VERSION ""

NS_ :

BS_:

BU_: XXX CAMERA FRONT_RADAR ADRV APRK

BO_ 234 MDPS: 32 XXX
 SG_ BYTE0 : 0|8@1+ (1,0) [0|255] "" XXX
 SG_ BYTE1 : 8|8@1+ (1,0) [0|255] "" XXX
 SG_ BYTE2 : 16|8@1+ (1,0) [0|255] "" XXX
 SG_ BYTE3 : 24|8@1+ (1,0) [0|255] "" XXX
 SG_ BYTE4 : 32|8@1+ (1,0) [0|255] "" XXX
 SG_ BYTE5 : 40|8@1+ (1,0) [0|255] "" XXX
 SG_ BYTE6 : 48|8@1+ (1,0) [0|255] "" XXX
 SG_ BYTE7 : 56|8@1+ (1,0) [0|255] "" XXX
 SG_ BYTE8 : 64|8@1+ (1,0) [0|255] "" XXX
 SG_ BYTE9 : 72|8@1+ (1,0) [0|255] "" XXX
 SG_ BYTE10 : 80|8@1+ (1,0) [0|255] "" XXX
 SG_ BYTE11 : 88|8@1+ (1,0) [0|255] "" XXX
 SG_ BYTE12 : 96|8@1+ (1,0) [0|255] "" XXX
 SG_ BYTE13 : 104|8@1+ (1,0) [0|255] "" XXX
 SG_ BYTE14 : 112|8@1+ (1,0) [0|255] "" XXX
 SG_ BYTE15 : 120|8@1+ (1,0) [0|255] "" XXX
 SG_ BYTE16 : 128|8@1+ (1,0) [0|255] "" XXX
 SG_ BYTE17 : 136|8@1+ (1,0) [0|255] "" XXX
 SG_ BYTE18 : 144|8@1+ (1,0) [0|255] "" XXX
 SG_ BYTE19 : 152|8@1+ (1,0) [0|255] "" XXX
 SG_ BYTE20 : 160|8@1+ (1,0) [0|255] "" XXX
 SG_ BYTE21 : 168|8@1+ (1,0) [0|255] "" XXX
 SG_ BYTE22 : 176|8@1+ (1,0) [0|255] "" XXX
 SG_ BYTE23 : 184|8@1+ (1,0) [0|255] "" XXX
 SG_ BYTE24 : 192|8@1+ (1,0) [0|255] "" XXX
 SG_ BYTE25 : 200|8@1+ (1,0) [0|255] "" XXX
 SG_ BYTE26 : 208|8@1+ (1,0) [0|255] "" XXX
 SG_ BYTE27 : 216|8@1+ (1,0) [0|255] "" XXX
 SG_ BYTE28 : 224|8@1+ (1,0) [0|255] "" XXX
 SG_ BYTE29 : 232|8@1+ (1,0) [0|255] "" XXX
 SG_ BYTE30 : 240|8@1+ (1,0) [0|255] "" XXX
 SG_ BYTE31 : 248|8@1+ (1,0) [0|255] "" XXX

BO_ 293 STEERING_SENSORS: 32 XXX
 SG_ BYTE0 : 0|8@1+ (1,0) [0|255] "" XXX
 SG_ BYTE1 : 8|8@1+ (1,0) [0|255] "" XXX
 SG_ BYTE2 : 16|8@1+ (1,0) [0|255] "" XXX
 SG_ BYTE3 : 24|8@1+ (1,0) [0|255] "" XXX
 SG_ BYTE4 : 32|8@1+ (1,0) [0|255] "" XXX
 SG_ BYTE5 : 40|8@1+ (1,0) [0|255] "" XXX
 SG_ BYTE6 : 48|8@1+ (1,0) [0|255] "" XXX
 SG_ BYTE7 : 56|8@1+ (1,0) [0|255] "" XXX
 SG_ BYTE8 : 64|8@1+ (1,0) [0|255] "" XXX
 SG_ BYTE9 : 72|8@1+ (1,0) [0|255] "" XXX
 SG_ BYTE10 : 80|8@1+ (1,0) [0|255] "" XXX
 SG_ BYTE11 : 88|8@1+ (1,0) [0|255] "" XXX
 SG_ BYTE12 : 96|8@1+ (1,0) [0|255] "" XXX
 SG_ BYTE13 : 104|8@1+ (1,0) [0|255] "" XXX
 SG_ BYTE14 : 112|8@1+ (1,0) [0|255] "" XXX
 SG_ BYTE15 : 120|8@1+ (1,0) [0|255] "" XXX
 SG_ BYTE16 : 128|8@1+ (1,0) [0|255] "" XXX
 SG_ BYTE17 : 136|8@1+ (1,0) [0|255] "" XXX
 SG_ BYTE18 : 144|8@1+ (1,0) [0|255] "" XXX
 SG_ BYTE19 : 152|8@1+ (1,0) [0|255] "" XXX
 SG_ BYTE20 : 160|8@1+ (1,0) [0|255] "" XXX
 SG_ BYTE21 : 168|8@1+ (1,0) [0|255] "" XXX
 SG_ BYTE22 : 176|8@1+ (1,0) [0|255] "" XXX
 SG_ BYTE23 : 184|8@1+ (1,0) [0|255] "" XXX
 SG_ BYTE24 : 192|8@1+ (1,0) [0|255] "" XXX
 SG_ BYTE25 : 200|8@1+ (1,0) [0|255] "" XXX
 SG_ BYTE26 : 208|8@1+ (1,0) [0|255] "" XXX
 SG_ BYTE27 : 216|8@1+ (1,0) [0|255] "" XXX
 SG_ BYTE28 : 224|8@1+ (1,0) [0|255] "" XXX
 SG_ BYTE29 : 232|8@1+ (1,0) [0|255] "" XXX
 SG_ BYTE30 : 240|8@1+ (1,0) [0|255] "" XXX
 SG_ BYTE31 : 248|8@1+ (1,0) [0|255] "" XXX

BO_ 373 TCS: 16 XXX
 SG_ BYTE0 : 0|8@1+ (1,0) [0|255] "" XXX
 SG_ BYTE1 : 8|8@1+ (1,0) [0|255] "" XXX
 SG_ BYTE2 : 16|8@1+ (1,0) [0|255] "" XXX
 SG_ BYTE3 : 24|8@1+ (1,0) [0|255] "" XXX
 SG_ BYTE4 : 32|8@1+ (1,0) [0|255] "" XXX
 SG_ BYTE5 : 40|8@1+ (1,0) [0|255] "" XXX
 SG_ BYTE6 : 48|8@1+ (1,0) [0|255] "" XXX
 SG_ BYTE7 : 56|8@1+ (1,0) [0|255] "" XXX
 SG_ BYTE8 : 64|8@1+ (1,0) [0|255] "" XXX
 SG_ BYTE9 : 72|8@1+ (1,0) [0|255] "" XXX
 SG_ BYTE10 : 80|8@1+ (1,0) [0|255] "" XXX
 SG_ BYTE11 : 88|8@1+ (1,0) [0|255] "" XXX
 SG_ BYTE12 : 96|8@1+ (1,0) [0|255] "" XXX
 SG_ BYTE13 : 104|8@1+ (1,0) [0|255] "" XXX
 SG_ BYTE14 : 112|8@1+ (1,0) [0|255] "" XXX
 SG_ BYTE15 : 120|8@1+ (1,0) [0|255] "" XXX

BO_ 304 GEAR_SHIFTER: 32 XXX
 SG_ BYTE0 : 0|8@1+ (1,0) [0|255] "" XXX
 SG_ BYTE1 : 8|8@1+ (1,0) [0|255] "" XXX
 SG_ BYTE2 : 16|8@1+ (1,0) [0|255] "" XXX
 SG_ BYTE3 : 24|8@1+ (1,0) [0|255] "" XXX
 SG_ BYTE4 : 32|8@1+ (1,0) [0|255] "" XXX
 SG_ BYTE5 : 40|8@1+ (1,0) [0|255] "" XXX
 SG_ BYTE6 : 48|8@1+ (1,0) [0|255] "" XXX
 SG_ BYTE7 : 56|8@1+ (1,0) [0|255] "" XXX
 SG_ BYTE8 : 64|8@1+ (1,0) [0|255] "" XXX
 SG_ BYTE9 : 72|8@1+ (1,0) [0|255] "" XXX
 SG_ BYTE10 : 80|8@1+ (1,0) [0|255] "" XXX
 SG_ BYTE11 : 88|8@1+ (1,0) [0|255] "" XXX
 SG_ BYTE12 : 96|8@1+ (1,0) [0|255] "" XXX
 SG_ BYTE13 : 104|8@1+ (1,0) [0|255] "" XXX
 SG_ BYTE14 : 112|8@1+ (1,0) [0|255] "" XXX
 SG_ BYTE15 : 120|8@1+ (1,0) [0|255] "" XXX
 SG_ BYTE16 : 128|8@1+ (1,0) [0|255] "" XXX
 SG_ BYTE17 : 136|8@1+ (1,0) [0|255] "" XXX
 SG_ BYTE18 : 144|8@1+ (1,0) [0|255] "" XXX
 SG_ BYTE19 : 152|8@1+ (1,0) [0|255] "" XXX
 SG_ BYTE20 : 160|8@1+ (1,0) [0|255] "" XXX
 SG_ BYTE21 : 168|8@1+ (1,0) [0|255] "" XXX
 SG_ BYTE22 : 176|8@1+ (1,0) [0|255] "" XXX
 SG_ BYTE23 : 184|8@1+ (1,0) [0|255] "" XXX
 SG_ BYTE24 : 192|8@1+ (1,0) [0|255] "" XXX
 SG_ BYTE25 : 200|8@1+ (1,0) [0|255] "" XXX
 SG_ BYTE26 : 208|8@1+ (1,0) [0|255] "" XXX
 SG_ BYTE27 : 216|8@1+ (1,0) [0|255] "" XXX
 SG_ BYTE28 : 224|8@1+ (1,0) [0|255] "" XXX
 SG_ BYTE29 : 232|8@1+ (1,0) [0|255] "" XXX
 SG_ BYTE30 : 240|8@1+ (1,0) [0|255] "" XXX
 SG_ BYTE31 : 248|8@1+ (1,0) [0|255] "" XXX

BO_ 864 LFA_BUTTON: 32 XXX
 SG_ LEFT_BLINKER : 0|8@1+ (1,0) [0|255] "" XXX
 SG_ RIGHT_BLINKER : 8|8@1+ (1,0) [0|255] "" XXX
 SG_ LFA_BTN : 16|1@1+ (1,0) [0|1] "" XXX
 SG_ BYTE3 : 24|8@1+ (1,0) [0|255] "" XXX
 SG_ BYTE4 : 32|8@1+ (1,0) [0|255] "" XXX
 SG_ BYTE5 : 40|8@1+ (1,0) [0|255] "" XXX
 SG_ BYTE6 : 48|8@1+ (1,0) [0|255] "" XXX
 SG_ BYTE7 : 56|8@1+ (1,0) [0|255] "" XXX
 SG_ BYTE8 : 64|8@1+ (1,0) [0|255] "" XXX
 SG_ BYTE9 : 72|8@1+ (1,0) [0|255] "" XXX
 SG_ BYTE10 : 80|8@1+ (1,0) [0|255] "" XXX
 SG_ BYTE11 : 88|8@1+ (1,0) [0|255] "" XXX
 SG_ BYTE12 : 96|8@1+ (1,0) [0|255] "" XXX
 SG_ BYTE13 : 104|8@1+ (1,0) [0|255] "" XXX
 SG_ BYTE14 : 112|8@1+ (1,0) [0|255] "" XXX
 SG_ BYTE15 : 120|8@1+ (1,0) [0|255] "" XXX
 SG_ BYTE16 : 128|8@1+ (1,0) [0|255] "" XXX
 SG_ BYTE17 : 136|8@1+ (1,0) [0|255] "" XXX
 SG_ BYTE18 : 144|8@1+ (1,0) [0|255] "" XXX
 SG_ BYTE19 : 152|8@1+ (1,0) [0|255] "" XXX
 SG_ BYTE20 : 160|8@1+ (1,0) [0|255] "" XXX
 SG_ BYTE21 : 168|8@1+ (1,0) [0|255] "" XXX
 SG_ BYTE22 : 176|8@1+ (1,0) [0|255] "" XXX
 SG_ BYTE23 : 184|8@1+ (1,0) [0|255] "" XXX
 SG_ BYTE24 : 192|8@1+ (1,0) [0|255] "" XXX
 SG_ BYTE25 : 200|8@1+ (1,0) [0|255] "" XXX
 SG_ BYTE26 : 208|8@1+ (1,0) [0|255] "" XXX
 SG_ BYTE27 : 216|8@1+ (1,0) [0|255] "" XXX
 SG_ BYTE28 : 224|8@1+ (1,0) [0|255] "" XXX
 SG_ BYTE29 : 232|8@1+ (1,0) [0|255] "" XXX
 SG_ BYTE30 : 240|8@1+ (1,0) [0|255] "" XXX
 SG_ BYTE31 : 248|8@1+ (1,0) [0|255] "" XXX

BO_ 976 EV4_BODY_1: 32 XXX
 SG_ DRIVER_SEATBELT : 0|1@1+ (1,0) [0|1] "" XXX
 SG_ SPEED_REF_1 : 8|16@1+ (0.01,0) [0|655.35] "" XXX
 SG_ BYTE3 : 24|8@1+ (1,0) [0|255] "" XXX
 SG_ BYTE4 : 32|8@1+ (1,0) [0|255] "" XXX
 SG_ BYTE5 : 40|8@1+ (1,0) [0|255] "" XXX
 SG_ BYTE6 : 48|8@1+ (1,0) [0|255] "" XXX
 SG_ BYTE7 : 56|8@1+ (1,0) [0|255] "" XXX
 SG_ BYTE8 : 64|8@1+ (1,0) [0|255] "" XXX
 SG_ BYTE9 : 72|8@1+ (1,0) [0|255] "" XXX
 SG_ BYTE10 : 80|8@1+ (1,0) [0|255] "" XXX
 SG_ BYTE11 : 88|8@1+ (1,0) [0|255] "" XXX
 SG_ BYTE12 : 96|8@1+ (1,0) [0|255] "" XXX
 SG_ BYTE13 : 104|8@1+ (1,0) [0|255] "" XXX
 SG_ BYTE14 : 112|8@1+ (1,0) [0|255] "" XXX
 SG_ BYTE15 : 120|8@1+ (1,0) [0|255] "" XXX
 SG_ BYTE16 : 128|8@1+ (1,0) [0|255] "" XXX
 SG_ BYTE17 : 136|8@1+ (1,0) [0|255] "" XXX
 SG_ BYTE18 : 144|8@1+ (1,0) [0|255] "" XXX
 SG_ BYTE19 : 152|8@1+ (1,0) [0|255] "" XXX
 SG_ BYTE20 : 160|8@1+ (1,0) [0|255] "" XXX
 SG_ BYTE21 : 168|8@1+ (1,0) [0|255] "" XXX
 SG_ BYTE22 : 176|8@1+ (1,0) [0|255] "" XXX
 SG_ BYTE23 : 184|8@1+ (1,0) [0|255] "" XXX
 SG_ BYTE24 : 192|8@1+ (1,0) [0|255] "" XXX
 SG_ BYTE25 : 200|8@1+ (1,0) [0|255] "" XXX
 SG_ BYTE26 : 208|8@1+ (1,0) [0|255] "" XXX
 SG_ BYTE27 : 216|8@1+ (1,0) [0|255] "" XXX
 SG_ BYTE28 : 224|8@1+ (1,0) [0|255] "" XXX
 SG_ BYTE29 : 232|8@1+ (1,0) [0|255] "" XXX
 SG_ BYTE30 : 240|8@1+ (1,0) [0|255] "" XXX
 SG_ BYTE31 : 248|8@1+ (1,0) [0|255] "" XXX

BO_ 979 EV4_BODY_2: 32 XXX
 SG_ DOOR_OPEN_ANY : 0|1@1+ (1,0) [0|1] "" XXX
 SG_ BYTE1 : 8|8@1+ (1,0) [0|255] "" XXX
 SG_ BYTE2 : 16|8@1+ (1,0) [0|255] "" XXX
 SG_ BYTE3 : 24|8@1+ (1,0) [0|255] "" XXX
 SG_ BYTE4 : 32|8@1+ (1,0) [0|255] "" XXX
 SG_ BYTE5 : 40|8@1+ (1,0) [0|255] "" XXX
 SG_ BYTE6 : 48|8@1+ (1,0) [0|255] "" XXX
 SG_ BYTE7 : 56|8@1+ (1,0) [0|255] "" XXX
 SG_ BYTE8 : 64|8@1+ (1,0) [0|255] "" XXX
 SG_ BYTE9 : 72|8@1+ (1,0) [0|255] "" XXX
 SG_ BYTE10 : 80|8@1+ (1,0) [0|255] "" XXX
 SG_ BYTE11 : 88|8@1+ (1,0) [0|255] "" XXX
 SG_ BYTE12 : 96|8@1+ (1,0) [0|255] "" XXX
 SG_ BYTE13 : 104|8@1+ (1,0) [0|255] "" XXX
 SG_ BYTE14 : 112|8@1+ (1,0) [0|255] "" XXX
 SG_ BYTE15 : 120|8@1+ (1,0) [0|255] "" XXX
 SG_ BYTE16 : 128|8@1+ (1,0) [0|255] "" XXX
 SG_ BYTE17 : 136|8@1+ (1,0) [0|255] "" XXX
 SG_ BYTE18 : 144|8@1+ (1,0) [0|255] "" XXX
 SG_ BYTE19 : 152|8@1+ (1,0) [0|255] "" XXX
 SG_ BYTE20 : 160|8@1+ (1,0) [0|255] "" XXX
 SG_ BYTE21 : 168|8@1+ (1,0) [0|255] "" XXX
 SG_ BYTE22 : 176|8@1+ (1,0) [0|255] "" XXX
 SG_ BYTE23 : 184|8@1+ (1,0) [0|255] "" XXX
 SG_ BYTE24 : 192|8@1+ (1,0) [0|255] "" XXX
 SG_ BYTE25 : 200|8@1+ (1,0) [0|255] "" XXX
 SG_ BYTE26 : 208|8@1+ (1,0) [0|255] "" XXX
 SG_ BYTE27 : 216|8@1+ (1,0) [0|255] "" XXX
 SG_ BYTE28 : 224|8@1+ (1,0) [0|255] "" XXX
 SG_ BYTE29 : 232|8@1+ (1,0) [0|255] "" XXX
 SG_ BYTE30 : 240|8@1+ (1,0) [0|255] "" XXX
 SG_ BYTE31 : 248|8@1+ (1,0) [0|255] "" XXX

BO_ 939 RADAR_TRACK_939: 24 XXX
 SG_ BYTE0 : 0|8@1+ (1,0) [0|255] "" XXX
 SG_ BYTE1 : 8|8@1+ (1,0) [0|255] "" XXX
 SG_ BYTE2 : 16|8@1+ (1,0) [0|255] "" XXX
 SG_ BYTE3 : 24|8@1+ (1,0) [0|255] "" XXX
 SG_ BYTE4 : 32|8@1+ (1,0) [0|255] "" XXX
 SG_ BYTE5 : 40|8@1+ (1,0) [0|255] "" XXX
 SG_ BYTE6 : 48|8@1+ (1,0) [0|255] "" XXX
 SG_ BYTE7 : 56|8@1+ (1,0) [0|255] "" XXX
 SG_ BYTE8 : 64|8@1+ (1,0) [0|255] "" XXX
 SG_ BYTE9 : 72|8@1+ (1,0) [0|255] "" XXX
 SG_ BYTE10 : 80|8@1+ (1,0) [0|255] "" XXX
 SG_ BYTE11 : 88|8@1+ (1,0) [0|255] "" XXX
 SG_ BYTE12 : 96|8@1+ (1,0) [0|255] "" XXX
 SG_ BYTE13 : 104|8@1+ (1,0) [0|255] "" XXX
 SG_ BYTE14 : 112|8@1+ (1,0) [0|255] "" XXX
 SG_ BYTE15 : 120|8@1+ (1,0) [0|255] "" XXX
 SG_ BYTE16 : 128|8@1+ (1,0) [0|255] "" XXX
 SG_ BYTE17 : 136|8@1+ (1,0) [0|255] "" XXX
 SG_ BYTE18 : 144|8@1+ (1,0) [0|255] "" XXX
 SG_ BYTE19 : 152|8@1+ (1,0) [0|255] "" XXX
 SG_ BYTE20 : 160|8@1+ (1,0) [0|255] "" XXX
 SG_ BYTE21 : 168|8@1+ (1,0) [0|255] "" XXX
 SG_ BYTE22 : 176|8@1+ (1,0) [0|255] "" XXX
 SG_ BYTE23 : 184|8@1+ (1,0) [0|255] "" XXX

BO_ 53 ACCELERATOR: 32 XXX
 SG_ CHECKSUM_T : 0|16@1+ (1,0) [0|65535] "" XXX
 SG_ COUNTER_T : 16|8@1+ (1,0) [0|255] "" XXX
 SG_ ACCELERATOR_PEDAL : 40|8@1+ (1,0) [0|255] "" XXX
 SG_ GEAR : 192|3@1+ (1,0) [0|7] "" XXX

BO_ 64 GEAR_ALT: 32 XXX
 SG_ CHECKSUM_T : 0|16@1+ (1,0) [0|65535] "" XXX
 SG_ COUNTER_T : 16|8@1+ (1,0) [0|255] "" XXX
 SG_ GEAR : 32|3@1+ (1,0) [0|7] "" XXX

BO_ 69 GEAR: 24 XXX
 SG_ CHECKSUM_T : 0|16@1+ (1,0) [0|65535] "" XXX
 SG_ COUNTER_T : 16|8@1+ (1,0) [0|255] "" XXX
 SG_ GEAR : 44|3@1+ (1,0) [0|7] "" XXX

BO_ 96 ESP_STATUS: 32 XXX
 SG_ CHECKSUM_T : 0|16@1+ (1,0) [0|65535] "" XXX
 SG_ COUNTER_T : 16|8@1+ (1,0) [0|255] "" XXX
 SG_ TRACTION_AND_STABILITY_CONTROL : 42|3@1+ (1,0) [0|63] "" XXX
 SG_ BRAKE_PRESSURE : 128|10@1+ (1,0) [0|65535] "" XXX
 SG_ BRAKE_PRESSED : 148|1@1+ (1,0) [0|3] "" XXX

BO_ 101 BRAKE: 32 XXX
 SG_ CHECKSUM_T : 0|16@1+ (1,0) [0|65535] "" XXX
 SG_ COUNTER_T : 16|8@1+ (1,0) [0|255] "" XXX
 SG_ BRAKE_POSITION : 40|16@1- (1,0) [0|65535] "" XXX
 SG_ BRAKE_PRESSED : 57|1@1+ (1,0) [0|3] "" XXX

BO_ 160 WHEEL_SPEEDS: 24 XXX
 SG_ BYTE0 : 0|8@1+ (1,0) [0|255] "" XXX
 SG_ BYTE1 : 8|8@1+ (1,0) [0|255] "" XXX
 SG_ BYTE2 : 16|8@1+ (1,0) [0|255] "" XXX
 SG_ BYTE3 : 24|8@1+ (1,0) [0|255] "" XXX
 SG_ BYTE4 : 32|8@1+ (1,0) [0|255] "" XXX
 SG_ BYTE5 : 40|8@1+ (1,0) [0|255] "" XXX
 SG_ BYTE6 : 48|8@1+ (1,0) [0|255] "" XXX
 SG_ BYTE7 : 56|8@1+ (1,0) [0|255] "" XXX
 SG_ BYTE8 : 64|8@1+ (1,0) [0|255] "" XXX
 SG_ BYTE9 : 72|8@1+ (1,0) [0|255] "" XXX
 SG_ BYTE10 : 80|8@1+ (1,0) [0|255] "" XXX
 SG_ BYTE11 : 88|8@1+ (1,0) [0|255] "" XXX
 SG_ BYTE12 : 96|8@1+ (1,0) [0|255] "" XXX
 SG_ BYTE13 : 104|8@1+ (1,0) [0|255] "" XXX
 SG_ BYTE14 : 112|8@1+ (1,0) [0|255] "" XXX
 SG_ BYTE15 : 120|8@1+ (1,0) [0|255] "" XXX
 SG_ BYTE16 : 128|8@1+ (1,0) [0|255] "" XXX
 SG_ BYTE17 : 136|8@1+ (1,0) [0|255] "" XXX
 SG_ BYTE18 : 144|8@1+ (1,0) [0|255] "" XXX
 SG_ BYTE19 : 152|8@1+ (1,0) [0|255] "" XXX
 SG_ BYTE20 : 160|8@1+ (1,0) [0|255] "" XXX
 SG_ BYTE21 : 168|8@1+ (1,0) [0|255] "" XXX
 SG_ BYTE22 : 176|8@1+ (1,0) [0|255] "" XXX
 SG_ BYTE23 : 184|8@1+ (1,0) [0|255] "" XXX

BO_ 256 ACCELERATOR_BRAKE_ALT: 24 XXX
 SG_ BYTE0 : 0|8@1+ (1,0) [0|255] "" XXX
 SG_ BYTE1 : 8|8@1+ (1,0) [0|255] "" XXX
 SG_ BYTE2 : 16|8@1+ (1,0) [0|255] "" XXX
 SG_ BYTE3 : 24|8@1+ (1,0) [0|255] "" XXX
 SG_ BYTE4 : 32|8@1+ (1,0) [0|255] "" XXX
 SG_ BYTE5 : 40|8@1+ (1,0) [0|255] "" XXX
 SG_ BYTE6 : 48|8@1+ (1,0) [0|255] "" XXX
 SG_ BYTE7 : 56|8@1+ (1,0) [0|255] "" XXX
 SG_ BYTE8 : 64|8@1+ (1,0) [0|255] "" XXX
 SG_ BYTE9 : 72|8@1+ (1,0) [0|255] "" XXX
 SG_ BYTE10 : 80|8@1+ (1,0) [0|255] "" XXX
 SG_ BYTE11 : 88|8@1+ (1,0) [0|255] "" XXX
 SG_ BYTE12 : 96|8@1+ (1,0) [0|255] "" XXX
 SG_ BYTE13 : 104|8@1+ (1,0) [0|255] "" XXX
 SG_ BYTE14 : 112|8@1+ (1,0) [0|255] "" XXX
 SG_ BYTE15 : 120|8@1+ (1,0) [0|255] "" XXX
 SG_ BYTE16 : 128|8@1+ (1,0) [0|255] "" XXX
 SG_ BYTE17 : 136|8@1+ (1,0) [0|255] "" XXX
 SG_ BYTE18 : 144|8@1+ (1,0) [0|255] "" XXX
 SG_ BYTE19 : 152|8@1+ (1,0) [0|255] "" XXX
 SG_ BYTE20 : 160|8@1+ (1,0) [0|255] "" XXX
 SG_ BYTE21 : 168|8@1+ (1,0) [0|255] "" XXX
 SG_ BYTE22 : 176|8@1+ (1,0) [0|255] "" XXX
 SG_ BYTE23 : 184|8@1+ (1,0) [0|255] "" XXX

BO_ 272 LKAS_ALT: 32 XXX
 SG_ LKA_MODE : 24|4@1+ (1,0) [0|15] "" XXX
 SG_ LKA_ICON : 28|4@1+ (1,0) [0|15] "" XXX
 SG_ TORQUE_REQUEST : 32|11@1- (1,0) [-1024|1023] "" XXX
 SG_ LKA_ASSIST : 43|1@1+ (1,0) [0|1] "" XXX
 SG_ STEER_REQ : 44|1@1+ (1,0) [0|1] "" XXX
 SG_ STEER_MODE : 45|3@1+ (1,0) [0|7] "" XXX
 SG_ HAS_LANE_SAFETY : 48|1@1+ (1,0) [0|1] "" XXX
 SG_ LKA_AVAILABLE : 27|2@1+ (1,0) [0|3] "" XXX
 SG_ CHECKSUM : 0|16@1+ (1,0) [0|65535] "" XXX
 SG_ COUNTER : 16|8@1+ (1,0) [0|255] "" XXX
 SG_ BYTE0 : 0|8@1+ (1,0) [0|255] "" XXX
 SG_ BYTE1 : 8|8@1+ (1,0) [0|255] "" XXX
 SG_ BYTE2 : 16|8@1+ (1,0) [0|255] "" XXX
 SG_ BYTE3 : 24|8@1+ (1,0) [0|255] "" XXX
 SG_ BYTE4 : 32|8@1+ (1,0) [0|255] "" XXX
 SG_ BYTE5 : 40|8@1+ (1,0) [0|255] "" XXX
 SG_ BYTE6 : 48|8@1+ (1,0) [0|255] "" XXX
 SG_ BYTE7 : 56|8@1+ (1,0) [0|255] "" XXX
 SG_ BYTE8 : 64|8@1+ (1,0) [0|255] "" XXX
 SG_ BYTE9 : 72|8@1+ (1,0) [0|255] "" XXX
 SG_ BYTE10 : 80|8@1+ (1,0) [0|255] "" XXX
 SG_ BYTE11 : 88|8@1+ (1,0) [0|255] "" XXX
 SG_ BYTE12 : 96|8@1+ (1,0) [0|255] "" XXX
 SG_ BYTE13 : 104|8@1+ (1,0) [0|255] "" XXX
 SG_ BYTE14 : 112|8@1+ (1,0) [0|255] "" XXX
 SG_ BYTE15 : 120|8@1+ (1,0) [0|255] "" XXX
 SG_ BYTE16 : 128|8@1+ (1,0) [0|255] "" XXX
 SG_ BYTE17 : 136|8@1+ (1,0) [0|255] "" XXX
 SG_ BYTE18 : 144|8@1+ (1,0) [0|255] "" XXX
 SG_ BYTE19 : 152|8@1+ (1,0) [0|255] "" XXX
 SG_ BYTE20 : 160|8@1+ (1,0) [0|255] "" XXX
 SG_ BYTE21 : 168|8@1+ (1,0) [0|255] "" XXX
 SG_ BYTE22 : 176|8@1+ (1,0) [0|255] "" XXX
 SG_ BYTE23 : 184|8@1+ (1,0) [0|255] "" XXX
 SG_ BYTE24 : 192|8@1+ (1,0) [0|255] "" XXX
 SG_ BYTE25 : 200|8@1+ (1,0) [0|255] "" XXX
 SG_ BYTE26 : 208|8@1+ (1,0) [0|255] "" XXX
 SG_ BYTE27 : 216|8@1+ (1,0) [0|255] "" XXX
 SG_ BYTE28 : 224|8@1+ (1,0) [0|255] "" XXX
 SG_ BYTE29 : 232|8@1+ (1,0) [0|255] "" XXX
 SG_ BYTE30 : 240|8@1+ (1,0) [0|255] "" XXX
 SG_ BYTE31 : 248|8@1+ (1,0) [0|255] "" XXX

BO_ 357 ADRV_0x165: 16 XXX
 SG_ BYTE0 : 0|8@1+ (1,0) [0|255] "" XXX
 SG_ BYTE1 : 8|8@1+ (1,0) [0|255] "" XXX
 SG_ BYTE2 : 16|8@1+ (1,0) [0|255] "" XXX
 SG_ BYTE3 : 24|8@1+ (1,0) [0|255] "" XXX
 SG_ BYTE4 : 32|8@1+ (1,0) [0|255] "" XXX
 SG_ BYTE5 : 40|8@1+ (1,0) [0|255] "" XXX
 SG_ BYTE6 : 48|8@1+ (1,0) [0|255] "" XXX
 SG_ BYTE7 : 56|8@1+ (1,0) [0|255] "" XXX
 SG_ BYTE8 : 64|8@1+ (1,0) [0|255] "" XXX
 SG_ BYTE9 : 72|8@1+ (1,0) [0|255] "" XXX
 SG_ BYTE10 : 80|8@1+ (1,0) [0|255] "" XXX
 SG_ BYTE11 : 88|8@1+ (1,0) [0|255] "" XXX
 SG_ BYTE12 : 96|8@1+ (1,0) [0|255] "" XXX
 SG_ BYTE13 : 104|8@1+ (1,0) [0|255] "" XXX
 SG_ BYTE14 : 112|8@1+ (1,0) [0|255] "" XXX
 SG_ BYTE15 : 120|8@1+ (1,0) [0|255] "" XXX

BO_ 576 HBA_0x240: 32 XXX
 SG_ BYTE0 : 0|8@1+ (1,0) [0|255] "" XXX
 SG_ BYTE1 : 8|8@1+ (1,0) [0|255] "" XXX
 SG_ BYTE2 : 16|8@1+ (1,0) [0|255] "" XXX
 SG_ BYTE3 : 24|8@1+ (1,0) [0|255] "" XXX
 SG_ BYTE4 : 32|8@1+ (1,0) [0|255] "" XXX
 SG_ BYTE5 : 40|8@1+ (1,0) [0|255] "" XXX
 SG_ BYTE6 : 48|8@1+ (1,0) [0|255] "" XXX
 SG_ BYTE7 : 56|8@1+ (1,0) [0|255] "" XXX
 SG_ BYTE8 : 64|8@1+ (1,0) [0|255] "" XXX
 SG_ BYTE9 : 72|8@1+ (1,0) [0|255] "" XXX
 SG_ BYTE10 : 80|8@1+ (1,0) [0|255] "" XXX
 SG_ BYTE11 : 88|8@1+ (1,0) [0|255] "" XXX
 SG_ BYTE12 : 96|8@1+ (1,0) [0|255] "" XXX
 SG_ BYTE13 : 104|8@1+ (1,0) [0|255] "" XXX
 SG_ BYTE14 : 112|8@1+ (1,0) [0|255] "" XXX
 SG_ BYTE15 : 120|8@1+ (1,0) [0|255] "" XXX
 SG_ BYTE16 : 128|8@1+ (1,0) [0|255] "" XXX
 SG_ BYTE17 : 136|8@1+ (1,0) [0|255] "" XXX
 SG_ BYTE18 : 144|8@1+ (1,0) [0|255] "" XXX
 SG_ BYTE19 : 152|8@1+ (1,0) [0|255] "" XXX
 SG_ BYTE20 : 160|8@1+ (1,0) [0|255] "" XXX
 SG_ BYTE21 : 168|8@1+ (1,0) [0|255] "" XXX
 SG_ BYTE22 : 176|8@1+ (1,0) [0|255] "" XXX
 SG_ BYTE23 : 184|8@1+ (1,0) [0|255] "" XXX
 SG_ BYTE24 : 192|8@1+ (1,0) [0|255] "" XXX
 SG_ BYTE25 : 200|8@1+ (1,0) [0|255] "" XXX
 SG_ BYTE26 : 208|8@1+ (1,0) [0|255] "" XXX
 SG_ BYTE27 : 216|8@1+ (1,0) [0|255] "" XXX
 SG_ BYTE28 : 224|8@1+ (1,0) [0|255] "" XXX
 SG_ BYTE29 : 232|8@1+ (1,0) [0|255] "" XXX
 SG_ BYTE30 : 240|8@1+ (1,0) [0|255] "" XXX
 SG_ BYTE31 : 248|8@1+ (1,0) [0|255] "" XXX

BO_ 866 CAM_0x362: 32 XXX
 SG_ BYTE0 : 0|8@1+ (1,0) [0|255] "" XXX
 SG_ BYTE1 : 8|8@1+ (1,0) [0|255] "" XXX
 SG_ BYTE2 : 16|8@1+ (1,0) [0|255] "" XXX
 SG_ BYTE3 : 24|8@1+ (1,0) [0|255] "" XXX
 SG_ BYTE4 : 32|8@1+ (1,0) [0|255] "" XXX
 SG_ BYTE5 : 40|8@1+ (1,0) [0|255] "" XXX
 SG_ BYTE6 : 48|8@1+ (1,0) [0|255] "" XXX
 SG_ BYTE7 : 56|8@1+ (1,0) [0|255] "" XXX
 SG_ BYTE8 : 64|8@1+ (1,0) [0|255] "" XXX
 SG_ BYTE9 : 72|8@1+ (1,0) [0|255] "" XXX
 SG_ BYTE10 : 80|8@1+ (1,0) [0|255] "" XXX
 SG_ BYTE11 : 88|8@1+ (1,0) [0|255] "" XXX
 SG_ BYTE12 : 96|8@1+ (1,0) [0|255] "" XXX
 SG_ BYTE13 : 104|8@1+ (1,0) [0|255] "" XXX
 SG_ BYTE14 : 112|8@1+ (1,0) [0|255] "" XXX
 SG_ BYTE15 : 120|8@1+ (1,0) [0|255] "" XXX
 SG_ BYTE16 : 128|8@1+ (1,0) [0|255] "" XXX
 SG_ BYTE17 : 136|8@1+ (1,0) [0|255] "" XXX
 SG_ BYTE18 : 144|8@1+ (1,0) [0|255] "" XXX
 SG_ BYTE19 : 152|8@1+ (1,0) [0|255] "" XXX
 SG_ BYTE20 : 160|8@1+ (1,0) [0|255] "" XXX
 SG_ BYTE21 : 168|8@1+ (1,0) [0|255] "" XXX
 SG_ BYTE22 : 176|8@1+ (1,0) [0|255] "" XXX
 SG_ BYTE23 : 184|8@1+ (1,0) [0|255] "" XXX
 SG_ BYTE24 : 192|8@1+ (1,0) [0|255] "" XXX
 SG_ BYTE25 : 200|8@1+ (1,0) [0|255] "" XXX
 SG_ BYTE26 : 208|8@1+ (1,0) [0|255] "" XXX
 SG_ BYTE27 : 216|8@1+ (1,0) [0|255] "" XXX
 SG_ BYTE28 : 224|8@1+ (1,0) [0|255] "" XXX
 SG_ BYTE29 : 232|8@1+ (1,0) [0|255] "" XXX
 SG_ BYTE30 : 240|8@1+ (1,0) [0|255] "" XXX
 SG_ BYTE31 : 248|8@1+ (1,0) [0|255] "" XXX

BO_ 867 CAM_0x363: 32 XXX
 SG_ BYTE0 : 0|8@1+ (1,0) [0|255] "" XXX
 SG_ BYTE1 : 8|8@1+ (1,0) [0|255] "" XXX
 SG_ BYTE2 : 16|8@1+ (1,0) [0|255] "" XXX
 SG_ BYTE3 : 24|8@1+ (1,0) [0|255] "" XXX
 SG_ BYTE4 : 32|8@1+ (1,0) [0|255] "" XXX
 SG_ BYTE5 : 40|8@1+ (1,0) [0|255] "" XXX
 SG_ BYTE6 : 48|8@1+ (1,0) [0|255] "" XXX
 SG_ BYTE7 : 56|8@1+ (1,0) [0|255] "" XXX
 SG_ BYTE8 : 64|8@1+ (1,0) [0|255] "" XXX
 SG_ BYTE9 : 72|8@1+ (1,0) [0|255] "" XXX
 SG_ BYTE10 : 80|8@1+ (1,0) [0|255] "" XXX
 SG_ BYTE11 : 88|8@1+ (1,0) [0|255] "" XXX
 SG_ BYTE12 : 96|8@1+ (1,0) [0|255] "" XXX
 SG_ BYTE13 : 104|8@1+ (1,0) [0|255] "" XXX
 SG_ BYTE14 : 112|8@1+ (1,0) [0|255] "" XXX
 SG_ BYTE15 : 120|8@1+ (1,0) [0|255] "" XXX
 SG_ BYTE16 : 128|8@1+ (1,0) [0|255] "" XXX
 SG_ BYTE17 : 136|8@1+ (1,0) [0|255] "" XXX
 SG_ BYTE18 : 144|8@1+ (1,0) [0|255] "" XXX
 SG_ BYTE19 : 152|8@1+ (1,0) [0|255] "" XXX
 SG_ BYTE20 : 160|8@1+ (1,0) [0|255] "" XXX
 SG_ BYTE21 : 168|8@1+ (1,0) [0|255] "" XXX
 SG_ BYTE22 : 176|8@1+ (1,0) [0|255] "" XXX
 SG_ BYTE23 : 184|8@1+ (1,0) [0|255] "" XXX
 SG_ BYTE24 : 192|8@1+ (1,0) [0|255] "" XXX
 SG_ BYTE25 : 200|8@1+ (1,0) [0|255] "" XXX
 SG_ BYTE26 : 208|8@1+ (1,0) [0|255] "" XXX
 SG_ BYTE27 : 216|8@1+ (1,0) [0|255] "" XXX
 SG_ BYTE28 : 224|8@1+ (1,0) [0|255] "" XXX
 SG_ BYTE29 : 232|8@1+ (1,0) [0|255] "" XXX
 SG_ BYTE30 : 240|8@1+ (1,0) [0|255] "" XXX
 SG_ BYTE31 : 248|8@1+ (1,0) [0|255] "" XXX

BO_ 868 CAM_0x364: 32 XXX
 SG_ BYTE0 : 0|8@1+ (1,0) [0|255] "" XXX
 SG_ BYTE1 : 8|8@1+ (1,0) [0|255] "" XXX
 SG_ BYTE2 : 16|8@1+ (1,0) [0|255] "" XXX
 SG_ BYTE3 : 24|8@1+ (1,0) [0|255] "" XXX
 SG_ BYTE4 : 32|8@1+ (1,0) [0|255] "" XXX
 SG_ BYTE5 : 40|8@1+ (1,0) [0|255] "" XXX
 SG_ BYTE6 : 48|8@1+ (1,0) [0|255] "" XXX
 SG_ BYTE7 : 56|8@1+ (1,0) [0|255] "" XXX
 SG_ BYTE8 : 64|8@1+ (1,0) [0|255] "" XXX
 SG_ BYTE9 : 72|8@1+ (1,0) [0|255] "" XXX
 SG_ BYTE10 : 80|8@1+ (1,0) [0|255] "" XXX
 SG_ BYTE11 : 88|8@1+ (1,0) [0|255] "" XXX
 SG_ BYTE12 : 96|8@1+ (1,0) [0|255] "" XXX
 SG_ BYTE13 : 104|8@1+ (1,0) [0|255] "" XXX
 SG_ BYTE14 : 112|8@1+ (1,0) [0|255] "" XXX
 SG_ BYTE15 : 120|8@1+ (1,0) [0|255] "" XXX
 SG_ BYTE16 : 128|8@1+ (1,0) [0|255] "" XXX
 SG_ BYTE17 : 136|8@1+ (1,0) [0|255] "" XXX
 SG_ BYTE18 : 144|8@1+ (1,0) [0|255] "" XXX
 SG_ BYTE19 : 152|8@1+ (1,0) [0|255] "" XXX
 SG_ BYTE20 : 160|8@1+ (1,0) [0|255] "" XXX
 SG_ BYTE21 : 168|8@1+ (1,0) [0|255] "" XXX
 SG_ BYTE22 : 176|8@1+ (1,0) [0|255] "" XXX
 SG_ BYTE23 : 184|8@1+ (1,0) [0|255] "" XXX
 SG_ BYTE24 : 192|8@1+ (1,0) [0|255] "" XXX
 SG_ BYTE25 : 200|8@1+ (1,0) [0|255] "" XXX
 SG_ BYTE26 : 208|8@1+ (1,0) [0|255] "" XXX
 SG_ BYTE27 : 216|8@1+ (1,0) [0|255] "" XXX
 SG_ BYTE28 : 224|8@1+ (1,0) [0|255] "" XXX
 SG_ BYTE29 : 232|8@1+ (1,0) [0|255] "" XXX
 SG_ BYTE30 : 240|8@1+ (1,0) [0|255] "" XXX
 SG_ BYTE31 : 248|8@1+ (1,0) [0|255] "" XXX

BO_ 961 RADAR_TRACK_961: 24 XXX
 SG_ BYTE0 : 0|8@1+ (1,0) [0|255] "" XXX
 SG_ BYTE1 : 8|8@1+ (1,0) [0|255] "" XXX
 SG_ BYTE2 : 16|8@1+ (1,0) [0|255] "" XXX
 SG_ BYTE3 : 24|8@1+ (1,0) [0|255] "" XXX
 SG_ BYTE4 : 32|8@1+ (1,0) [0|255] "" XXX
 SG_ BYTE5 : 40|8@1+ (1,0) [0|255] "" XXX
 SG_ BYTE6 : 48|8@1+ (1,0) [0|255] "" XXX
 SG_ BYTE7 : 56|8@1+ (1,0) [0|255] "" XXX
 SG_ BYTE8 : 64|8@1+ (1,0) [0|255] "" XXX
 SG_ BYTE9 : 72|8@1+ (1,0) [0|255] "" XXX
 SG_ BYTE10 : 80|8@1+ (1,0) [0|255] "" XXX
 SG_ BYTE11 : 88|8@1+ (1,0) [0|255] "" XXX
 SG_ BYTE12 : 96|8@1+ (1,0) [0|255] "" XXX
 SG_ BYTE13 : 104|8@1+ (1,0) [0|255] "" XXX
 SG_ BYTE14 : 112|8@1+ (1,0) [0|255] "" XXX
 SG_ BYTE15 : 120|8@1+ (1,0) [0|255] "" XXX
 SG_ BYTE16 : 128|8@1+ (1,0) [0|255] "" XXX
 SG_ BYTE17 : 136|8@1+ (1,0) [0|255] "" XXX
 SG_ BYTE18 : 144|8@1+ (1,0) [0|255] "" XXX
 SG_ BYTE19 : 152|8@1+ (1,0) [0|255] "" XXX
 SG_ BYTE20 : 160|8@1+ (1,0) [0|255] "" XXX
 SG_ BYTE21 : 168|8@1+ (1,0) [0|255] "" XXX
 SG_ BYTE22 : 176|8@1+ (1,0) [0|255] "" XXX
 SG_ BYTE23 : 184|8@1+ (1,0) [0|255] "" XXX

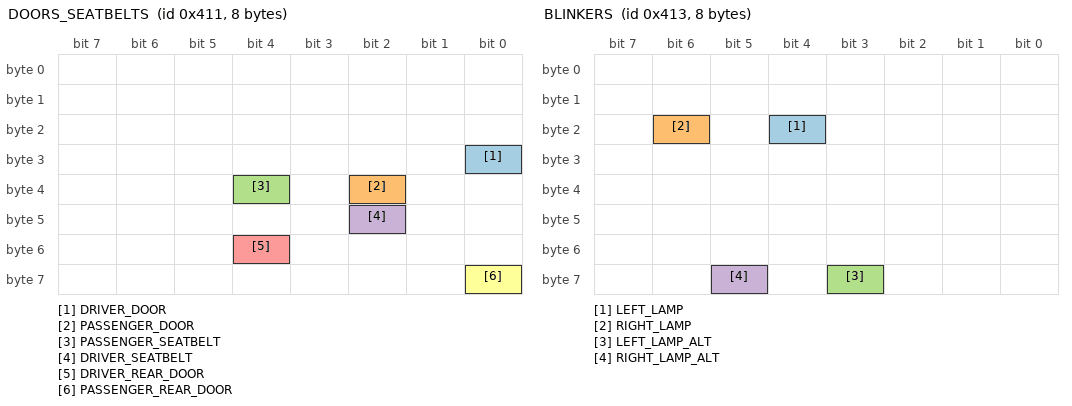
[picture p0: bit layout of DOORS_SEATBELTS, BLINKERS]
BO_ 1041 DOORS_SEATBELTS: 8 XXX
 SG_ DRIVER_DOOR : 24|1@1+ (1,0) [0|1] "" XXX
 SG_ PASSENGER_DOOR : 34|1@0+ (1,0) [0|1] "" XXX
 SG_ PASSENGER_SEATBELT : 36|1@0+ (1,0) [0|1] "" XXX
 SG_ DRIVER_SEATBELT : 42|1@0+ (1,0) [0|1] "" XXX
 SG_ DRIVER_REAR_DOOR : 52|1@0+ (1,0) [0|1] "" XXX
 SG_ PASSENGER_REAR_DOOR : 56|1@0+ (1,0) [0|1] "" XXX

CM_ "AUTOGENERATED FILE, DO NOT EDIT";
CM_ "Imported file _hyundai_canfd_common.dbc starts here";
CM_ BO_ 676 "Contains signals with detailed lane line information. Used by ADAS ECU on HDA 2 vehicles to operate LFA.";

CM_ SG_ 80 HAS_LANE_SAFETY "If 0, hides LKAS 'Lane Safety' menu from vehicle settings";
CM_ SG_ 676 LEFT_LANE_LINE "Left lane line confidence";
CM_ SG_ 676 RIGHT_LANE_LINE "Right lane line confidence";

CM_ "hyundai_canfd.dbc starts here";

CM_ SG_ 96 BRAKE_PRESSURE "User applied brake pedal pressure. Ramps from computer applied pressure on falling edge of cruise. Cruise cancels if !=0";
CM_ SG_ 101 BRAKE_POSITION "User applied brake pedal position, max is ~700. Signed on some vehicles";
CM_ SG_ 203 ADAS_ActvACISta "ADAS Active AngleControlInterface State";
CM_ SG_ 203 ADAS_ActvACILvl2Sta "ADAS Active AngleControlInterface Level 2 State";
CM_ SG_ 203 ADAS_StrAnglReqVal "(LFA) ADAS Steering Angle Request Value; Capped at 119.9;";
CM_ SG_ 203 ADAS_ACIAnglTqRedcGainVal "(LFA) ADAS AngleControlInterface Angle Torque Reduction Gain Value";
CM_ SG_ 203 FCA_ESA_ActvSta "FCA_ESA Active State";
CM_ SG_ 203 FCA_ESA_TqBstGainVal "FCA_ESA Torque Boost Gain Value";
CM_ BO_ 272 "Alternative LKAS message, used on cars such as 2023 Ioniq 6, 2nd gen Kona. Matches LKAS except size is 32 bytes";
CM_ SG_ 272 LKA_AVAILABLE "Angle control cars: 3 when LKA is generally available, goes to 0 during changes with LFA";
CM_ SG_ 272 ADAS_StrAnglReqVal "(LKAS) ADAS Steering Angle Request Value; Capped at 176.7; tracks MDPS->STEERING_ANGLE when not engaged, not STEERING_SENSORS->STEERING_ANGLE";
CM_ SG_ 272 ADAS_ACIAnglTqRedcGainVal "(LKAS) ADAS AngleControlInterface Angle Torque Reduction Gain Value";
CM_ BO_ 282 "Sent by the camera containing DAW (Driver Attention Warning) information and information about HBA (High Beam Assist).";
CM_ SG_ 282 FR_CMR_Crc1Val "The data area for CRC calculation is based on the data length (DLC) of the message DB. The CRC shall be calculated over the entire data block (excluding the CRC bytes) including the user data, alive counter and Data ID - CRC Polynomial (0x1021) , In";
CM_ SG_ 282 FR_CMR_AlvCnt1Val "For the first transmission request for a data element the counter shall be initialized with 0 and shall be incremented by 1 for every subsequent send request. When the counter reaches the maximum value(0xFF), then it shall restart with 0 for the next s";
CM_ SG_ 282 HBA_SysOptSta "HBA System Option Information to Lamp Controller";
CM_ SG_ 282 HBA_SysSta "This signal indicates the status of High Beam Assist system.";
CM_ SG_ 282 HBA_IndLmpReq "HBA System Indicator Lamp Status";
CM_ SG_ 282 FCA_Equip_MFC "FCA Sensor Type";
CM_ SG_ 282 HBA_OptUsmSta "HBA Option USM Status";
CM_ SG_ 282 DAW_LVDA_PUDis "Message for displaying LVDA(Leading Vehicle Departure Alert) Warning";
CM_ SG_ 282 DAW_LVDA_OptUsmSta "LVDA USM state";
CM_ SG_ 282 DAW_OptUsmSta "This signal represents the lastest DAW ON/OFF value of USM.";
CM_ SG_ 282 DAW_SysSta "This signal represents Attention Assist System Status or Attention Level.";
CM_ SG_ 282 DAW_WrnMsgSta "0x1 value requests DAW Rest recommend warning message popup at CLU. 0x2 value requests HDA/LFA Hands-Off call at TMS.";
CM_ SG_ 282 DAW_TimeRstReq "This signal requests CLU 'Last Break Time' Reset. DAW send '0x1' when detecting driver's rest.";
CM_ SG_ 282 DAW_SnstvtyModRetVal "This signal represents the feedback value of the current ADAS warning timing.";
CM_ SG_ 282 FR_CMR_SCCEquipSta "This signal indicates equipment for SCC";
CM_ SG_ 282 FR_CMR_ReqADASMapMsgVal "This signal indicates an ADAS map message request from FR_CMR to H_U. Each bit indicates the request messages as follows. - Bit 0 : H_U_NAVI_V2_STUB_E - Bit 1 : HU_NAVI_V2_PROSHORT_E_00 (곡률) - Bit 2 : HU_NAVI_V2_PROSHORT_E_00 (곡률 ???�보)";
CM_ SG_ 282 FR_CMR_SwVer1Val "This signal indicates a major version of FR_CMR software. If FR_CMR software version is A.00, 'A' and '00' mean major and minor version respectively.";
CM_ SG_ 282 FR_CMR_SwVer2Val "This signal indicates a minor version of FR_CMR software. If FR_CMR software version is A.00, 'A' and '00' mean major and minor version respectively.";
CM_ SG_ 298 NEW_SIGNAL_4 "todo: figure out why always set to 9";
CM_ SG_ 352 SET_ME_9 "has something to do with AEB settings";
CM_ SG_ 373 ACCEnable "Likely a copy of CAN's TCS13->ACCEnable";
CM_ SG_ 373 DriverBraking "Likely derived from BRAKE->BRAKE_POSITION";
CM_ SG_ 373 DriverBrakingLowSens "Higher threshold version of DriverBraking";
CM_ SG_ 373 PROBABLY_EQUIP "aeb equip?";
CM_ SG_ 416 VSetDis "set speed in display units";
CM_ BO_ 437 "Sent by the camera containing lane and lead information.";
CM_ SG_ 437 FR_CMR_Crc3Val "The data area for CRC calculation is based on the data length (DLC) of the message DB. The CRC shall be calculated over the entire data block (excluding the CRC bytes) including the user data, alive counter and Data ID - CRC Polynomial (0x1021) , In";
CM_ SG_ 437 FR_CMR_AlvCnt3Val "For the first transmission request for a data element the counter shall be initialized with 0 and shall be incremented by 1 for every subsequent send request. When the counter reaches the maximum value(0xFF), then it shall restart with 0 for the next s";
CM_ SG_ 437 Info_LftLnQualSta "This signal indicates the quality of left line.";
CM_ SG_ 437 Info_LftLnDptSta "This signal indicates the lane departure status of left line.";
CM_ SG_ 437 Info_LftLnPosVal "This signal outputs the position of left line from camera center.";
CM_ SG_ 437 Info_LftLnHdingAnglVal "This signal outputs the heading angle of left line.";
CM_ SG_ 437 Info_LftLnCvtrVal "This signal outputs the curvature of left line.";
CM_ SG_ 437 Info_RtLnQualSta "This signal indicates the quality of right line.";
CM_ SG_ 437 Info_RtLnDptSta "This signal indicates the lane departure status of right line.";
CM_ SG_ 437 Info_RtLnPosVal "This signal outputs the position of right line from camera center.";
CM_ SG_ 437 Info_RtLnHdingAnglVal "This signal outputs the heading angle of right line.";
CM_ SG_ 437 Info_RtLnCvtrVal "This signal outputs the curvature of right line.";
CM_ SG_ 437 ID_CIPV "Valid Object = 1 to 255 - ID detected by front camera can vary depending on vehicle environment. - Additional logic would be required to apply this signal for ISG.";
CM_ SG_ 437 Relative_Velocity "+ : Preceding, - : Oncoming - Velocity detected by front camera can vary depending on vehicle environment. - Additional logic would be required to apply this signal for ISG. - Confirmaiton by Autonomous Driving Engineering Team is required to use ID_C";
CM_ SG_ 480 NEW_SIGNAL_5 "todo: figure out why always set to 1";
CM_ BO_ 506 "Sent by the camera containing speed limit information. ISLW stands for Intelligent Speed Limit Warning, and ISLA is Intelligent Speed Limit Assist. it also contains road sign information.";
CM_ SG_ 506 FR_CMR_Crc2Val "The data area for CRC calculation is based on the data length (DLC) of the message DB.The CRC shall be calculated over the entire data block (excluding the CRC bytes) including the user data, alive counter and Data ID - CRC Polynomial (0x1021) , In";
CM_ SG_ 506 FR_CMR_AlvCnt2Val "For the first transmission request for a data element the counter shall be initialized with 0 and shall be incremented by 1 for every subsequent send request. When the counter reaches the maximum value(0xFF), then it shall restart with 0 for the next s";
CM_ SG_ 506 ISLW_OptUsmSta "ISLW option information";
CM_ SG_ 506 ISLW_SysSta "Validity of ISLW information";
CM_ SG_ 506 ISLW_NoPassingInfoDis "This signal indicates additional information of ISLW. For example no passing.";
CM_ SG_ 506 ISLW_OvrlpSignDis "indicates presence of Overlap sign";
CM_ SG_ 506 ISLW_SpdCluMainDis "Main Speed Information for cluster display in main page(0x1~0xFCH: 1*(HEX VALUE) [KPH or MPH :Reference signal is  CF_Clu_SPEED_UNIT of CLU])";
CM_ SG_ 506 ISLW_SpdNaviMainDis "Main Speed information for navigation display in main page(0x1~0xFCH: 1*(HEX VALUE) [KPH or MPH :Reference signal is  Navi_ISLW_SpdUnit of Navigation)";
CM_ SG_ 506 ISLW_SubCondinfoSta1 "Indicates 1st conditional traffic sign status";
CM_ SG_ 506 ISLW_SubCondinfoSta2 "Indicates 2nd conditional traffic sign status";
CM_ SG_ 506 ISLW_SpdCluSubMainDis "Main Speed Information for cluster display in ISLW detail page";
CM_ SG_ 506 ISLW_SpdCluDisSubCond1 "Indicates conditional speed limit/no passing of 1st conditional traffic sign for Cluster in ISLW Detail page";
CM_ SG_ 506 ISLW_SpdCluDisSubCond2 "Indicates conditional speed limit/no passing of 2nd conditional traffic sign for Cluster in ISLW Detail page";
CM_ SG_ 506 ISLW_SpdNaviSubMainDis "Main Speed Information for NAVI display in ISLW detail page";
CM_ SG_ 506 ISLW_SpdNaviDisSubCond1 "Indicates conditional speed limit/no passing of 1st conditional traffic sign for NAVI in ISLW Detail page";
CM_ SG_ 506 ISLW_SpdNaviDisSubCond2 "Indicates conditional speed limit/no passing of 2nd conditional traffic sign for NAVI in ISLW Detail page";
CM_ SG_ 506 ISLA_SpdwOffst "This is a ISLA speed with offset to change the set speed of MSLA/CC/SCC.Unit (kph or mph) refers to cluster signal: CLU_SpdUnitTyp@CLU_01_20ms";
CM_ SG_ 506 ISLA_SwIgnoreReq "This is a signal requesting to ignore the -(SET) or +(SET) switch input of the driver.";
CM_ SG_ 506 ISLA_SpdChgReq "This is a signal requesting to change the set speed of MSLA/CC/SCC to the ISLA speed.";
CM_ SG_ 506 ISLA_SpdWrn "This is a warning signal when VANZ exceeds the speed limit.";
CM_ SG_ 506 ISLA_IcyWrn "This is a warning signal when the snow or ice sign is recognized when it is less than 4 'C.";
CM_ SG_ 506 ISLA_SymFlashMod "This is a signal for the flashing mode of the symbol.";
CM_ SG_ 506 ISLA_Popup "This is a signal for ISLA pop-up.";
CM_ SG_ 506 ISLA_OptUsmSta "This is a ISLA option USM signal set by the driver.";
CM_ SG_ 506 ISLA_OffstUsmSta "This is a signal for offset speed set by the driver. Unit (kph or mph) refers to cluster signal: CLU_SpdUnitTyp@CLU_01_20ms";
CM_ SG_ 506 ISLA_AutoUsmSta "This is a signal for ISLA AUTO USM set by the driver.";
CM_ SG_ 506 ISLA_Cntry "This is a signal for categorizing countries";
CM_ SG_ 506 ISLA_AddtnlSign "This is a signal for additional sign";
CM_ SG_ 506 ISLA_SchoolZone "This is a signal for School Zone";
CM_ SG_ 687 HOD_Dir_Status "This signal indicates the status of hands on/off";
CM_ BO_ 698 "Sent by the camera containing information about vehicles in front of us. IFS stands for Intelligent Front-lighting System, and this signal provides the information necessary for it to operate.";
CM_ SG_ 698 FR_CMR_Crc4Val "The data area for CRC calculation is based on the data length (DLC) of the message DB. The CRC shall be calculated over the entire data block (excluding the CRC bytes) including the user data, alive counter and Data ID - CRC Polynomial (0x1021) , In";
CM_ SG_ 698 FR_CMR_AlvCnt4Val "For the first transmission request for a data element the counter shall be initialized with 0 and shall be incremented by 1 for every subsequent send request. When the counter reaches the maximum value(0xFF), then it shall restart with 0 for the next s";
CM_ SG_ 698 IFSref_FR_CMR_Sta "This is IFS system status needed for operate the IFS function of headlamp highbeam";
CM_ SG_ 698 IFSref_VehNumVal "This is number of vehicles detected from camera";
CM_ SG_ 698 IFSref_ILLAmbtSta "This signal is status of the ambient brightness 0x0 is bright condition (HighBeam off), 0x1 is dark condition (None)";
CM_ SG_ 698 IFSref_VehLftAngl1Val "This is left angle of vehicle 1 Deg = (HEX)*0.1-25";
CM_ SG_ 698 IFSref_VehRtAngl1Val "This is right angle of vehicle 1 Deg = (HEX)*0.1-25";
CM_ SG_ 698 IFSref_VehLftAngl2Val "This is left angle of vehicle 2 Deg = (HEX)*0.1-25";
CM_ SG_ 698 IFSref_VehDst1Val "IFSref_VehicleDistance1Value";
CM_ SG_ 698 IFSref_VehRtAngl2Val "This is right angle of vehicle 2 Deg = (HEX)*0.1-25";
CM_ SG_ 698 IFSref_VehLftAngl3Val "This is left angle of vehicle 3 Deg = (HEX)*0.1-25";
CM_ SG_ 698 IFSref_VehRtAngl3Val "This is right angle of vehicle 3 Deg = (HEX)*0.1-25";
CM_ SG_ 698 IFSref_VehLftAngl4Val "This is left angle of vehicle 4 Deg = (HEX)*0.1-25";
CM_ SG_ 698 IFSref_VehRtAngl4Val "This is right angle of vehicle 4 Deg = (HEX)*0.1-25";
CM_ SG_ 698 IFSref_VehLftAngl5Val "This is left angle of vehicle 5 Deg = (HEX)*0.1-25";
CM_ SG_ 698 IFSref_VehRtAngl5Val "This is right angle of vehicle 5 Deg = (HEX)*0.1-25";
CM_ SG_ 698 IFSref_VehLftAngl6Val "This is left angle of vehicle 6 Deg = (HEX)*0.1-25";
CM_ SG_ 698 IFSref_VehRtAngl6Val "This is right angle of vehicle 6 Deg = (HEX)*0.1-25";
CM_ SG_ 698 IFSref_VehLftAngl7Val "This is left angle of vehicle 7 Deg = (HEX)*0.1-25";
CM_ SG_ 698 IFSref_VehRtAngl7Val "This is right angle of vehicle 7 Deg = (HEX)*0.1-25";
CM_ SG_ 698 IFSref_VehLftAngl8Val "This is left angle of vehicle 8 Deg = (HEX)*0.1-25";
CM_ SG_ 698 IFSref_VehRtAngl8Val "This is right angle of vehicle 8 Deg = (HEX)*0.1-25";
CM_ SG_ 698 IFSref_VehLftAngl9Val "This is left angle of vehicle 9 Deg = (HEX)*0.1-25";
CM_ SG_ 698 IFSref_VehRtAngl9Val "This is right angle of vehicle 9 Deg = (HEX)*0.1-25";
CM_ SG_ 698 IFSref_VehLftAngl10Val "This is left angle of vehicle 10 Deg = (HEX)*0.1-25";
CM_ SG_ 698 IFSref_VehRtAngl10Val "This is right angle of vehicle 10 Deg = (HEX)*0.1-25";
CM_ SG_ 698 IFSref_VehDst2Val "IFSref_VehicleDistance2Value";
CM_ SG_ 698 IFSref_VehDst3Val "IFSref_VehicleDistance3Value";
CM_ SG_ 698 IFSref_VehDst4Val "IFSref_VehicleDistance4Value";
CM_ SG_ 698 IFSref_VehDst5Val "IFSref_VehicleDistance5Value";
CM_ SG_ 698 IFSref_VehDst6Val "IFSref_VehicleDistance6Value";
CM_ SG_ 698 IFSref_VehDst7Val "IFSref_VehicleDistance7Value";
CM_ SG_ 698 IFSref_VehDst8Val "IFSref_VehicleDistance8Value";
CM_ SG_ 698 IFSref_VehDst9Val "IFSref_VehicleDistance9Value";
CM_ SG_ 698 IFSref_VehDst10Val "IFSref_VehicleDistance10Value";
CM_ SG_ 736 MAX_SPEED "Display units. Restricts car from driving above this speed unless accelerator pedal is depressed beyond pressure point";
CM_ BO_ 866 "Contains signals with detailed lane line information. Used by ADAS ECU on HDA 2 vehicles to operate LFA. Used on cars that use message 272.";
CM_ SG_ 866 LEFT_LANE_LINE "Left lane line confidence";
CM_ SG_ 866 RIGHT_LANE_LINE "Right lane line confidence";
CM_ SG_ 961 COUNTER_ALT "only increments on change";

CM_ BO_ 1043 "Lamp signals do not seem universal on cars that use LKAS_ALT, but stalk signals do.";
CM_ SG_ 1043 COUNTER_ALT "only increments on change";
CM_ SG_ 1043 USE_ALT_LAMP "likely 1 on cars that use alt lamp signals";
VAL_ 53 GEAR 0 "P" 5 "D" 6 "N" 7 "R";
VAL_ 64 GEAR 0 "P" 5 "D" 6 "N" 7 "R";
VAL_ 69 GEAR 0 "P" 5 "D" 6 "N" 7 "R";
VAL_ 96 TRACTION_AND_STABILITY_CONTROL 0 "On" 5 "Limited" 1 "Off";
VAL_ 234 LKA_FAULT 0 "ok" 1 "lka fault";
VAL_ 272 LKA_MODE 1 "warning only" 2 "assist" 6 "off";
VAL_ 272 LKA_ICON 0 "hidden" 1 "grey" 2 "green" 3 "flashing green";
VAL_ 272 LKAS_ANGLE_ACTIVE 0 "off" 1 "not active" 2 "active";
VAL_ 373 ACCEnable 0 "SCC ready" 1 "SCC temp fault" 2 "SCC permanent fault" 3 "SCC permanent fault, communication issue";
VAL_ 304 GEAR 1 "P" 2 "R" 3 "N" 4 "D";
VAL_ 976 DRIVER_SEATBELT 0 "Unlatched" 1 "Latched";
VAL_ 976 PASSENGER_SEATBELT 0 "Unlatched" 1 "Latched";
VAL_ 979 DOOR_OPEN_ANY 0 "Opened" 1 "Closed";
VAL_ 1041 DRIVER_DOOR 0 "Closed" 1 "Opened";
VAL_ 1041 PASSENGER_DOOR 0 "Closed" 1 "Opened";
VAL_ 1041 PASSENGER_SEATBELT 0 "Unlatched" 1 "Latched";
VAL_ 1041 DRIVER_SEATBELT 0 "Unlatched" 1 "Latched";
VAL_ 1041 DRIVER_REAR_DOOR 0 "Closed" 1 "Opened";
VAL_ 1041 PASSENGER_REAR_DOOR 0 "Closed" 1 "Opened";

BO_ 426 CRUISE_BUTTONS_ALT: 16 XXX
 SG_ CHECKSUM_T : 0|16@1+ (1,0) [0|65535] "" XXX
 SG_ COUNTER_T : 16|8@1+ (1,0) [0|255] "" XXX
 SG_ NEW_SIGNAL_1 : 24|4@1+ (1,0) [0|15] "" XXX
 SG_ SET_ME_1 : 28|2@1+ (1,0) [0|3] "" XXX
 SG_ DISTANCE_UNIT : 30|1@1+ (1,0) [0|1] "" XXX
 SG_ NEW_SIGNAL_2 : 31|3@1+ (1,0) [0|7] "" XXX
 SG_ ADAPTIVE_CRUISE_MAIN_BTN : 34|1@1+ (1,0) [0|1] "" XXX
 SG_ NEW_SIGNAL_3 : 35|1@1+ (1,0) [0|1] "" XXX
 SG_ CRUISE_BUTTONS : 36|3@1+ (1,0) [0|4] "" XXX
 SG_ LDA_BTN : 39|1@1+ (1,0) [0|1] "" XXX
 SG_ NEW_SIGNAL_4 : 40|1@1+ (1,0) [0|1] "" XXX
 SG_ NORMAL_CRUISE_MAIN_BTN : 41|1@1+ (1,0) [0|1] "" XXX
 SG_ NEW_SIGNAL_5 : 42|2@1+ (1,0) [0|3] "" XXX
 SG_ SET_ME_2 : 44|3@1+ (1,0) [0|7] "" XXX
 SG_ NEW_SIGNAL_6 : 47|1@1+ (1,0) [0|1] "" XXX
 SG_ BYTE6 : 48|8@1+ (1,0) [0|255] "" XXX
 SG_ BYTE7 : 56|8@1+ (1,0) [0|255] "" XXX
 SG_ BYTE8 : 64|8@1+ (1,0) [0|255] "" XXX
 SG_ BYTE9 : 72|8@1+ (1,0) [0|255] "" XXX
 SG_ BYTE10 : 80|8@1+ (1,0) [0|255] "" XXX
 SG_ BYTE11 : 88|8@1+ (1,0) [0|255] "" XXX
 SG_ BYTE12 : 96|8@1+ (1,0) [0|255] "" XXX
 SG_ BYTE13 : 104|8@1+ (1,0) [0|255] "" XXX
 SG_ BYTE14 : 112|8@1+ (1,0) [0|255] "" XXX
 SG_ BYTE15 : 120|8@1+ (1,0) [0|255] "" XXX

BO_ 1043 BLINKERS: 8 XXX
 SG_ LEFT_LAMP : 20|1@0+ (1,0) [0|1] "" XXX
 SG_ RIGHT_LAMP : 22|1@0+ (1,0) [0|1] "" XXX
 SG_ LEFT_LAMP_ALT : 59|1@0+ (1,0) [0|1] "" XXX
 SG_ RIGHT_LAMP_ALT : 61|1@0+ (1,0) [0|1] "" XXX

BO_ 442 BLINDSPOTS_REAR_CORNERS: 24 XXX
 SG_ FL_INDICATOR : 46|6@0+ (1,0) [0|1] "" XXX
 SG_ FR_INDICATOR : 54|6@0+ (1,0) [0|63] "" XXX

BO_ 416 SCC_CONTROL: 32 XXX
 SG_ ACCMode : 68|3@1+ (1,0) [0|7] "" XXX
 SG_ CRUISE_STANDSTILL : 76|1@1+ (1,0) [0|1] "" XXX
 SG_ VSetDis : 103|8@0+ (1,0) [0|255] "" XXX
 SG_ aReqValue : 128|11@1+ (0.01,-10.23) [-10.23|10.24] "m/s^2" XXX
 SG_ aReqRaw : 140|11@1+ (0.01,-10.23) [-10.23|10.24] "m/s^2" XXX
 SG_ CHECKSUM : 0|16@1+ (1,0) [0|65535] "" XXX
 SG_ COUNTER : 16|8@1+ (1,0) [0|255] "" XXX
 SG_ BYTE3 : 24|8@1+ (1,0) [0|255] "" XXX
 SG_ BYTE4 : 32|8@1+ (1,0) [0|255] "" XXX
 SG_ BYTE5 : 40|8@1+ (1,0) [0|255] "" XXX
 SG_ BYTE6 : 48|8@1+ (1,0) [0|255] "" XXX
 SG_ BYTE7 : 56|8@1+ (1,0) [0|255] "" XXX
 SG_ BYTE10 : 80|8@1+ (1,0) [0|255] "" XXX
 SG_ BYTE11 : 88|8@1+ (1,0) [0|255] "" XXX
 SG_ BYTE13 : 104|8@1+ (1,0) [0|255] "" XXX
 SG_ BYTE14 : 112|8@1+ (1,0) [0|255] "" XXX
 SG_ BYTE15 : 120|8@1+ (1,0) [0|255] "" XXX
 SG_ BYTE21 : 168|8@1+ (1,0) [0|255] "" XXX
 SG_ BYTE22 : 176|8@1+ (1,0) [0|255] "" XXX
 SG_ BYTE23 : 184|8@1+ (1,0) [0|255] "" XXX
 SG_ BYTE24 : 192|8@1+ (1,0) [0|255] "" XXX
 SG_ BYTE25 : 200|8@1+ (1,0) [0|255] "" XXX
 SG_ BYTE26 : 208|8@1+ (1,0) [0|255] "" XXX
 SG_ BYTE27 : 216|8@1+ (1,0) [0|255] "" XXX
 SG_ BYTE28 : 224|8@1+ (1,0) [0|255] "" XXX
 SG_ BYTE29 : 232|8@1+ (1,0) [0|255] "" XXX
 SG_ BYTE30 : 240|8@1+ (1,0) [0|255] "" XXX
 SG_ BYTE31 : 248|8@1+ (1,0) [0|255] "" XXX

BO_ 736 MANUAL_SPEED_LIMIT_ASSIST: 32 XXX
 SG_ CHECKSUM_T : 0|16@1+ (1,0) [0|65535] "" XXX
 SG_ COUNTER_T : 16|8@1+ (1,0) [0|255] "" XXX
 SG_ MSLA_STATUS : 26|2@1+ (1,0) [0|3] "" XXX
 SG_ MSLA_ENABLED : 38|1@1+ (1,0) [0|1] "" XXX
 SG_ MAX_SPEED : 55|8@0+ (1,0) [0|255] "" XXX
 SG_ MAX_SPEED_COPY : 144|8@1+ (1,0) [0|255] "" XXX

BO_ 506 ISLA: 32 XXX
 SG_ BYTE0 : 0|8@1+ (1,0) [0|255] "" XXX
 SG_ BYTE1 : 8|8@1+ (1,0) [0|255] "" XXX
 SG_ BYTE2 : 16|8@1+ (1,0) [0|255] "" XXX
 SG_ BYTE3 : 24|8@1+ (1,0) [0|255] "" XXX
 SG_ BYTE4 : 32|8@1+ (1,0) [0|255] "" XXX
 SG_ BYTE5 : 40|8@1+ (1,0) [0|255] "" XXX
 SG_ BYTE6 : 48|8@1+ (1,0) [0|255] "" XXX
 SG_ BYTE7 : 56|8@1+ (1,0) [0|255] "" XXX
 SG_ BYTE8 : 64|8@1+ (1,0) [0|255] "" XXX
 SG_ BYTE9 : 72|8@1+ (1,0) [0|255] "" XXX
 SG_ BYTE10 : 80|8@1+ (1,0) [0|255] "" XXX
 SG_ BYTE11 : 88|8@1+ (1,0) [0|255] "" XXX
 SG_ BYTE12 : 96|8@1+ (1,0) [0|255] "" XXX
 SG_ BYTE13 : 104|8@1+ (1,0) [0|255] "" XXX
 SG_ BYTE14 : 112|8@1+ (1,0) [0|255] "" XXX
 SG_ BYTE15 : 120|8@1+ (1,0) [0|255] "" XXX
 SG_ BYTE16 : 128|8@1+ (1,0) [0|255] "" XXX
 SG_ BYTE17 : 136|8@1+ (1,0) [0|255] "" XXX
 SG_ BYTE18 : 144|8@1+ (1,0) [0|255] "" XXX
 SG_ BYTE19 : 152|8@1+ (1,0) [0|255] "" XXX
 SG_ BYTE20 : 160|8@1+ (1,0) [0|255] "" XXX
 SG_ BYTE21 : 168|8@1+ (1,0) [0|255] "" XXX
 SG_ BYTE22 : 176|8@1+ (1,0) [0|255] "" XXX
 SG_ BYTE23 : 184|8@1+ (1,0) [0|255] "" XXX
 SG_ BYTE24 : 192|8@1+ (1,0) [0|255] "" XXX
 SG_ BYTE25 : 200|8@1+ (1,0) [0|255] "" XXX
 SG_ BYTE26 : 208|8@1+ (1,0) [0|255] "" XXX
 SG_ BYTE27 : 216|8@1+ (1,0) [0|255] "" XXX
 SG_ BYTE28 : 224|8@1+ (1,0) [0|255] "" XXX
 SG_ BYTE29 : 232|8@1+ (1,0) [0|255] "" XXX
 SG_ BYTE30 : 240|8@1+ (1,0) [0|255] "" XXX
 SG_ BYTE31 : 248|8@1+ (1,0) [0|255] "" XXX

BO_ 676 CAM_0x2a4: 24 XXX
 SG_ COUNTER_T : 0|8@1+ (1,0) [0|255] "" XXX
 SG_ CHECKSUM_T : 8|16@1+ (1,0) [0|65535] "" XXX
 SG_ BYTE3 : 24|8@1+ (1,0) [0|255] "" XXX
 SG_ BYTE4 : 32|8@1+ (1,0) [0|255] "" XXX
 SG_ BYTE5 : 40|8@1+ (1,0) [0|255] "" XXX
 SG_ BYTE6 : 48|8@1+ (1,0) [0|255] "" XXX
 SG_ BYTE7 : 56|8@1+ (1,0) [0|255] "" XXX
 SG_ BYTE8 : 64|8@1+ (1,0) [0|255] "" XXX
 SG_ BYTE9 : 72|8@1+ (1,0) [0|255] "" XXX
 SG_ BYTE10 : 80|8@1+ (1,0) [0|255] "" XXX
 SG_ BYTE11 : 88|8@1+ (1,0) [0|255] "" XXX
 SG_ BYTE12 : 96|8@1+ (1,0) [0|255] "" XXX
 SG_ BYTE13 : 104|8@1+ (1,0) [0|255] "" XXX
 SG_ BYTE14 : 112|8@1+ (1,0) [0|255] "" XXX
 SG_ BYTE15 : 120|8@1+ (1,0) [0|255] "" XXX
 SG_ BYTE16 : 128|8@1+ (1,0) [0|255] "" XXX
 SG_ BYTE17 : 136|8@1+ (1,0) [0|255] "" XXX
 SG_ BYTE18 : 144|8@1+ (1,0) [0|255] "" XXX
 SG_ BYTE19 : 152|8@1+ (1,0) [0|255] "" XXX
 SG_ BYTE20 : 160|8@1+ (1,0) [0|255] "" XXX
 SG_ BYTE21 : 168|8@1+ (1,0) [0|255] "" XXX
 SG_ BYTE22 : 176|8@1+ (1,0) [0|255] "" XXX
 SG_ BYTE23 : 184|8@1+ (1,0) [0|255] "" XXX

BO_ 933 RADAR_TRACK_933: 24 XXX
 SG_ BYTE0 : 0|8@1+ (1,0) [0|255] "" XXX
 SG_ BYTE1 : 8|8@1+ (1,0) [0|255] "" XXX
 SG_ BYTE2 : 16|8@1+ (1,0) [0|255] "" XXX
 SG_ BYTE3 : 24|8@1+ (1,0) [0|255] "" XXX
 SG_ BYTE4 : 32|8@1+ (1,0) [0|255] "" XXX
 SG_ BYTE5 : 40|8@1+ (1,0) [0|255] "" XXX
 SG_ BYTE6 : 48|8@1+ (1,0) [0|255] "" XXX
 SG_ BYTE7 : 56|8@1+ (1,0) [0|255] "" XXX
 SG_ BYTE8 : 64|8@1+ (1,0) [0|255] "" XXX
 SG_ BYTE9 : 72|8@1+ (1,0) [0|255] "" XXX
 SG_ BYTE10 : 80|8@1+ (1,0) [0|255] "" XXX
 SG_ BYTE11 : 88|8@1+ (1,0) [0|255] "" XXX
 SG_ BYTE12 : 96|8@1+ (1,0) [0|255] "" XXX
 SG_ BYTE13 : 104|8@1+ (1,0) [0|255] "" XXX
 SG_ BYTE14 : 112|8@1+ (1,0) [0|255] "" XXX
 SG_ BYTE15 : 120|8@1+ (1,0) [0|255] "" XXX
 SG_ BYTE16 : 128|8@1+ (1,0) [0|255] "" XXX
 SG_ BYTE17 : 136|8@1+ (1,0) [0|255] "" XXX
 SG_ BYTE18 : 144|8@1+ (1,0) [0|255] "" XXX
 SG_ BYTE19 : 152|8@1+ (1,0) [0|255] "" XXX
 SG_ BYTE20 : 160|8@1+ (1,0) [0|255] "" XXX
 SG_ BYTE21 : 168|8@1+ (1,0) [0|255] "" XXX
 SG_ BYTE22 : 176|8@1+ (1,0) [0|255] "" XXX
 SG_ BYTE23 : 184|8@1+ (1,0) [0|255] "" XXX

BO_ 934 RADAR_TRACK_934: 24 XXX
 SG_ BYTE0 : 0|8@1+ (1,0) [0|255] "" XXX
 SG_ BYTE1 : 8|8@1+ (1,0) [0|255] "" XXX
 SG_ BYTE2 : 16|8@1+ (1,0) [0|255] "" XXX
 SG_ BYTE3 : 24|8@1+ (1,0) [0|255] "" XXX
 SG_ BYTE4 : 32|8@1+ (1,0) [0|255] "" XXX
 SG_ BYTE5 : 40|8@1+ (1,0) [0|255] "" XXX
 SG_ BYTE6 : 48|8@1+ (1,0) [0|255] "" XXX
 SG_ BYTE7 : 56|8@1+ (1,0) [0|255] "" XXX
 SG_ BYTE8 : 64|8@1+ (1,0) [0|255] "" XXX
 SG_ BYTE9 : 72|8@1+ (1,0) [0|255] "" XXX
 SG_ BYTE10 : 80|8@1+ (1,0) [0|255] "" XXX
 SG_ BYTE11 : 88|8@1+ (1,0) [0|255] "" XXX
 SG_ BYTE12 : 96|8@1+ (1,0) [0|255] "" XXX
 SG_ BYTE13 : 104|8@1+ (1,0) [0|255] "" XXX
 SG_ BYTE14 : 112|8@1+ (1,0) [0|255] "" XXX
 SG_ BYTE15 : 120|8@1+ (1,0) [0|255] "" XXX
 SG_ BYTE16 : 128|8@1+ (1,0) [0|255] "" XXX
 SG_ BYTE17 : 136|8@1+ (1,0) [0|255] "" XXX
 SG_ BYTE18 : 144|8@1+ (1,0) [0|255] "" XXX
 SG_ BYTE19 : 152|8@1+ (1,0) [0|255] "" XXX
 SG_ BYTE20 : 160|8@1+ (1,0) [0|255] "" XXX
 SG_ BYTE21 : 168|8@1+ (1,0) [0|255] "" XXX
 SG_ BYTE22 : 176|8@1+ (1,0) [0|255] "" XXX
 SG_ BYTE23 : 184|8@1+ (1,0) [0|255] "" XXX

BO_ 935 RADAR_TRACK_935: 24 XXX
 SG_ BYTE0 : 0|8@1+ (1,0) [0|255] "" XXX
 SG_ BYTE1 : 8|8@1+ (1,0) [0|255] "" XXX
 SG_ BYTE2 : 16|8@1+ (1,0) [0|255] "" XXX
 SG_ BYTE3 : 24|8@1+ (1,0) [0|255] "" XXX
 SG_ BYTE4 : 32|8@1+ (1,0) [0|255] "" XXX
 SG_ BYTE5 : 40|8@1+ (1,0) [0|255] "" XXX
 SG_ BYTE6 : 48|8@1+ (1,0) [0|255] "" XXX
 SG_ BYTE7 : 56|8@1+ (1,0) [0|255] "" XXX
 SG_ BYTE8 : 64|8@1+ (1,0) [0|255] "" XXX
 SG_ BYTE9 : 72|8@1+ (1,0) [0|255] "" XXX
 SG_ BYTE10 : 80|8@1+ (1,0) [0|255] "" XXX
 SG_ BYTE11 : 88|8@1+ (1,0) [0|255] "" XXX
 SG_ BYTE12 : 96|8@1+ (1,0) [0|255] "" XXX
 SG_ BYTE13 : 104|8@1+ (1,0) [0|255] "" XXX
 SG_ BYTE14 : 112|8@1+ (1,0) [0|255] "" XXX
 SG_ BYTE15 : 120|8@1+ (1,0) [0|255] "" XXX
 SG_ BYTE16 : 128|8@1+ (1,0) [0|255] "" XXX
 SG_ BYTE17 : 136|8@1+ (1,0) [0|255] "" XXX
 SG_ BYTE18 : 144|8@1+ (1,0) [0|255] "" XXX
 SG_ BYTE19 : 152|8@1+ (1,0) [0|255] "" XXX
 SG_ BYTE20 : 160|8@1+ (1,0) [0|255] "" XXX
 SG_ BYTE21 : 168|8@1+ (1,0) [0|255] "" XXX
 SG_ BYTE22 : 176|8@1+ (1,0) [0|255] "" XXX
 SG_ BYTE23 : 184|8@1+ (1,0) [0|255] "" XXX

BO_ 936 RADAR_TRACK_936: 24 XXX
 SG_ BYTE0 : 0|8@1+ (1,0) [0|255] "" XXX
 SG_ BYTE1 : 8|8@1+ (1,0) [0|255] "" XXX
 SG_ BYTE2 : 16|8@1+ (1,0) [0|255] "" XXX
 SG_ BYTE3 : 24|8@1+ (1,0) [0|255] "" XXX
 SG_ BYTE4 : 32|8@1+ (1,0) [0|255] "" XXX
 SG_ BYTE5 : 40|8@1+ (1,0) [0|255] "" XXX
 SG_ BYTE6 : 48|8@1+ (1,0) [0|255] "" XXX
 SG_ BYTE7 : 56|8@1+ (1,0) [0|255] "" XXX
 SG_ BYTE8 : 64|8@1+ (1,0) [0|255] "" XXX
 SG_ BYTE9 : 72|8@1+ (1,0) [0|255] "" XXX
 SG_ BYTE10 : 80|8@1+ (1,0) [0|255] "" XXX
 SG_ BYTE11 : 88|8@1+ (1,0) [0|255] "" XXX
 SG_ BYTE12 : 96|8@1+ (1,0) [0|255] "" XXX
 SG_ BYTE13 : 104|8@1+ (1,0) [0|255] "" XXX
 SG_ BYTE14 : 112|8@1+ (1,0) [0|255] "" XXX
 SG_ BYTE15 : 120|8@1+ (1,0) [0|255] "" XXX
 SG_ BYTE16 : 128|8@1+ (1,0) [0|255] "" XXX
 SG_ BYTE17 : 136|8@1+ (1,0) [0|255] "" XXX
 SG_ BYTE18 : 144|8@1+ (1,0) [0|255] "" XXX
 SG_ BYTE19 : 152|8@1+ (1,0) [0|255] "" XXX
 SG_ BYTE20 : 160|8@1+ (1,0) [0|255] "" XXX
 SG_ BYTE21 : 168|8@1+ (1,0) [0|255] "" XXX
 SG_ BYTE22 : 176|8@1+ (1,0) [0|255] "" XXX
 SG_ BYTE23 : 184|8@1+ (1,0) [0|255] "" XXX

BO_ 937 RADAR_TRACK_937: 24 XXX
 SG_ BYTE0 : 0|8@1+ (1,0) [0|255] "" XXX
 SG_ BYTE1 : 8|8@1+ (1,0) [0|255] "" XXX
 SG_ BYTE2 : 16|8@1+ (1,0) [0|255] "" XXX
 SG_ BYTE3 : 24|8@1+ (1,0) [0|255] "" XXX
 SG_ BYTE4 : 32|8@1+ (1,0) [0|255] "" XXX
 SG_ BYTE5 : 40|8@1+ (1,0) [0|255] "" XXX
 SG_ BYTE6 : 48|8@1+ (1,0) [0|255] "" XXX
 SG_ BYTE7 : 56|8@1+ (1,0) [0|255] "" XXX
 SG_ BYTE8 : 64|8@1+ (1,0) [0|255] "" XXX
 SG_ BYTE9 : 72|8@1+ (1,0) [0|255] "" XXX
 SG_ BYTE10 : 80|8@1+ (1,0) [0|255] "" XXX
 SG_ BYTE11 : 88|8@1+ (1,0) [0|255] "" XXX
 SG_ BYTE12 : 96|8@1+ (1,0) [0|255] "" XXX
 SG_ BYTE13 : 104|8@1+ (1,0) [0|255] "" XXX
 SG_ BYTE14 : 112|8@1+ (1,0) [0|255] "" XXX
 SG_ BYTE15 : 120|8@1+ (1,0) [0|255] "" XXX
 SG_ BYTE16 : 128|8@1+ (1,0) [0|255] "" XXX
 SG_ BYTE17 : 136|8@1+ (1,0) [0|255] "" XXX
 SG_ BYTE18 : 144|8@1+ (1,0) [0|255] "" XXX
 SG_ BYTE19 : 152|8@1+ (1,0) [0|255] "" XXX
 SG_ BYTE20 : 160|8@1+ (1,0) [0|255] "" XXX
 SG_ BYTE21 : 168|8@1+ (1,0) [0|255] "" XXX
 SG_ BYTE22 : 176|8@1+ (1,0) [0|255] "" XXX
 SG_ BYTE23 : 184|8@1+ (1,0) [0|255] "" XXX

BO_ 938 RADAR_TRACK_938: 24 XXX
 SG_ BYTE0 : 0|8@1+ (1,0) [0|255] "" XXX
 SG_ BYTE1 : 8|8@1+ (1,0) [0|255] "" XXX
 SG_ BYTE2 : 16|8@1+ (1,0) [0|255] "" XXX
 SG_ BYTE3 : 24|8@1+ (1,0) [0|255] "" XXX
 SG_ BYTE4 : 32|8@1+ (1,0) [0|255] "" XXX
 SG_ BYTE5 : 40|8@1+ (1,0) [0|255] "" XXX
 SG_ BYTE6 : 48|8@1+ (1,0) [0|255] "" XXX
 SG_ BYTE7 : 56|8@1+ (1,0) [0|255] "" XXX
 SG_ BYTE8 : 64|8@1+ (1,0) [0|255] "" XXX
 SG_ BYTE9 : 72|8@1+ (1,0) [0|255] "" XXX
 SG_ BYTE10 : 80|8@1+ (1,0) [0|255] "" XXX
 SG_ BYTE11 : 88|8@1+ (1,0) [0|255] "" XXX
 SG_ BYTE12 : 96|8@1+ (1,0) [0|255] "" XXX
 SG_ BYTE13 : 104|8@1+ (1,0) [0|255] "" XXX
 SG_ BYTE14 : 112|8@1+ (1,0) [0|255] "" XXX
 SG_ BYTE15 : 120|8@1+ (1,0) [0|255] "" XXX
 SG_ BYTE16 : 128|8@1+ (1,0) [0|255] "" XXX
 SG_ BYTE17 : 136|8@1+ (1,0) [0|255] "" XXX
 SG_ BYTE18 : 144|8@1+ (1,0) [0|255] "" XXX
 SG_ BYTE19 : 152|8@1+ (1,0) [0|255] "" XXX
 SG_ BYTE20 : 160|8@1+ (1,0) [0|255] "" XXX
 SG_ BYTE21 : 168|8@1+ (1,0) [0|255] "" XXX
 SG_ BYTE22 : 176|8@1+ (1,0) [0|255] "" XXX
 SG_ BYTE23 : 184|8@1+ (1,0) [0|255] "" XXX

BO_ 940 RADAR_TRACK_940: 24 XXX
 SG_ BYTE0 : 0|8@1+ (1,0) [0|255] "" XXX
 SG_ BYTE1 : 8|8@1+ (1,0) [0|255] "" XXX
 SG_ BYTE2 : 16|8@1+ (1,0) [0|255] "" XXX
 SG_ BYTE3 : 24|8@1+ (1,0) [0|255] "" XXX
 SG_ BYTE4 : 32|8@1+ (1,0) [0|255] "" XXX
 SG_ BYTE5 : 40|8@1+ (1,0) [0|255] "" XXX
 SG_ BYTE6 : 48|8@1+ (1,0) [0|255] "" XXX
 SG_ BYTE7 : 56|8@1+ (1,0) [0|255] "" XXX
 SG_ BYTE8 : 64|8@1+ (1,0) [0|255] "" XXX
 SG_ BYTE9 : 72|8@1+ (1,0) [0|255] "" XXX
 SG_ BYTE10 : 80|8@1+ (1,0) [0|255] "" XXX
 SG_ BYTE11 : 88|8@1+ (1,0) [0|255] "" XXX
 SG_ BYTE12 : 96|8@1+ (1,0) [0|255] "" XXX
 SG_ BYTE13 : 104|8@1+ (1,0) [0|255] "" XXX
 SG_ BYTE14 : 112|8@1+ (1,0) [0|255] "" XXX
 SG_ BYTE15 : 120|8@1+ (1,0) [0|255] "" XXX
 SG_ BYTE16 : 128|8@1+ (1,0) [0|255] "" XXX
 SG_ BYTE17 : 136|8@1+ (1,0) [0|255] "" XXX
 SG_ BYTE18 : 144|8@1+ (1,0) [0|255] "" XXX
 SG_ BYTE19 : 152|8@1+ (1,0) [0|255] "" XXX
 SG_ BYTE20 : 160|8@1+ (1,0) [0|255] "" XXX
 SG_ BYTE21 : 168|8@1+ (1,0) [0|255] "" XXX
 SG_ BYTE22 : 176|8@1+ (1,0) [0|255] "" XXX
 SG_ BYTE23 : 184|8@1+ (1,0) [0|255] "" XXX

BO_ 941 RADAR_TRACK_941: 24 XXX
 SG_ BYTE0 : 0|8@1+ (1,0) [0|255] "" XXX
 SG_ BYTE1 : 8|8@1+ (1,0) [0|255] "" XXX
 SG_ BYTE2 : 16|8@1+ (1,0) [0|255] "" XXX
 SG_ BYTE3 : 24|8@1+ (1,0) [0|255] "" XXX
 SG_ BYTE4 : 32|8@1+ (1,0) [0|255] "" XXX
 SG_ BYTE5 : 40|8@1+ (1,0) [0|255] "" XXX
 SG_ BYTE6 : 48|8@1+ (1,0) [0|255] "" XXX
 SG_ BYTE7 : 56|8@1+ (1,0) [0|255] "" XXX
 SG_ BYTE8 : 64|8@1+ (1,0) [0|255] "" XXX
 SG_ BYTE9 : 72|8@1+ (1,0) [0|255] "" XXX
 SG_ BYTE10 : 80|8@1+ (1,0) [0|255] "" XXX
 SG_ BYTE11 : 88|8@1+ (1,0) [0|255] "" XXX
 SG_ BYTE12 : 96|8@1+ (1,0) [0|255] "" XXX
 SG_ BYTE13 : 104|8@1+ (1,0) [0|255] "" XXX
 SG_ BYTE14 : 112|8@1+ (1,0) [0|255] "" XXX
 SG_ BYTE15 : 120|8@1+ (1,0) [0|255] "" XXX
 SG_ BYTE16 : 128|8@1+ (1,0) [0|255] "" XXX
 SG_ BYTE17 : 136|8@1+ (1,0) [0|255] "" XXX
 SG_ BYTE18 : 144|8@1+ (1,0) [0|255] "" XXX
 SG_ BYTE19 : 152|8@1+ (1,0) [0|255] "" XXX
 SG_ BYTE20 : 160|8@1+ (1,0) [0|255] "" XXX
 SG_ BYTE21 : 168|8@1+ (1,0) [0|255] "" XXX
 SG_ BYTE22 : 176|8@1+ (1,0) [0|255] "" XXX
 SG_ BYTE23 : 184|8@1+ (1,0) [0|255] "" XXX

BO_ 942 RADAR_TRACK_942: 24 XXX
 SG_ BYTE0 : 0|8@1+ (1,0) [0|255] "" XXX
 SG_ BYTE1 : 8|8@1+ (1,0) [0|255] "" XXX
 SG_ BYTE2 : 16|8@1+ (1,0) [0|255] "" XXX
 SG_ BYTE3 : 24|8@1+ (1,0) [0|255] "" XXX
 SG_ BYTE4 : 32|8@1+ (1,0) [0|255] "" XXX
 SG_ BYTE5 : 40|8@1+ (1,0) [0|255] "" XXX
 SG_ BYTE6 : 48|8@1+ (1,0) [0|255] "" XXX
 SG_ BYTE7 : 56|8@1+ (1,0) [0|255] "" XXX
 SG_ BYTE8 : 64|8@1+ (1,0) [0|255] "" XXX
 SG_ BYTE9 : 72|8@1+ (1,0) [0|255] "" XXX
 SG_ BYTE10 : 80|8@1+ (1,0) [0|255] "" XXX
 SG_ BYTE11 : 88|8@1+ (1,0) [0|255] "" XXX
 SG_ BYTE12 : 96|8@1+ (1,0) [0|255] "" XXX
 SG_ BYTE13 : 104|8@1+ (1,0) [0|255] "" XXX
 SG_ BYTE14 : 112|8@1+ (1,0) [0|255] "" XXX
 SG_ BYTE15 : 120|8@1+ (1,0) [0|255] "" XXX
 SG_ BYTE16 : 128|8@1+ (1,0) [0|255] "" XXX
 SG_ BYTE17 : 136|8@1+ (1,0) [0|255] "" XXX
 SG_ BYTE18 : 144|8@1+ (1,0) [0|255] "" XXX
 SG_ BYTE19 : 152|8@1+ (1,0) [0|255] "" XXX
 SG_ BYTE20 : 160|8@1+ (1,0) [0|255] "" XXX
 SG_ BYTE21 : 168|8@1+ (1,0) [0|255] "" XXX
 SG_ BYTE22 : 176|8@1+ (1,0) [0|255] "" XXX
 SG_ BYTE23 : 184|8@1+ (1,0) [0|255] "" XXX

BO_ 943 RADAR_TRACK_943: 24 XXX
 SG_ BYTE0 : 0|8@1+ (1,0) [0|255] "" XXX
 SG_ BYTE1 : 8|8@1+ (1,0) [0|255] "" XXX
 SG_ BYTE2 : 16|8@1+ (1,0) [0|255] "" XXX
 SG_ BYTE3 : 24|8@1+ (1,0) [0|255] "" XXX
 SG_ BYTE4 : 32|8@1+ (1,0) [0|255] "" XXX
 SG_ BYTE5 : 40|8@1+ (1,0) [0|255] "" XXX
 SG_ BYTE6 : 48|8@1+ (1,0) [0|255] "" XXX
 SG_ BYTE7 : 56|8@1+ (1,0) [0|255] "" XXX
 SG_ BYTE8 : 64|8@1+ (1,0) [0|255] "" XXX
 SG_ BYTE9 : 72|8@1+ (1,0) [0|255] "" XXX
 SG_ BYTE10 : 80|8@1+ (1,0) [0|255] "" XXX
 SG_ BYTE11 : 88|8@1+ (1,0) [0|255] "" XXX
 SG_ BYTE12 : 96|8@1+ (1,0) [0|255] "" XXX
 SG_ BYTE13 : 104|8@1+ (1,0) [0|255] "" XXX
 SG_ BYTE14 : 112|8@1+ (1,0) [0|255] "" XXX
 SG_ BYTE15 : 120|8@1+ (1,0) [0|255] "" XXX
 SG_ BYTE16 : 128|8@1+ (1,0) [0|255] "" XXX
 SG_ BYTE17 : 136|8@1+ (1,0) [0|255] "" XXX
 SG_ BYTE18 : 144|8@1+ (1,0) [0|255] "" XXX
 SG_ BYTE19 : 152|8@1+ (1,0) [0|255] "" XXX
 SG_ BYTE20 : 160|8@1+ (1,0) [0|255] "" XXX
 SG_ BYTE21 : 168|8@1+ (1,0) [0|255] "" XXX
 SG_ BYTE22 : 176|8@1+ (1,0) [0|255] "" XXX
 SG_ BYTE23 : 184|8@1+ (1,0) [0|255] "" XXX

BO_ 944 RADAR_TRACK_944: 24 XXX
 SG_ BYTE0 : 0|8@1+ (1,0) [0|255] "" XXX
 SG_ BYTE1 : 8|8@1+ (1,0) [0|255] "" XXX
 SG_ BYTE2 : 16|8@1+ (1,0) [0|255] "" XXX
 SG_ BYTE3 : 24|8@1+ (1,0) [0|255] "" XXX
 SG_ BYTE4 : 32|8@1+ (1,0) [0|255] "" XXX
 SG_ BYTE5 : 40|8@1+ (1,0) [0|255] "" XXX
 SG_ BYTE6 : 48|8@1+ (1,0) [0|255] "" XXX
 SG_ BYTE7 : 56|8@1+ (1,0) [0|255] "" XXX
 SG_ BYTE8 : 64|8@1+ (1,0) [0|255] "" XXX
 SG_ BYTE9 : 72|8@1+ (1,0) [0|255] "" XXX
 SG_ BYTE10 : 80|8@1+ (1,0) [0|255] "" XXX
 SG_ BYTE11 : 88|8@1+ (1,0) [0|255] "" XXX
 SG_ BYTE12 : 96|8@1+ (1,0) [0|255] "" XXX
 SG_ BYTE13 : 104|8@1+ (1,0) [0|255] "" XXX
 SG_ BYTE14 : 112|8@1+ (1,0) [0|255] "" XXX
 SG_ BYTE15 : 120|8@1+ (1,0) [0|255] "" XXX
 SG_ BYTE16 : 128|8@1+ (1,0) [0|255] "" XXX
 SG_ BYTE17 : 136|8@1+ (1,0) [0|255] "" XXX
 SG_ BYTE18 : 144|8@1+ (1,0) [0|255] "" XXX
 SG_ BYTE19 : 152|8@1+ (1,0) [0|255] "" XXX
 SG_ BYTE20 : 160|8@1+ (1,0) [0|255] "" XXX
 SG_ BYTE21 : 168|8@1+ (1,0) [0|255] "" XXX
 SG_ BYTE22 : 176|8@1+ (1,0) [0|255] "" XXX
 SG_ BYTE23 : 184|8@1+ (1,0) [0|255] "" XXX

BO_ 945 RADAR_TRACK_945: 24 XXX
 SG_ BYTE0 : 0|8@1+ (1,0) [0|255] "" XXX
 SG_ BYTE1 : 8|8@1+ (1,0) [0|255] "" XXX
 SG_ BYTE2 : 16|8@1+ (1,0) [0|255] "" XXX
 SG_ BYTE3 : 24|8@1+ (1,0) [0|255] "" XXX
 SG_ BYTE4 : 32|8@1+ (1,0) [0|255] "" XXX
 SG_ BYTE5 : 40|8@1+ (1,0) [0|255] "" XXX
 SG_ BYTE6 : 48|8@1+ (1,0) [0|255] "" XXX
 SG_ BYTE7 : 56|8@1+ (1,0) [0|255] "" XXX
 SG_ BYTE8 : 64|8@1+ (1,0) [0|255] "" XXX
 SG_ BYTE9 : 72|8@1+ (1,0) [0|255] "" XXX
 SG_ BYTE10 : 80|8@1+ (1,0) [0|255] "" XXX
 SG_ BYTE11 : 88|8@1+ (1,0) [0|255] "" XXX
 SG_ BYTE12 : 96|8@1+ (1,0) [0|255] "" XXX
 SG_ BYTE13 : 104|8@1+ (1,0) [0|255] "" XXX
 SG_ BYTE14 : 112|8@1+ (1,0) [0|255] "" XXX
 SG_ BYTE15 : 120|8@1+ (1,0) [0|255] "" XXX
 SG_ BYTE16 : 128|8@1+ (1,0) [0|255] "" XXX
 SG_ BYTE17 : 136|8@1+ (1,0) [0|255] "" XXX
 SG_ BYTE18 : 144|8@1+ (1,0) [0|255] "" XXX
 SG_ BYTE19 : 152|8@1+ (1,0) [0|255] "" XXX
 SG_ BYTE20 : 160|8@1+ (1,0) [0|255] "" XXX
 SG_ BYTE21 : 168|8@1+ (1,0) [0|255] "" XXX
 SG_ BYTE22 : 176|8@1+ (1,0) [0|255] "" XXX
 SG_ BYTE23 : 184|8@1+ (1,0) [0|255] "" XXX

BO_ 946 RADAR_TRACK_946: 24 XXX
 SG_ BYTE0 : 0|8@1+ (1,0) [0|255] "" XXX
 SG_ BYTE1 : 8|8@1+ (1,0) [0|255] "" XXX
 SG_ BYTE2 : 16|8@1+ (1,0) [0|255] "" XXX
 SG_ BYTE3 : 24|8@1+ (1,0) [0|255] "" XXX
 SG_ BYTE4 : 32|8@1+ (1,0) [0|255] "" XXX
 SG_ BYTE5 : 40|8@1+ (1,0) [0|255] "" XXX
 SG_ BYTE6 : 48|8@1+ (1,0) [0|255] "" XXX
 SG_ BYTE7 : 56|8@1+ (1,0) [0|255] "" XXX
 SG_ BYTE8 : 64|8@1+ (1,0) [0|255] "" XXX
 SG_ BYTE9 : 72|8@1+ (1,0) [0|255] "" XXX
 SG_ BYTE10 : 80|8@1+ (1,0) [0|255] "" XXX
 SG_ BYTE11 : 88|8@1+ (1,0) [0|255] "" XXX
 SG_ BYTE12 : 96|8@1+ (1,0) [0|255] "" XXX
 SG_ BYTE13 : 104|8@1+ (1,0) [0|255] "" XXX
 SG_ BYTE14 : 112|8@1+ (1,0) [0|255] "" XXX
 SG_ BYTE15 : 120|8@1+ (1,0) [0|255] "" XXX
 SG_ BYTE16 : 128|8@1+ (1,0) [0|255] "" XXX
 SG_ BYTE17 : 136|8@1+ (1,0) [0|255] "" XXX
 SG_ BYTE18 : 144|8@1+ (1,0) [0|255] "" XXX
 SG_ BYTE19 : 152|8@1+ (1,0) [0|255] "" XXX
 SG_ BYTE20 : 160|8@1+ (1,0) [0|255] "" XXX
 SG_ BYTE21 : 168|8@1+ (1,0) [0|255] "" XXX
 SG_ BYTE22 : 176|8@1+ (1,0) [0|255] "" XXX
 SG_ BYTE23 : 184|8@1+ (1,0) [0|255] "" XXX

BO_ 947 RADAR_TRACK_947: 24 XXX
 SG_ BYTE0 : 0|8@1+ (1,0) [0|255] "" XXX
 SG_ BYTE1 : 8|8@1+ (1,0) [0|255] "" XXX
 SG_ BYTE2 : 16|8@1+ (1,0) [0|255] "" XXX
 SG_ BYTE3 : 24|8@1+ (1,0) [0|255] "" XXX
 SG_ BYTE4 : 32|8@1+ (1,0) [0|255] "" XXX
 SG_ BYTE5 : 40|8@1+ (1,0) [0|255] "" XXX
 SG_ BYTE6 : 48|8@1+ (1,0) [0|255] "" XXX
 SG_ BYTE7 : 56|8@1+ (1,0) [0|255] "" XXX
 SG_ BYTE8 : 64|8@1+ (1,0) [0|255] "" XXX
 SG_ BYTE9 : 72|8@1+ (1,0) [0|255] "" XXX
 SG_ BYTE10 : 80|8@1+ (1,0) [0|255] "" XXX
 SG_ BYTE11 : 88|8@1+ (1,0) [0|255] "" XXX
 SG_ BYTE12 : 96|8@1+ (1,0) [0|255] "" XXX
 SG_ BYTE13 : 104|8@1+ (1,0) [0|255] "" XXX
 SG_ BYTE14 : 112|8@1+ (1,0) [0|255] "" XXX
 SG_ BYTE15 : 120|8@1+ (1,0) [0|255] "" XXX
 SG_ BYTE16 : 128|8@1+ (1,0) [0|255] "" XXX
 SG_ BYTE17 : 136|8@1+ (1,0) [0|255] "" XXX
 SG_ BYTE18 : 144|8@1+ (1,0) [0|255] "" XXX
 SG_ BYTE19 : 152|8@1+ (1,0) [0|255] "" XXX
 SG_ BYTE20 : 160|8@1+ (1,0) [0|255] "" XXX
 SG_ BYTE21 : 168|8@1+ (1,0) [0|255] "" XXX
 SG_ BYTE22 : 176|8@1+ (1,0) [0|255] "" XXX
 SG_ BYTE23 : 184|8@1+ (1,0) [0|255] "" XXX

BO_ 948 RADAR_TRACK_948: 24 XXX
 SG_ BYTE0 : 0|8@1+ (1,0) [0|255] "" XXX
 SG_ BYTE1 : 8|8@1+ (1,0) [0|255] "" XXX
 SG_ BYTE2 : 16|8@1+ (1,0) [0|255] "" XXX
 SG_ BYTE3 : 24|8@1+ (1,0) [0|255] "" XXX
 SG_ BYTE4 : 32|8@1+ (1,0) [0|255] "" XXX
 SG_ BYTE5 : 40|8@1+ (1,0) [0|255] "" XXX
 SG_ BYTE6 : 48|8@1+ (1,0) [0|255] "" XXX
 SG_ BYTE7 : 56|8@1+ (1,0) [0|255] "" XXX
 SG_ BYTE8 : 64|8@1+ (1,0) [0|255] "" XXX
 SG_ BYTE9 : 72|8@1+ (1,0) [0|255] "" XXX
 SG_ BYTE10 : 80|8@1+ (1,0) [0|255] "" XXX
 SG_ BYTE11 : 88|8@1+ (1,0) [0|255] "" XXX
 SG_ BYTE12 : 96|8@1+ (1,0) [0|255] "" XXX
 SG_ BYTE13 : 104|8@1+ (1,0) [0|255] "" XXX
 SG_ BYTE14 : 112|8@1+ (1,0) [0|255] "" XXX
 SG_ BYTE15 : 120|8@1+ (1,0) [0|255] "" XXX
 SG_ BYTE16 : 128|8@1+ (1,0) [0|255] "" XXX
 SG_ BYTE17 : 136|8@1+ (1,0) [0|255] "" XXX
 SG_ BYTE18 : 144|8@1+ (1,0) [0|255] "" XXX
 SG_ BYTE19 : 152|8@1+ (1,0) [0|255] "" XXX
 SG_ BYTE20 : 160|8@1+ (1,0) [0|255] "" XXX
 SG_ BYTE21 : 168|8@1+ (1,0) [0|255] "" XXX
 SG_ BYTE22 : 176|8@1+ (1,0) [0|255] "" XXX
 SG_ BYTE23 : 184|8@1+ (1,0) [0|255] "" XXX

BO_ 949 RADAR_TRACK_949: 24 XXX
 SG_ BYTE0 : 0|8@1+ (1,0) [0|255] "" XXX
 SG_ BYTE1 : 8|8@1+ (1,0) [0|255] "" XXX
 SG_ BYTE2 : 16|8@1+ (1,0) [0|255] "" XXX
 SG_ BYTE3 : 24|8@1+ (1,0) [0|255] "" XXX
 SG_ BYTE4 : 32|8@1+ (1,0) [0|255] "" XXX
 SG_ BYTE5 : 40|8@1+ (1,0) [0|255] "" XXX
 SG_ BYTE6 : 48|8@1+ (1,0) [0|255] "" XXX
 SG_ BYTE7 : 56|8@1+ (1,0) [0|255] "" XXX
 SG_ BYTE8 : 64|8@1+ (1,0) [0|255] "" XXX
 SG_ BYTE9 : 72|8@1+ (1,0) [0|255] "" XXX
 SG_ BYTE10 : 80|8@1+ (1,0) [0|255] "" XXX
 SG_ BYTE11 : 88|8@1+ (1,0) [0|255] "" XXX
 SG_ BYTE12 : 96|8@1+ (1,0) [0|255] "" XXX
 SG_ BYTE13 : 104|8@1+ (1,0) [0|255] "" XXX
 SG_ BYTE14 : 112|8@1+ (1,0) [0|255] "" XXX
 SG_ BYTE15 : 120|8@1+ (1,0) [0|255] "" XXX
 SG_ BYTE16 : 128|8@1+ (1,0) [0|255] "" XXX
 SG_ BYTE17 : 136|8@1+ (1,0) [0|255] "" XXX
 SG_ BYTE18 : 144|8@1+ (1,0) [0|255] "" XXX
 SG_ BYTE19 : 152|8@1+ (1,0) [0|255] "" XXX
 SG_ BYTE20 : 160|8@1+ (1,0) [0|255] "" XXX
 SG_ BYTE21 : 168|8@1+ (1,0) [0|255] "" XXX
 SG_ BYTE22 : 176|8@1+ (1,0) [0|255] "" XXX
 SG_ BYTE23 : 184|8@1+ (1,0) [0|255] "" XXX

BO_ 950 RADAR_TRACK_950: 24 XXX
 SG_ BYTE0 : 0|8@1+ (1,0) [0|255] "" XXX
 SG_ BYTE1 : 8|8@1+ (1,0) [0|255] "" XXX
 SG_ BYTE2 : 16|8@1+ (1,0) [0|255] "" XXX
 SG_ BYTE3 : 24|8@1+ (1,0) [0|255] "" XXX
 SG_ BYTE4 : 32|8@1+ (1,0) [0|255] "" XXX
 SG_ BYTE5 : 40|8@1+ (1,0) [0|255] "" XXX
 SG_ BYTE6 : 48|8@1+ (1,0) [0|255] "" XXX
 SG_ BYTE7 : 56|8@1+ (1,0) [0|255] "" XXX
 SG_ BYTE8 : 64|8@1+ (1,0) [0|255] "" XXX
 SG_ BYTE9 : 72|8@1+ (1,0) [0|255] "" XXX
 SG_ BYTE10 : 80|8@1+ (1,0) [0|255] "" XXX
 SG_ BYTE11 : 88|8@1+ (1,0) [0|255] "" XXX
 SG_ BYTE12 : 96|8@1+ (1,0) [0|255] "" XXX
 SG_ BYTE13 : 104|8@1+ (1,0) [0|255] "" XXX
 SG_ BYTE14 : 112|8@1+ (1,0) [0|255] "" XXX
 SG_ BYTE15 : 120|8@1+ (1,0) [0|255] "" XXX
 SG_ BYTE16 : 128|8@1+ (1,0) [0|255] "" XXX
 SG_ BYTE17 : 136|8@1+ (1,0) [0|255] "" XXX
 SG_ BYTE18 : 144|8@1+ (1,0) [0|255] "" XXX
 SG_ BYTE19 : 152|8@1+ (1,0) [0|255] "" XXX
 SG_ BYTE20 : 160|8@1+ (1,0) [0|255] "" XXX
 SG_ BYTE21 : 168|8@1+ (1,0) [0|255] "" XXX
 SG_ BYTE22 : 176|8@1+ (1,0) [0|255] "" XXX
 SG_ BYTE23 : 184|8@1+ (1,0) [0|255] "" XXX

BO_ 951 RADAR_TRACK_951: 24 XXX
 SG_ BYTE0 : 0|8@1+ (1,0) [0|255] "" XXX
 SG_ BYTE1 : 8|8@1+ (1,0) [0|255] "" XXX
 SG_ BYTE2 : 16|8@1+ (1,0) [0|255] "" XXX
 SG_ BYTE3 : 24|8@1+ (1,0) [0|255] "" XXX
 SG_ BYTE4 : 32|8@1+ (1,0) [0|255] "" XXX
 SG_ BYTE5 : 40|8@1+ (1,0) [0|255] "" XXX
 SG_ BYTE6 : 48|8@1+ (1,0) [0|255] "" XXX
 SG_ BYTE7 : 56|8@1+ (1,0) [0|255] "" XXX
 SG_ BYTE8 : 64|8@1+ (1,0) [0|255] "" XXX
 SG_ BYTE9 : 72|8@1+ (1,0) [0|255] "" XXX
 SG_ BYTE10 : 80|8@1+ (1,0) [0|255] "" XXX
 SG_ BYTE11 : 88|8@1+ (1,0) [0|255] "" XXX
 SG_ BYTE12 : 96|8@1+ (1,0) [0|255] "" XXX
 SG_ BYTE13 : 104|8@1+ (1,0) [0|255] "" XXX
 SG_ BYTE14 : 112|8@1+ (1,0) [0|255] "" XXX
 SG_ BYTE15 : 120|8@1+ (1,0) [0|255] "" XXX
 SG_ BYTE16 : 128|8@1+ (1,0) [0|255] "" XXX
 SG_ BYTE17 : 136|8@1+ (1,0) [0|255] "" XXX
 SG_ BYTE18 : 144|8@1+ (1,0) [0|255] "" XXX
 SG_ BYTE19 : 152|8@1+ (1,0) [0|255] "" XXX
 SG_ BYTE20 : 160|8@1+ (1,0) [0|255] "" XXX
 SG_ BYTE21 : 168|8@1+ (1,0) [0|255] "" XXX
 SG_ BYTE22 : 176|8@1+ (1,0) [0|255] "" XXX
 SG_ BYTE23 : 184|8@1+ (1,0) [0|255] "" XXX

BO_ 952 RADAR_TRACK_952: 24 XXX
 SG_ BYTE0 : 0|8@1+ (1,0) [0|255] "" XXX
 SG_ BYTE1 : 8|8@1+ (1,0) [0|255] "" XXX
 SG_ BYTE2 : 16|8@1+ (1,0) [0|255] "" XXX
 SG_ BYTE3 : 24|8@1+ (1,0) [0|255] "" XXX
 SG_ BYTE4 : 32|8@1+ (1,0) [0|255] "" XXX
 SG_ BYTE5 : 40|8@1+ (1,0) [0|255] "" XXX
 SG_ BYTE6 : 48|8@1+ (1,0) [0|255] "" XXX
 SG_ BYTE7 : 56|8@1+ (1,0) [0|255] "" XXX
 SG_ BYTE8 : 64|8@1+ (1,0) [0|255] "" XXX
 SG_ BYTE9 : 72|8@1+ (1,0) [0|255] "" XXX
 SG_ BYTE10 : 80|8@1+ (1,0) [0|255] "" XXX
 SG_ BYTE11 : 88|8@1+ (1,0) [0|255] "" XXX
 SG_ BYTE12 : 96|8@1+ (1,0) [0|255] "" XXX
 SG_ BYTE13 : 104|8@1+ (1,0) [0|255] "" XXX
 SG_ BYTE14 : 112|8@1+ (1,0) [0|255] "" XXX
 SG_ BYTE15 : 120|8@1+ (1,0) [0|255] "" XXX
 SG_ BYTE16 : 128|8@1+ (1,0) [0|255] "" XXX
 SG_ BYTE17 : 136|8@1+ (1,0) [0|255] "" XXX
 SG_ BYTE18 : 144|8@1+ (1,0) [0|255] "" XXX
 SG_ BYTE19 : 152|8@1+ (1,0) [0|255] "" XXX
 SG_ BYTE20 : 160|8@1+ (1,0) [0|255] "" XXX
 SG_ BYTE21 : 168|8@1+ (1,0) [0|255] "" XXX
 SG_ BYTE22 : 176|8@1+ (1,0) [0|255] "" XXX
 SG_ BYTE23 : 184|8@1+ (1,0) [0|255] "" XXX

BO_ 953 RADAR_TRACK_953: 24 XXX
 SG_ BYTE0 : 0|8@1+ (1,0) [0|255] "" XXX
 SG_ BYTE1 : 8|8@1+ (1,0) [0|255] "" XXX
 SG_ BYTE2 : 16|8@1+ (1,0) [0|255] "" XXX
 SG_ BYTE3 : 24|8@1+ (1,0) [0|255] "" XXX
 SG_ BYTE4 : 32|8@1+ (1,0) [0|255] "" XXX
 SG_ BYTE5 : 40|8@1+ (1,0) [0|255] "" XXX
 SG_ BYTE6 : 48|8@1+ (1,0) [0|255] "" XXX
 SG_ BYTE7 : 56|8@1+ (1,0) [0|255] "" XXX
 SG_ BYTE8 : 64|8@1+ (1,0) [0|255] "" XXX
 SG_ BYTE9 : 72|8@1+ (1,0) [0|255] "" XXX
 SG_ BYTE10 : 80|8@1+ (1,0) [0|255] "" XXX
 SG_ BYTE11 : 88|8@1+ (1,0) [0|255] "" XXX
 SG_ BYTE12 : 96|8@1+ (1,0) [0|255] "" XXX
 SG_ BYTE13 : 104|8@1+ (1,0) [0|255] "" XXX
 SG_ BYTE14 : 112|8@1+ (1,0) [0|255] "" XXX
 SG_ BYTE15 : 120|8@1+ (1,0) [0|255] "" XXX
 SG_ BYTE16 : 128|8@1+ (1,0) [0|255] "" XXX
 SG_ BYTE17 : 136|8@1+ (1,0) [0|255] "" XXX
 SG_ BYTE18 : 144|8@1+ (1,0) [0|255] "" XXX
 SG_ BYTE19 : 152|8@1+ (1,0) [0|255] "" XXX
 SG_ BYTE20 : 160|8@1+ (1,0) [0|255] "" XXX
 SG_ BYTE21 : 168|8@1+ (1,0) [0|255] "" XXX
 SG_ BYTE22 : 176|8@1+ (1,0) [0|255] "" XXX
 SG_ BYTE23 : 184|8@1+ (1,0) [0|255] "" XXX

BO_ 954 RADAR_TRACK_954: 24 XXX
 SG_ BYTE0 : 0|8@1+ (1,0) [0|255] "" XXX
 SG_ BYTE1 : 8|8@1+ (1,0) [0|255] "" XXX
 SG_ BYTE2 : 16|8@1+ (1,0) [0|255] "" XXX
 SG_ BYTE3 : 24|8@1+ (1,0) [0|255] "" XXX
 SG_ BYTE4 : 32|8@1+ (1,0) [0|255] "" XXX
 SG_ BYTE5 : 40|8@1+ (1,0) [0|255] "" XXX
 SG_ BYTE6 : 48|8@1+ (1,0) [0|255] "" XXX
 SG_ BYTE7 : 56|8@1+ (1,0) [0|255] "" XXX
 SG_ BYTE8 : 64|8@1+ (1,0) [0|255] "" XXX
 SG_ BYTE9 : 72|8@1+ (1,0) [0|255] "" XXX
 SG_ BYTE10 : 80|8@1+ (1,0) [0|255] "" XXX
 SG_ BYTE11 : 88|8@1+ (1,0) [0|255] "" XXX
 SG_ BYTE12 : 96|8@1+ (1,0) [0|255] "" XXX
 SG_ BYTE13 : 104|8@1+ (1,0) [0|255] "" XXX
 SG_ BYTE14 : 112|8@1+ (1,0) [0|255] "" XXX
 SG_ BYTE15 : 120|8@1+ (1,0) [0|255] "" XXX
 SG_ BYTE16 : 128|8@1+ (1,0) [0|255] "" XXX
 SG_ BYTE17 : 136|8@1+ (1,0) [0|255] "" XXX
 SG_ BYTE18 : 144|8@1+ (1,0) [0|255] "" XXX
 SG_ BYTE19 : 152|8@1+ (1,0) [0|255] "" XXX
 SG_ BYTE20 : 160|8@1+ (1,0) [0|255] "" XXX
 SG_ BYTE21 : 168|8@1+ (1,0) [0|255] "" XXX
 SG_ BYTE22 : 176|8@1+ (1,0) [0|255] "" XXX
 SG_ BYTE23 : 184|8@1+ (1,0) [0|255] "" XXX

BO_ 955 RADAR_TRACK_955: 24 XXX
 SG_ BYTE0 : 0|8@1+ (1,0) [0|255] "" XXX
 SG_ BYTE1 : 8|8@1+ (1,0) [0|255] "" XXX
 SG_ BYTE2 : 16|8@1+ (1,0) [0|255] "" XXX
 SG_ BYTE3 : 24|8@1+ (1,0) [0|255] "" XXX
 SG_ BYTE4 : 32|8@1+ (1,0) [0|255] "" XXX
 SG_ BYTE5 : 40|8@1+ (1,0) [0|255] "" XXX
 SG_ BYTE6 : 48|8@1+ (1,0) [0|255] "" XXX
 SG_ BYTE7 : 56|8@1+ (1,0) [0|255] "" XXX
 SG_ BYTE8 : 64|8@1+ (1,0) [0|255] "" XXX
 SG_ BYTE9 : 72|8@1+ (1,0) [0|255] "" XXX
 SG_ BYTE10 : 80|8@1+ (1,0) [0|255] "" XXX
 SG_ BYTE11 : 88|8@1+ (1,0) [0|255] "" XXX
 SG_ BYTE12 : 96|8@1+ (1,0) [0|255] "" XXX
 SG_ BYTE13 : 104|8@1+ (1,0) [0|255] "" XXX
 SG_ BYTE14 : 112|8@1+ (1,0) [0|255] "" XXX
 SG_ BYTE15 : 120|8@1+ (1,0) [0|255] "" XXX
 SG_ BYTE16 : 128|8@1+ (1,0) [0|255] "" XXX
 SG_ BYTE17 : 136|8@1+ (1,0) [0|255] "" XXX
 SG_ BYTE18 : 144|8@1+ (1,0) [0|255] "" XXX
 SG_ BYTE19 : 152|8@1+ (1,0) [0|255] "" XXX
 SG_ BYTE20 : 160|8@1+ (1,0) [0|255] "" XXX
 SG_ BYTE21 : 168|8@1+ (1,0) [0|255] "" XXX
 SG_ BYTE22 : 176|8@1+ (1,0) [0|255] "" XXX
 SG_ BYTE23 : 184|8@1+ (1,0) [0|255] "" XXX

BO_ 956 RADAR_TRACK_956: 24 XXX
 SG_ BYTE0 : 0|8@1+ (1,0) [0|255] "" XXX
 SG_ BYTE1 : 8|8@1+ (1,0) [0|255] "" XXX
 SG_ BYTE2 : 16|8@1+ (1,0) [0|255] "" XXX
 SG_ BYTE3 : 24|8@1+ (1,0) [0|255] "" XXX
 SG_ BYTE4 : 32|8@1+ (1,0) [0|255] "" XXX
 SG_ BYTE5 : 40|8@1+ (1,0) [0|255] "" XXX
 SG_ BYTE6 : 48|8@1+ (1,0) [0|255] "" XXX
 SG_ BYTE7 : 56|8@1+ (1,0) [0|255] "" XXX
 SG_ BYTE8 : 64|8@1+ (1,0) [0|255] "" XXX
 SG_ BYTE9 : 72|8@1+ (1,0) [0|255] "" XXX
 SG_ BYTE10 : 80|8@1+ (1,0) [0|255] "" XXX
 SG_ BYTE11 : 88|8@1+ (1,0) [0|255] "" XXX
 SG_ BYTE12 : 96|8@1+ (1,0) [0|255] "" XXX
 SG_ BYTE13 : 104|8@1+ (1,0) [0|255] "" XXX
 SG_ BYTE14 : 112|8@1+ (1,0) [0|255] "" XXX
 SG_ BYTE15 : 120|8@1+ (1,0) [0|255] "" XXX
 SG_ BYTE16 : 128|8@1+ (1,0) [0|255] "" XXX
 SG_ BYTE17 : 136|8@1+ (1,0) [0|255] "" XXX
 SG_ BYTE18 : 144|8@1+ (1,0) [0|255] "" XXX
 SG_ BYTE19 : 152|8@1+ (1,0) [0|255] "" XXX
 SG_ BYTE20 : 160|8@1+ (1,0) [0|255] "" XXX
 SG_ BYTE21 : 168|8@1+ (1,0) [0|255] "" XXX
 SG_ BYTE22 : 176|8@1+ (1,0) [0|255] "" XXX
 SG_ BYTE23 : 184|8@1+ (1,0) [0|255] "" XXX

BO_ 957 RADAR_TRACK_957: 24 XXX
 SG_ BYTE0 : 0|8@1+ (1,0) [0|255] "" XXX
 SG_ BYTE1 : 8|8@1+ (1,0) [0|255] "" XXX
 SG_ BYTE2 : 16|8@1+ (1,0) [0|255] "" XXX
 SG_ BYTE3 : 24|8@1+ (1,0) [0|255] "" XXX
 SG_ BYTE4 : 32|8@1+ (1,0) [0|255] "" XXX
 SG_ BYTE5 : 40|8@1+ (1,0) [0|255] "" XXX
 SG_ BYTE6 : 48|8@1+ (1,0) [0|255] "" XXX
 SG_ BYTE7 : 56|8@1+ (1,0) [0|255] "" XXX
 SG_ BYTE8 : 64|8@1+ (1,0) [0|255] "" XXX
 SG_ BYTE9 : 72|8@1+ (1,0) [0|255] "" XXX
 SG_ BYTE10 : 80|8@1+ (1,0) [0|255] "" XXX
 SG_ BYTE11 : 88|8@1+ (1,0) [0|255] "" XXX
 SG_ BYTE12 : 96|8@1+ (1,0) [0|255] "" XXX
 SG_ BYTE13 : 104|8@1+ (1,0) [0|255] "" XXX
 SG_ BYTE14 : 112|8@1+ (1,0) [0|255] "" XXX
 SG_ BYTE15 : 120|8@1+ (1,0) [0|255] "" XXX
 SG_ BYTE16 : 128|8@1+ (1,0) [0|255] "" XXX
 SG_ BYTE17 : 136|8@1+ (1,0) [0|255] "" XXX
 SG_ BYTE18 : 144|8@1+ (1,0) [0|255] "" XXX
 SG_ BYTE19 : 152|8@1+ (1,0) [0|255] "" XXX
 SG_ BYTE20 : 160|8@1+ (1,0) [0|255] "" XXX
 SG_ BYTE21 : 168|8@1+ (1,0) [0|255] "" XXX
 SG_ BYTE22 : 176|8@1+ (1,0) [0|255] "" XXX
 SG_ BYTE23 : 184|8@1+ (1,0) [0|255] "" XXX

BO_ 958 RADAR_TRACK_958: 24 XXX
 SG_ BYTE0 : 0|8@1+ (1,0) [0|255] "" XXX
 SG_ BYTE1 : 8|8@1+ (1,0) [0|255] "" XXX
 SG_ BYTE2 : 16|8@1+ (1,0) [0|255] "" XXX
 SG_ BYTE3 : 24|8@1+ (1,0) [0|255] "" XXX
 SG_ BYTE4 : 32|8@1+ (1,0) [0|255] "" XXX
 SG_ BYTE5 : 40|8@1+ (1,0) [0|255] "" XXX
 SG_ BYTE6 : 48|8@1+ (1,0) [0|255] "" XXX
 SG_ BYTE7 : 56|8@1+ (1,0) [0|255] "" XXX
 SG_ BYTE8 : 64|8@1+ (1,0) [0|255] "" XXX
 SG_ BYTE9 : 72|8@1+ (1,0) [0|255] "" XXX
 SG_ BYTE10 : 80|8@1+ (1,0) [0|255] "" XXX
 SG_ BYTE11 : 88|8@1+ (1,0) [0|255] "" XXX
 SG_ BYTE12 : 96|8@1+ (1,0) [0|255] "" XXX
 SG_ BYTE13 : 104|8@1+ (1,0) [0|255] "" XXX
 SG_ BYTE14 : 112|8@1+ (1,0) [0|255] "" XXX
 SG_ BYTE15 : 120|8@1+ (1,0) [0|255] "" XXX
 SG_ BYTE16 : 128|8@1+ (1,0) [0|255] "" XXX
 SG_ BYTE17 : 136|8@1+ (1,0) [0|255] "" XXX
 SG_ BYTE18 : 144|8@1+ (1,0) [0|255] "" XXX
 SG_ BYTE19 : 152|8@1+ (1,0) [0|255] "" XXX
 SG_ BYTE20 : 160|8@1+ (1,0) [0|255] "" XXX
 SG_ BYTE21 : 168|8@1+ (1,0) [0|255] "" XXX
 SG_ BYTE22 : 176|8@1+ (1,0) [0|255] "" XXX
 SG_ BYTE23 : 184|8@1+ (1,0) [0|255] "" XXX

BO_ 959 RADAR_TRACK_959: 24 XXX
 SG_ BYTE0 : 0|8@1+ (1,0) [0|255] "" XXX
 SG_ BYTE1 : 8|8@1+ (1,0) [0|255] "" XXX
 SG_ BYTE2 : 16|8@1+ (1,0) [0|255] "" XXX
 SG_ BYTE3 : 24|8@1+ (1,0) [0|255] "" XXX
 SG_ BYTE4 : 32|8@1+ (1,0) [0|255] "" XXX
 SG_ BYTE5 : 40|8@1+ (1,0) [0|255] "" XXX
 SG_ BYTE6 : 48|8@1+ (1,0) [0|255] "" XXX
 SG_ BYTE7 : 56|8@1+ (1,0) [0|255] "" XXX
 SG_ BYTE8 : 64|8@1+ (1,0) [0|255] "" XXX
 SG_ BYTE9 : 72|8@1+ (1,0) [0|255] "" XXX
 SG_ BYTE10 : 80|8@1+ (1,0) [0|255] "" XXX
 SG_ BYTE11 : 88|8@1+ (1,0) [0|255] "" XXX
 SG_ BYTE12 : 96|8@1+ (1,0) [0|255] "" XXX
 SG_ BYTE13 : 104|8@1+ (1,0) [0|255] "" XXX
 SG_ BYTE14 : 112|8@1+ (1,0) [0|255] "" XXX
 SG_ BYTE15 : 120|8@1+ (1,0) [0|255] "" XXX
 SG_ BYTE16 : 128|8@1+ (1,0) [0|255] "" XXX
 SG_ BYTE17 : 136|8@1+ (1,0) [0|255] "" XXX
 SG_ BYTE18 : 144|8@1+ (1,0) [0|255] "" XXX
 SG_ BYTE19 : 152|8@1+ (1,0) [0|255] "" XXX
 SG_ BYTE20 : 160|8@1+ (1,0) [0|255] "" XXX
 SG_ BYTE21 : 168|8@1+ (1,0) [0|255] "" XXX
 SG_ BYTE22 : 176|8@1+ (1,0) [0|255] "" XXX
 SG_ BYTE23 : 184|8@1+ (1,0) [0|255] "" XXX

BO_ 960 RADAR_TRACK_960: 24 XXX
 SG_ BYTE0 : 0|8@1+ (1,0) [0|255] "" XXX
 SG_ BYTE1 : 8|8@1+ (1,0) [0|255] "" XXX
 SG_ BYTE2 : 16|8@1+ (1,0) [0|255] "" XXX
 SG_ BYTE3 : 24|8@1+ (1,0) [0|255] "" XXX
 SG_ BYTE4 : 32|8@1+ (1,0) [0|255] "" XXX
 SG_ BYTE5 : 40|8@1+ (1,0) [0|255] "" XXX
 SG_ BYTE6 : 48|8@1+ (1,0) [0|255] "" XXX
 SG_ BYTE7 : 56|8@1+ (1,0) [0|255] "" XXX
 SG_ BYTE8 : 64|8@1+ (1,0) [0|255] "" XXX
 SG_ BYTE9 : 72|8@1+ (1,0) [0|255] "" XXX
 SG_ BYTE10 : 80|8@1+ (1,0) [0|255] "" XXX
 SG_ BYTE11 : 88|8@1+ (1,0) [0|255] "" XXX
 SG_ BYTE12 : 96|8@1+ (1,0) [0|255] "" XXX
 SG_ BYTE13 : 104|8@1+ (1,0) [0|255] "" XXX
 SG_ BYTE14 : 112|8@1+ (1,0) [0|255] "" XXX
 SG_ BYTE15 : 120|8@1+ (1,0) [0|255] "" XXX
 SG_ BYTE16 : 128|8@1+ (1,0) [0|255] "" XXX
 SG_ BYTE17 : 136|8@1+ (1,0) [0|255] "" XXX
 SG_ BYTE18 : 144|8@1+ (1,0) [0|255] "" XXX
 SG_ BYTE19 : 152|8@1+ (1,0) [0|255] "" XXX
 SG_ BYTE20 : 160|8@1+ (1,0) [0|255] "" XXX
 SG_ BYTE21 : 168|8@1+ (1,0) [0|255] "" XXX
 SG_ BYTE22 : 176|8@1+ (1,0) [0|255] "" XXX
 SG_ BYTE23 : 184|8@1+ (1,0) [0|255] "" XXX

BO_ 962 RADAR_TRACK_962: 24 XXX
 SG_ BYTE0 : 0|8@1+ (1,0) [0|255] "" XXX
 SG_ BYTE1 : 8|8@1+ (1,0) [0|255] "" XXX
 SG_ BYTE2 : 16|8@1+ (1,0) [0|255] "" XXX
 SG_ BYTE3 : 24|8@1+ (1,0) [0|255] "" XXX
 SG_ BYTE4 : 32|8@1+ (1,0) [0|255] "" XXX
 SG_ BYTE5 : 40|8@1+ (1,0) [0|255] "" XXX
 SG_ BYTE6 : 48|8@1+ (1,0) [0|255] "" XXX
 SG_ BYTE7 : 56|8@1+ (1,0) [0|255] "" XXX
 SG_ BYTE8 : 64|8@1+ (1,0) [0|255] "" XXX
 SG_ BYTE9 : 72|8@1+ (1,0) [0|255] "" XXX
 SG_ BYTE10 : 80|8@1+ (1,0) [0|255] "" XXX
 SG_ BYTE11 : 88|8@1+ (1,0) [0|255] "" XXX
 SG_ BYTE12 : 96|8@1+ (1,0) [0|255] "" XXX
 SG_ BYTE13 : 104|8@1+ (1,0) [0|255] "" XXX
 SG_ BYTE14 : 112|8@1+ (1,0) [0|255] "" XXX
 SG_ BYTE15 : 120|8@1+ (1,0) [0|255] "" XXX
 SG_ BYTE16 : 128|8@1+ (1,0) [0|255] "" XXX
 SG_ BYTE17 : 136|8@1+ (1,0) [0|255] "" XXX
 SG_ BYTE18 : 144|8@1+ (1,0) [0|255] "" XXX
 SG_ BYTE19 : 152|8@1+ (1,0) [0|255] "" XXX
 SG_ BYTE20 : 160|8@1+ (1,0) [0|255] "" XXX
 SG_ BYTE21 : 168|8@1+ (1,0) [0|255] "" XXX
 SG_ BYTE22 : 176|8@1+ (1,0) [0|255] "" XXX
 SG_ BYTE23 : 184|8@1+ (1,0) [0|255] "" XXX

BO_ 963 RADAR_TRACK_963: 24 XXX
 SG_ BYTE0 : 0|8@1+ (1,0) [0|255] "" XXX
 SG_ BYTE1 : 8|8@1+ (1,0) [0|255] "" XXX
 SG_ BYTE2 : 16|8@1+ (1,0) [0|255] "" XXX
 SG_ BYTE3 : 24|8@1+ (1,0) [0|255] "" XXX
 SG_ BYTE4 : 32|8@1+ (1,0) [0|255] "" XXX
 SG_ BYTE5 : 40|8@1+ (1,0) [0|255] "" XXX
 SG_ BYTE6 : 48|8@1+ (1,0) [0|255] "" XXX
 SG_ BYTE7 : 56|8@1+ (1,0) [0|255] "" XXX
 SG_ BYTE8 : 64|8@1+ (1,0) [0|255] "" XXX
 SG_ BYTE9 : 72|8@1+ (1,0) [0|255] "" XXX
 SG_ BYTE10 : 80|8@1+ (1,0) [0|255] "" XXX
 SG_ BYTE11 : 88|8@1+ (1,0) [0|255] "" XXX
 SG_ BYTE12 : 96|8@1+ (1,0) [0|255] "" XXX
 SG_ BYTE13 : 104|8@1+ (1,0) [0|255] "" XXX
 SG_ BYTE14 : 112|8@1+ (1,0) [0|255] "" XXX
 SG_ BYTE15 : 120|8@1+ (1,0) [0|255] "" XXX
 SG_ BYTE16 : 128|8@1+ (1,0) [0|255] "" XXX
 SG_ BYTE17 : 136|8@1+ (1,0) [0|255] "" XXX
 SG_ BYTE18 : 144|8@1+ (1,0) [0|255] "" XXX
 SG_ BYTE19 : 152|8@1+ (1,0) [0|255] "" XXX
 SG_ BYTE20 : 160|8@1+ (1,0) [0|255] "" XXX
 SG_ BYTE21 : 168|8@1+ (1,0) [0|255] "" XXX
 SG_ BYTE22 : 176|8@1+ (1,0) [0|255] "" XXX
 SG_ BYTE23 : 184|8@1+ (1,0) [0|255] "" XXX

BO_ 964 RADAR_TRACK_964: 24 XXX
 SG_ BYTE0 : 0|8@1+ (1,0) [0|255] "" XXX
 SG_ BYTE1 : 8|8@1+ (1,0) [0|255] "" XXX
 SG_ BYTE2 : 16|8@1+ (1,0) [0|255] "" XXX
 SG_ BYTE3 : 24|8@1+ (1,0) [0|255] "" XXX
 SG_ BYTE4 : 32|8@1+ (1,0) [0|255] "" XXX
 SG_ BYTE5 : 40|8@1+ (1,0) [0|255] "" XXX
 SG_ BYTE6 : 48|8@1+ (1,0) [0|255] "" XXX
 SG_ BYTE7 : 56|8@1+ (1,0) [0|255] "" XXX
 SG_ BYTE8 : 64|8@1+ (1,0) [0|255] "" XXX
 SG_ BYTE9 : 72|8@1+ (1,0) [0|255] "" XXX
 SG_ BYTE10 : 80|8@1+ (1,0) [0|255] "" XXX
 SG_ BYTE11 : 88|8@1+ (1,0) [0|255] "" XXX
 SG_ BYTE12 : 96|8@1+ (1,0) [0|255] "" XXX
 SG_ BYTE13 : 104|8@1+ (1,0) [0|255] "" XXX
 SG_ BYTE14 : 112|8@1+ (1,0) [0|255] "" XXX
 SG_ BYTE15 : 120|8@1+ (1,0) [0|255] "" XXX
 SG_ BYTE16 : 128|8@1+ (1,0) [0|255] "" XXX
 SG_ BYTE17 : 136|8@1+ (1,0) [0|255] "" XXX
 SG_ BYTE18 : 144|8@1+ (1,0) [0|255] "" XXX
 SG_ BYTE19 : 152|8@1+ (1,0) [0|255] "" XXX
 SG_ BYTE20 : 160|8@1+ (1,0) [0|255] "" XXX
 SG_ BYTE21 : 168|8@1+ (1,0) [0|255] "" XXX
 SG_ BYTE22 : 176|8@1+ (1,0) [0|255] "" XXX
 SG_ BYTE23 : 184|8@1+ (1,0) [0|255] "" XXX

BO_ 81 ADRV_0x51: 16 XXX
 SG_ BYTE0 : 0|8@1+ (1,0) [0|255] "" XXX
 SG_ BYTE1 : 8|8@1+ (1,0) [0|255] "" XXX
 SG_ BYTE2 : 16|8@1+ (1,0) [0|255] "" XXX
 SG_ BYTE3 : 24|8@1+ (1,0) [0|255] "" XXX
 SG_ BYTE4 : 32|8@1+ (1,0) [0|255] "" XXX
 SG_ BYTE5 : 40|8@1+ (1,0) [0|255] "" XXX
 SG_ BYTE6 : 48|8@1+ (1,0) [0|255] "" XXX
 SG_ BYTE7 : 56|8@1+ (1,0) [0|255] "" XXX
 SG_ BYTE8 : 64|8@1+ (1,0) [0|255] "" XXX
 SG_ BYTE9 : 72|8@1+ (1,0) [0|255] "" XXX
 SG_ BYTE10 : 80|8@1+ (1,0) [0|255] "" XXX
 SG_ BYTE11 : 88|8@1+ (1,0) [0|255] "" XXX
 SG_ BYTE12 : 96|8@1+ (1,0) [0|255] "" XXX
 SG_ BYTE13 : 104|8@1+ (1,0) [0|255] "" XXX
 SG_ BYTE14 : 112|8@1+ (1,0) [0|255] "" XXX
 SG_ BYTE15 : 120|8@1+ (1,0) [0|255] "" XXX

BO_ 298 LFA: 32 XXX
 SG_ LKA_MODE : 24|4@1+ (1,0) [0|15] "" XXX
 SG_ LKA_ICON : 28|4@1+ (1,0) [0|15] "" XXX
 SG_ TORQUE_REQUEST : 32|11@1- (1,0) [-1024|1023] "" XXX
 SG_ LKA_ASSIST : 43|1@1+ (1,0) [0|1] "" XXX
 SG_ STEER_REQ : 44|1@1+ (1,0) [0|1] "" XXX
 SG_ STEER_MODE : 45|3@1+ (1,0) [0|7] "" XXX
 SG_ HAS_LANE_SAFETY : 48|1@1+ (1,0) [0|1] "" XXX
 SG_ LKA_AVAILABLE : 27|2@1+ (1,0) [0|3] "" XXX
 SG_ CHECKSUM : 0|16@1+ (1,0) [0|65535] "" XXX
 SG_ COUNTER : 16|8@1+ (1,0) [0|255] "" XXX
 SG_ BYTE7 : 56|8@1+ (1,0) [0|255] "" XXX
 SG_ BYTE8 : 64|8@1+ (1,0) [0|255] "" XXX
 SG_ BYTE9 : 72|8@1+ (1,0) [0|255] "" XXX
 SG_ BYTE10 : 80|8@1+ (1,0) [0|255] "" XXX
 SG_ BYTE11 : 88|8@1+ (1,0) [0|255] "" XXX
 SG_ BYTE12 : 96|8@1+ (1,0) [0|255] "" XXX
 SG_ BYTE13 : 104|8@1+ (1,0) [0|255] "" XXX
 SG_ BYTE14 : 112|8@1+ (1,0) [0|255] "" XXX
 SG_ BYTE15 : 120|8@1+ (1,0) [0|255] "" XXX
 SG_ BYTE16 : 128|8@1+ (1,0) [0|255] "" XXX
 SG_ BYTE17 : 136|8@1+ (1,0) [0|255] "" XXX
 SG_ BYTE18 : 144|8@1+ (1,0) [0|255] "" XXX
 SG_ BYTE19 : 152|8@1+ (1,0) [0|255] "" XXX
 SG_ BYTE20 : 160|8@1+ (1,0) [0|255] "" XXX
 SG_ BYTE21 : 168|8@1+ (1,0) [0|255] "" XXX
 SG_ BYTE22 : 176|8@1+ (1,0) [0|255] "" XXX
 SG_ BYTE23 : 184|8@1+ (1,0) [0|255] "" XXX
 SG_ BYTE24 : 192|8@1+ (1,0) [0|255] "" XXX
 SG_ BYTE25 : 200|8@1+ (1,0) [0|255] "" XXX
 SG_ BYTE26 : 208|8@1+ (1,0) [0|255] "" XXX
 SG_ BYTE27 : 216|8@1+ (1,0) [0|255] "" XXX
 SG_ BYTE28 : 224|8@1+ (1,0) [0|255] "" XXX
 SG_ BYTE29 : 232|8@1+ (1,0) [0|255] "" XXX
 SG_ BYTE30 : 240|8@1+ (1,0) [0|255] "" XXX
 SG_ BYTE31 : 248|8@1+ (1,0) [0|255] "" XXX

BO_ 352 ADRV_0x160: 16 XXX
 SG_ BYTE0 : 0|8@1+ (1,0) [0|255] "" XXX
 SG_ BYTE1 : 8|8@1+ (1,0) [0|255] "" XXX
 SG_ BYTE2 : 16|8@1+ (1,0) [0|255] "" XXX
 SG_ BYTE3 : 24|8@1+ (1,0) [0|255] "" XXX
 SG_ BYTE4 : 32|8@1+ (1,0) [0|255] "" XXX
 SG_ BYTE5 : 40|8@1+ (1,0) [0|255] "" XXX
 SG_ BYTE6 : 48|8@1+ (1,0) [0|255] "" XXX
 SG_ BYTE7 : 56|8@1+ (1,0) [0|255] "" XXX
 SG_ BYTE8 : 64|8@1+ (1,0) [0|255] "" XXX
 SG_ BYTE9 : 72|8@1+ (1,0) [0|255] "" XXX
 SG_ BYTE10 : 80|8@1+ (1,0) [0|255] "" XXX
 SG_ BYTE11 : 88|8@1+ (1,0) [0|255] "" XXX
 SG_ BYTE12 : 96|8@1+ (1,0) [0|255] "" XXX
 SG_ BYTE13 : 104|8@1+ (1,0) [0|255] "" XXX
 SG_ BYTE14 : 112|8@1+ (1,0) [0|255] "" XXX
 SG_ BYTE15 : 120|8@1+ (1,0) [0|255] "" XXX

BO_ 474 ADRV_0x1da: 16 XXX
 SG_ BYTE0 : 0|8@1+ (1,0) [0|255] "" XXX
 SG_ BYTE1 : 8|8@1+ (1,0) [0|255] "" XXX
 SG_ BYTE2 : 16|8@1+ (1,0) [0|255] "" XXX
 SG_ BYTE3 : 24|8@1+ (1,0) [0|255] "" XXX
 SG_ BYTE4 : 32|8@1+ (1,0) [0|255] "" XXX
 SG_ BYTE5 : 40|8@1+ (1,0) [0|255] "" XXX
 SG_ BYTE6 : 48|8@1+ (1,0) [0|255] "" XXX
 SG_ BYTE7 : 56|8@1+ (1,0) [0|255] "" XXX
 SG_ BYTE8 : 64|8@1+ (1,0) [0|255] "" XXX
 SG_ BYTE9 : 72|8@1+ (1,0) [0|255] "" XXX
 SG_ BYTE10 : 80|8@1+ (1,0) [0|255] "" XXX
 SG_ BYTE11 : 88|8@1+ (1,0) [0|255] "" XXX
 SG_ BYTE12 : 96|8@1+ (1,0) [0|255] "" XXX
 SG_ BYTE13 : 104|8@1+ (1,0) [0|255] "" XXX
 SG_ BYTE14 : 112|8@1+ (1,0) [0|255] "" XXX
 SG_ BYTE15 : 120|8@1+ (1,0) [0|255] "" XXX

BO_ 480 LFAHDA_CLUSTER: 32 XXX
 SG_ HDA_ICON : 24|2@1+ (1,0) [0|3] "" XXX
 SG_ LFA_ICON : 28|2@1+ (1,0) [0|3] "" XXX
 SG_ CHECKSUM : 0|16@1+ (1,0) [0|65535] "" XXX
 SG_ COUNTER : 16|8@1+ (1,0) [0|255] "" XXX
 SG_ BYTE4 : 32|8@1+ (1,0) [0|255] "" XXX
 SG_ BYTE5 : 40|8@1+ (1,0) [0|255] "" XXX
 SG_ BYTE6 : 48|8@1+ (1,0) [0|255] "" XXX
 SG_ BYTE7 : 56|8@1+ (1,0) [0|255] "" XXX
 SG_ BYTE8 : 64|8@1+ (1,0) [0|255] "" XXX
 SG_ BYTE9 : 72|8@1+ (1,0) [0|255] "" XXX
 SG_ BYTE10 : 80|8@1+ (1,0) [0|255] "" XXX
 SG_ BYTE11 : 88|8@1+ (1,0) [0|255] "" XXX
 SG_ BYTE12 : 96|8@1+ (1,0) [0|255] "" XXX
 SG_ BYTE13 : 104|8@1+ (1,0) [0|255] "" XXX
 SG_ BYTE14 : 112|8@1+ (1,0) [0|255] "" XXX
 SG_ BYTE15 : 120|8@1+ (1,0) [0|255] "" XXX
 SG_ BYTE16 : 128|8@1+ (1,0) [0|255] "" XXX
 SG_ BYTE17 : 136|8@1+ (1,0) [0|255] "" XXX
 SG_ BYTE18 : 144|8@1+ (1,0) [0|255] "" XXX
 SG_ BYTE19 : 152|8@1+ (1,0) [0|255] "" XXX
 SG_ BYTE20 : 160|8@1+ (1,0) [0|255] "" XXX
 SG_ BYTE21 : 168|8@1+ (1,0) [0|255] "" XXX
 SG_ BYTE22 : 176|8@1+ (1,0) [0|255] "" XXX
 SG_ BYTE23 : 184|8@1+ (1,0) [0|255] "" XXX
 SG_ BYTE24 : 192|8@1+ (1,0) [0|255] "" XXX
 SG_ BYTE25 : 200|8@1+ (1,0) [0|255] "" XXX
 SG_ BYTE26 : 208|8@1+ (1,0) [0|255] "" XXX
 SG_ BYTE27 : 216|8@1+ (1,0) [0|255] "" XXX
 SG_ BYTE28 : 224|8@1+ (1,0) [0|255] "" XXX
 SG_ BYTE29 : 232|8@1+ (1,0) [0|255] "" XXX
 SG_ BYTE30 : 240|8@1+ (1,0) [0|255] "" XXX
 SG_ BYTE31 : 248|8@1+ (1,0) [0|255] "" XXX

BO_ 490 ADRV_0x1ea: 32 XXX
 SG_ BYTE0 : 0|8@1+ (1,0) [0|255] "" XXX
 SG_ BYTE1 : 8|8@1+ (1,0) [0|255] "" XXX
 SG_ BYTE2 : 16|8@1+ (1,0) [0|255] "" XXX
 SG_ BYTE3 : 24|8@1+ (1,0) [0|255] "" XXX
 SG_ BYTE4 : 32|8@1+ (1,0) [0|255] "" XXX
 SG_ BYTE5 : 40|8@1+ (1,0) [0|255] "" XXX
 SG_ BYTE6 : 48|8@1+ (1,0) [0|255] "" XXX
 SG_ BYTE7 : 56|8@1+ (1,0) [0|255] "" XXX
 SG_ BYTE8 : 64|8@1+ (1,0) [0|255] "" XXX
 SG_ BYTE9 : 72|8@1+ (1,0) [0|255] "" XXX
 SG_ BYTE10 : 80|8@1+ (1,0) [0|255] "" XXX
 SG_ BYTE11 : 88|8@1+ (1,0) [0|255] "" XXX
 SG_ BYTE12 : 96|8@1+ (1,0) [0|255] "" XXX
 SG_ BYTE13 : 104|8@1+ (1,0) [0|255] "" XXX
 SG_ BYTE14 : 112|8@1+ (1,0) [0|255] "" XXX
 SG_ BYTE15 : 120|8@1+ (1,0) [0|255] "" XXX
 SG_ BYTE16 : 128|8@1+ (1,0) [0|255] "" XXX
 SG_ BYTE17 : 136|8@1+ (1,0) [0|255] "" XXX
 SG_ BYTE18 : 144|8@1+ (1,0) [0|255] "" XXX
 SG_ BYTE19 : 152|8@1+ (1,0) [0|255] "" XXX
 SG_ BYTE20 : 160|8@1+ (1,0) [0|255] "" XXX
 SG_ BYTE21 : 168|8@1+ (1,0) [0|255] "" XXX
 SG_ BYTE22 : 176|8@1+ (1,0) [0|255] "" XXX
 SG_ BYTE23 : 184|8@1+ (1,0) [0|255] "" XXX
 SG_ BYTE24 : 192|8@1+ (1,0) [0|255] "" XXX
 SG_ BYTE25 : 200|8@1+ (1,0) [0|255] "" XXX
 SG_ BYTE26 : 208|8@1+ (1,0) [0|255] "" XXX
 SG_ BYTE27 : 216|8@1+ (1,0) [0|255] "" XXX
 SG_ BYTE28 : 224|8@1+ (1,0) [0|255] "" XXX
 SG_ BYTE29 : 232|8@1+ (1,0) [0|255] "" XXX
 SG_ BYTE30 : 240|8@1+ (1,0) [0|255] "" XXX
 SG_ BYTE31 : 248|8@1+ (1,0) [0|255] "" XXX

BO_ 512 ADRV_0x200: 16 XXX
 SG_ BYTE0 : 0|8@1+ (1,0) [0|255] "" XXX
 SG_ BYTE1 : 8|8@1+ (1,0) [0|255] "" XXX
 SG_ BYTE2 : 16|8@1+ (1,0) [0|255] "" XXX
 SG_ BYTE3 : 24|8@1+ (1,0) [0|255] "" XXX
 SG_ BYTE4 : 32|8@1+ (1,0) [0|255] "" XXX
 SG_ BYTE5 : 40|8@1+ (1,0) [0|255] "" XXX
 SG_ BYTE6 : 48|8@1+ (1,0) [0|255] "" XXX
 SG_ BYTE7 : 56|8@1+ (1,0) [0|255] "" XXX
 SG_ BYTE8 : 64|8@1+ (1,0) [0|255] "" XXX
 SG_ BYTE9 : 72|8@1+ (1,0) [0|255] "" XXX
 SG_ BYTE10 : 80|8@1+ (1,0) [0|255] "" XXX
 SG_ BYTE11 : 88|8@1+ (1,0) [0|255] "" XXX
 SG_ BYTE12 : 96|8@1+ (1,0) [0|255] "" XXX
 SG_ BYTE13 : 104|8@1+ (1,0) [0|255] "" XXX
 SG_ BYTE14 : 112|8@1+ (1,0) [0|255] "" XXX
 SG_ BYTE15 : 120|8@1+ (1,0) [0|255] "" XXX

BO_ 837 ADRV_0x345: 16 XXX
 SG_ BYTE0 : 0|8@1+ (1,0) [0|255] "" XXX
 SG_ BYTE1 : 8|8@1+ (1,0) [0|255] "" XXX
 SG_ BYTE2 : 16|8@1+ (1,0) [0|255] "" XXX
 SG_ BYTE3 : 24|8@1+ (1,0) [0|255] "" XXX
 SG_ BYTE4 : 32|8@1+ (1,0) [0|255] "" XXX
 SG_ BYTE5 : 40|8@1+ (1,0) [0|255] "" XXX
 SG_ BYTE6 : 48|8@1+ (1,0) [0|255] "" XXX
 SG_ BYTE7 : 56|8@1+ (1,0) [0|255] "" XXX
 SG_ BYTE8 : 64|8@1+ (1,0) [0|255] "" XXX
 SG_ BYTE9 : 72|8@1+ (1,0) [0|255] "" XXX
 SG_ BYTE10 : 80|8@1+ (1,0) [0|255] "" XXX
 SG_ BYTE11 : 88|8@1+ (1,0) [0|255] "" XXX
 SG_ BYTE12 : 96|8@1+ (1,0) [0|255] "" XXX
 SG_ BYTE13 : 104|8@1+ (1,0) [0|255] "" XXX
 SG_ BYTE14 : 112|8@1+ (1,0) [0|255] "" XXX
 SG_ BYTE15 : 120|8@1+ (1,0) [0|255] "" XXX

BO_ 905 ADRV_0x389: 24 XXX
 SG_ BYTE0 : 0|8@1+ (1,0) [0|255] "" XXX
 SG_ BYTE1 : 8|8@1+ (1,0) [0|255] "" XXX
 SG_ BYTE2 : 16|8@1+ (1,0) [0|255] "" XXX
 SG_ BYTE3 : 24|8@1+ (1,0) [0|255] "" XXX
 SG_ BYTE4 : 32|8@1+ (1,0) [0|255] "" XXX
 SG_ BYTE5 : 40|8@1+ (1,0) [0|255] "" XXX
 SG_ BYTE6 : 48|8@1+ (1,0) [0|255] "" XXX
 SG_ BYTE7 : 56|8@1+ (1,0) [0|255] "" XXX
 SG_ BYTE8 : 64|8@1+ (1,0) [0|255] "" XXX
 SG_ BYTE9 : 72|8@1+ (1,0) [0|255] "" XXX
 SG_ BYTE10 : 80|8@1+ (1,0) [0|255] "" XXX
 SG_ BYTE11 : 88|8@1+ (1,0) [0|255] "" XXX
 SG_ BYTE12 : 96|8@1+ (1,0) [0|255] "" XXX
 SG_ BYTE13 : 104|8@1+ (1,0) [0|255] "" XXX
 SG_ BYTE14 : 112|8@1+ (1,0) [0|255] "" XXX
 SG_ BYTE15 : 120|8@1+ (1,0) [0|255] "" XXX
 SG_ BYTE16 : 128|8@1+ (1,0) [0|255] "" XXX
 SG_ BYTE17 : 136|8@1+ (1,0) [0|255] "" XXX
 SG_ BYTE18 : 144|8@1+ (1,0) [0|255] "" XXX
 SG_ BYTE19 : 152|8@1+ (1,0) [0|255] "" XXX
 SG_ BYTE20 : 160|8@1+ (1,0) [0|255] "" XXX
 SG_ BYTE21 : 168|8@1+ (1,0) [0|255] "" XXX
 SG_ BYTE22 : 176|8@1+ (1,0) [0|255] "" XXX
 SG_ BYTE23 : 184|8@1+ (1,0) [0|255] "" XXX

BO_ 896 ADRV_0x380: 24 XXX
 SG_ BYTE0 : 0|8@1+ (1,0) [0|255] "" XXX
 SG_ BYTE1 : 8|8@1+ (1,0) [0|255] "" XXX
 SG_ BYTE2 : 16|8@1+ (1,0) [0|255] "" XXX
 SG_ BYTE3 : 24|8@1+ (1,0) [0|255] "" XXX
 SG_ BYTE4 : 32|8@1+ (1,0) [0|255] "" XXX
 SG_ BYTE5 : 40|8@1+ (1,0) [0|255] "" XXX
 SG_ BYTE6 : 48|8@1+ (1,0) [0|255] "" XXX
 SG_ BYTE7 : 56|8@1+ (1,0) [0|255] "" XXX
 SG_ BYTE8 : 64|8@1+ (1,0) [0|255] "" XXX
 SG_ BYTE9 : 72|8@1+ (1,0) [0|255] "" XXX
 SG_ BYTE10 : 80|8@1+ (1,0) [0|255] "" XXX
 SG_ BYTE11 : 88|8@1+ (1,0) [0|255] "" XXX
 SG_ BYTE12 : 96|8@1+ (1,0) [0|255] "" XXX
 SG_ BYTE13 : 104|8@1+ (1,0) [0|255] "" XXX
 SG_ BYTE14 : 112|8@1+ (1,0) [0|255] "" XXX
 SG_ BYTE15 : 120|8@1+ (1,0) [0|255] "" XXX
 SG_ BYTE16 : 128|8@1+ (1,0) [0|255] "" XXX
 SG_ BYTE17 : 136|8@1+ (1,0) [0|255] "" XXX
 SG_ BYTE18 : 144|8@1+ (1,0) [0|255] "" XXX
 SG_ BYTE19 : 152|8@1+ (1,0) [0|255] "" XXX
 SG_ BYTE20 : 160|8@1+ (1,0) [0|255] "" XXX
 SG_ BYTE21 : 168|8@1+ (1,0) [0|255] "" XXX
 SG_ BYTE22 : 176|8@1+ (1,0) [0|255] "" XXX
 SG_ BYTE23 : 184|8@1+ (1,0) [0|255] "" XXX

BO_ 442 BLINDSPOTS_REAR_CORNERS: 24 XXX
 SG_ CHECKSUM : 0|16@1+ (1,0) [0|65535] "" XXX
 SG_ COUNTER : 16|8@1+ (1,0) [0|255] "" XXX
 SG_ LEFT_BLOCKED : 24|1@0+ (1,0) [0|1] "" XXX
 SG_ LEFT_MB : 30|1@0+ (1,0) [0|3] "" XXX
 SG_ MORE_LEFT_PROB : 32|1@1+ (1,0) [0|3] "" XXX
 SG_ FL_INDICATOR : 46|6@0+ (1,0) [0|1] "" XXX
 SG_ FR_INDICATOR : 54|6@0+ (1,0) [0|63] "" XXX
 SG_ RIGHT_BLOCKED : 64|1@0+ (1,0) [0|1] "" XXX
 SG_ COLLISION_AVOIDANCE_ACTIVE : 68|1@0+ (1,0) [0|1] "" XXX
 SG_ NEW_SIGNAL_2 : 96|1@0+ (1,0) [0|1] "" XXX
 SG_ FL_INDICATOR_ALT : 138|1@0+ (1,0) [0|1] "" XXX
 SG_ FR_INDICATOR_ALT : 141|1@0+ (1,0) [0|1] "" XXX

BO_ 282 FR_CMR_01_10ms: 16 XXX
 SG_ BYTE0 : 0|8@1+ (1,0) [0|255] "" XXX
 SG_ BYTE1 : 8|8@1+ (1,0) [0|255] "" XXX
 SG_ BYTE2 : 16|8@1+ (1,0) [0|255] "" XXX
 SG_ BYTE3 : 24|8@1+ (1,0) [0|255] "" XXX
 SG_ BYTE4 : 32|8@1+ (1,0) [0|255] "" XXX
 SG_ BYTE5 : 40|8@1+ (1,0) [0|255] "" XXX
 SG_ BYTE6 : 48|8@1+ (1,0) [0|255] "" XXX
 SG_ BYTE7 : 56|8@1+ (1,0) [0|255] "" XXX
 SG_ BYTE8 : 64|8@1+ (1,0) [0|255] "" XXX
 SG_ BYTE9 : 72|8@1+ (1,0) [0|255] "" XXX
 SG_ BYTE10 : 80|8@1+ (1,0) [0|255] "" XXX
 SG_ BYTE11 : 88|8@1+ (1,0) [0|255] "" XXX
 SG_ BYTE12 : 96|8@1+ (1,0) [0|255] "" XXX
 SG_ BYTE13 : 104|8@1+ (1,0) [0|255] "" XXX
 SG_ BYTE14 : 112|8@1+ (1,0) [0|255] "" XXX
 SG_ BYTE15 : 120|8@1+ (1,0) [0|255] "" XXX

BO_ 437 CAMERA_0x1b5: 32 XXX
 SG_ BYTE0 : 0|8@1+ (1,0) [0|255] "" XXX
 SG_ BYTE1 : 8|8@1+ (1,0) [0|255] "" XXX
 SG_ BYTE2 : 16|8@1+ (1,0) [0|255] "" XXX
 SG_ BYTE3 : 24|8@1+ (1,0) [0|255] "" XXX
 SG_ BYTE4 : 32|8@1+ (1,0) [0|255] "" XXX
 SG_ BYTE5 : 40|8@1+ (1,0) [0|255] "" XXX
 SG_ BYTE6 : 48|8@1+ (1,0) [0|255] "" XXX
 SG_ BYTE7 : 56|8@1+ (1,0) [0|255] "" XXX
 SG_ BYTE8 : 64|8@1+ (1,0) [0|255] "" XXX
 SG_ BYTE9 : 72|8@1+ (1,0) [0|255] "" XXX
 SG_ BYTE10 : 80|8@1+ (1,0) [0|255] "" XXX
 SG_ BYTE11 : 88|8@1+ (1,0) [0|255] "" XXX
 SG_ BYTE12 : 96|8@1+ (1,0) [0|255] "" XXX
 SG_ BYTE13 : 104|8@1+ (1,0) [0|255] "" XXX
 SG_ BYTE14 : 112|8@1+ (1,0) [0|255] "" XXX
 SG_ BYTE15 : 120|8@1+ (1,0) [0|255] "" XXX
 SG_ BYTE16 : 128|8@1+ (1,0) [0|255] "" XXX
 SG_ BYTE17 : 136|8@1+ (1,0) [0|255] "" XXX
 SG_ BYTE18 : 144|8@1+ (1,0) [0|255] "" XXX
 SG_ BYTE19 : 152|8@1+ (1,0) [0|255] "" XXX
 SG_ BYTE20 : 160|8@1+ (1,0) [0|255] "" XXX
 SG_ BYTE21 : 168|8@1+ (1,0) [0|255] "" XXX
 SG_ BYTE22 : 176|8@1+ (1,0) [0|255] "" XXX
 SG_ BYTE23 : 184|8@1+ (1,0) [0|255] "" XXX
 SG_ BYTE24 : 192|8@1+ (1,0) [0|255] "" XXX
 SG_ BYTE25 : 200|8@1+ (1,0) [0|255] "" XXX
 SG_ BYTE26 : 208|8@1+ (1,0) [0|255] "" XXX
 SG_ BYTE27 : 216|8@1+ (1,0) [0|255] "" XXX
 SG_ BYTE28 : 224|8@1+ (1,0) [0|255] "" XXX
 SG_ BYTE29 : 232|8@1+ (1,0) [0|255] "" XXX
 SG_ BYTE30 : 240|8@1+ (1,0) [0|255] "" XXX
 SG_ BYTE31 : 248|8@1+ (1,0) [0|255] "" XXX

BO_ 698 IFS_0x2ba: 32 XXX
 SG_ BYTE0 : 0|8@1+ (1,0) [0|255] "" XXX
 SG_ BYTE1 : 8|8@1+ (1,0) [0|255] "" XXX
 SG_ BYTE2 : 16|8@1+ (1,0) [0|255] "" XXX
 SG_ BYTE3 : 24|8@1+ (1,0) [0|255] "" XXX
 SG_ BYTE4 : 32|8@1+ (1,0) [0|255] "" XXX
 SG_ BYTE5 : 40|8@1+ (1,0) [0|255] "" XXX
 SG_ BYTE6 : 48|8@1+ (1,0) [0|255] "" XXX
 SG_ BYTE7 : 56|8@1+ (1,0) [0|255] "" XXX
 SG_ BYTE8 : 64|8@1+ (1,0) [0|255] "" XXX
 SG_ BYTE9 : 72|8@1+ (1,0) [0|255] "" XXX
 SG_ BYTE10 : 80|8@1+ (1,0) [0|255] "" XXX
 SG_ BYTE11 : 88|8@1+ (1,0) [0|255] "" XXX
 SG_ BYTE12 : 96|8@1+ (1,0) [0|255] "" XXX
 SG_ BYTE13 : 104|8@1+ (1,0) [0|255] "" XXX
 SG_ BYTE14 : 112|8@1+ (1,0) [0|255] "" XXX
 SG_ BYTE15 : 120|8@1+ (1,0) [0|255] "" XXX
 SG_ BYTE16 : 128|8@1+ (1,0) [0|255] "" XXX
 SG_ BYTE17 : 136|8@1+ (1,0) [0|255] "" XXX
 SG_ BYTE18 : 144|8@1+ (1,0) [0|255] "" XXX
 SG_ BYTE19 : 152|8@1+ (1,0) [0|255] "" XXX
 SG_ BYTE20 : 160|8@1+ (1,0) [0|255] "" XXX
 SG_ BYTE21 : 168|8@1+ (1,0) [0|255] "" XXX
 SG_ BYTE22 : 176|8@1+ (1,0) [0|255] "" XXX
 SG_ BYTE23 : 184|8@1+ (1,0) [0|255] "" XXX
 SG_ BYTE24 : 192|8@1+ (1,0) [0|255] "" XXX
 SG_ BYTE25 : 200|8@1+ (1,0) [0|255] "" XXX
 SG_ BYTE26 : 208|8@1+ (1,0) [0|255] "" XXX
 SG_ BYTE27 : 216|8@1+ (1,0) [0|255] "" XXX
 SG_ BYTE28 : 224|8@1+ (1,0) [0|255] "" XXX
 SG_ BYTE29 : 232|8@1+ (1,0) [0|255] "" XXX
 SG_ BYTE30 : 240|8@1+ (1,0) [0|255] "" XXX
 SG_ BYTE31 : 248|8@1+ (1,0) [0|255] "" XXX

BO_ 560 HBA_0x230: 16 XXX
 SG_ BYTE0 : 0|8@1+ (1,0) [0|255] "" XXX
 SG_ BYTE1 : 8|8@1+ (1,0) [0|255] "" XXX
 SG_ BYTE2 : 16|8@1+ (1,0) [0|255] "" XXX
 SG_ BYTE3 : 24|8@1+ (1,0) [0|255] "" XXX
 SG_ BYTE4 : 32|8@1+ (1,0) [0|255] "" XXX
 SG_ BYTE5 : 40|8@1+ (1,0) [0|255] "" XXX
 SG_ BYTE6 : 48|8@1+ (1,0) [0|255] "" XXX
 SG_ BYTE7 : 56|8@1+ (1,0) [0|255] "" XXX
 SG_ BYTE8 : 64|8@1+ (1,0) [0|255] "" XXX
 SG_ BYTE9 : 72|8@1+ (1,0) [0|255] "" XXX
 SG_ BYTE10 : 80|8@1+ (1,0) [0|255] "" XXX
 SG_ BYTE11 : 88|8@1+ (1,0) [0|255] "" XXX
 SG_ BYTE12 : 96|8@1+ (1,0) [0|255] "" XXX
 SG_ BYTE13 : 104|8@1+ (1,0) [0|255] "" XXX
 SG_ BYTE14 : 112|8@1+ (1,0) [0|255] "" XXX
 SG_ BYTE15 : 120|8@1+ (1,0) [0|255] "" XXX

BO_ 561 HBA_0x231: 32 XXX
 SG_ BYTE0 : 0|8@1+ (1,0) [0|255] "" XXX
 SG_ BYTE1 : 8|8@1+ (1,0) [0|255] "" XXX
 SG_ BYTE2 : 16|8@1+ (1,0) [0|255] "" XXX
 SG_ BYTE3 : 24|8@1+ (1,0) [0|255] "" XXX
 SG_ BYTE4 : 32|8@1+ (1,0) [0|255] "" XXX
 SG_ BYTE5 : 40|8@1+ (1,0) [0|255] "" XXX
 SG_ BYTE6 : 48|8@1+ (1,0) [0|255] "" XXX
 SG_ BYTE7 : 56|8@1+ (1,0) [0|255] "" XXX
 SG_ BYTE8 : 64|8@1+ (1,0) [0|255] "" XXX
 SG_ BYTE9 : 72|8@1+ (1,0) [0|255] "" XXX
 SG_ BYTE10 : 80|8@1+ (1,0) [0|255] "" XXX
 SG_ BYTE11 : 88|8@1+ (1,0) [0|255] "" XXX
 SG_ BYTE12 : 96|8@1+ (1,0) [0|255] "" XXX
 SG_ BYTE13 : 104|8@1+ (1,0) [0|255] "" XXX
 SG_ BYTE14 : 112|8@1+ (1,0) [0|255] "" XXX
 SG_ BYTE15 : 120|8@1+ (1,0) [0|255] "" XXX
 SG_ BYTE16 : 128|8@1+ (1,0) [0|255] "" XXX
 SG_ BYTE17 : 136|8@1+ (1,0) [0|255] "" XXX
 SG_ BYTE18 : 144|8@1+ (1,0) [0|255] "" XXX
 SG_ BYTE19 : 152|8@1+ (1,0) [0|255] "" XXX
 SG_ BYTE20 : 160|8@1+ (1,0) [0|255] "" XXX
 SG_ BYTE21 : 168|8@1+ (1,0) [0|255] "" XXX
 SG_ BYTE22 : 176|8@1+ (1,0) [0|255] "" XXX
 SG_ BYTE23 : 184|8@1+ (1,0) [0|255] "" XXX
 SG_ BYTE24 : 192|8@1+ (1,0) [0|255] "" XXX
 SG_ BYTE25 : 200|8@1+ (1,0) [0|255] "" XXX
 SG_ BYTE26 : 208|8@1+ (1,0) [0|255] "" XXX
 SG_ BYTE27 : 216|8@1+ (1,0) [0|255] "" XXX
 SG_ BYTE28 : 224|8@1+ (1,0) [0|255] "" XXX
 SG_ BYTE29 : 232|8@1+ (1,0) [0|255] "" XXX
 SG_ BYTE30 : 240|8@1+ (1,0) [0|255] "" XXX
 SG_ BYTE31 : 248|8@1+ (1,0) [0|255] "" XXX

BO_ 562 HBA_0x232: 32 XXX
 SG_ BYTE0 : 0|8@1+ (1,0) [0|255] "" XXX
 SG_ BYTE1 : 8|8@1+ (1,0) [0|255] "" XXX
 SG_ BYTE2 : 16|8@1+ (1,0) [0|255] "" XXX
 SG_ BYTE3 : 24|8@1+ (1,0) [0|255] "" XXX
 SG_ BYTE4 : 32|8@1+ (1,0) [0|255] "" XXX
 SG_ BYTE5 : 40|8@1+ (1,0) [0|255] "" XXX
 SG_ BYTE6 : 48|8@1+ (1,0) [0|255] "" XXX
 SG_ BYTE7 : 56|8@1+ (1,0) [0|255] "" XXX
 SG_ BYTE8 : 64|8@1+ (1,0) [0|255] "" XXX
 SG_ BYTE9 : 72|8@1+ (1,0) [0|255] "" XXX
 SG_ BYTE10 : 80|8@1+ (1,0) [0|255] "" XXX
 SG_ BYTE11 : 88|8@1+ (1,0) [0|255] "" XXX
 SG_ BYTE12 : 96|8@1+ (1,0) [0|255] "" XXX
 SG_ BYTE13 : 104|8@1+ (1,0) [0|255] "" XXX
 SG_ BYTE14 : 112|8@1+ (1,0) [0|255] "" XXX
 SG_ BYTE15 : 120|8@1+ (1,0) [0|255] "" XXX
 SG_ BYTE16 : 128|8@1+ (1,0) [0|255] "" XXX
 SG_ BYTE17 : 136|8@1+ (1,0) [0|255] "" XXX
 SG_ BYTE18 : 144|8@1+ (1,0) [0|255] "" XXX
 SG_ BYTE19 : 152|8@1+ (1,0) [0|255] "" XXX
 SG_ BYTE20 : 160|8@1+ (1,0) [0|255] "" XXX
 SG_ BYTE21 : 168|8@1+ (1,0) [0|255] "" XXX
 SG_ BYTE22 : 176|8@1+ (1,0) [0|255] "" XXX
 SG_ BYTE23 : 184|8@1+ (1,0) [0|255] "" XXX
 SG_ BYTE24 : 192|8@1+ (1,0) [0|255] "" XXX
 SG_ BYTE25 : 200|8@1+ (1,0) [0|255] "" XXX
 SG_ BYTE26 : 208|8@1+ (1,0) [0|255] "" XXX
 SG_ BYTE27 : 216|8@1+ (1,0) [0|255] "" XXX
 SG_ BYTE28 : 224|8@1+ (1,0) [0|255] "" XXX
 SG_ BYTE29 : 232|8@1+ (1,0) [0|255] "" XXX
 SG_ BYTE30 : 240|8@1+ (1,0) [0|255] "" XXX
 SG_ BYTE31 : 248|8@1+ (1,0) [0|255] "" XXX

BO_ 563 HBA_0x233: 32 XXX
 SG_ BYTE0 : 0|8@1+ (1,0) [0|255] "" XXX
 SG_ BYTE1 : 8|8@1+ (1,0) [0|255] "" XXX
 SG_ BYTE2 : 16|8@1+ (1,0) [0|255] "" XXX
 SG_ BYTE3 : 24|8@1+ (1,0) [0|255] "" XXX
 SG_ BYTE4 : 32|8@1+ (1,0) [0|255] "" XXX
 SG_ BYTE5 : 40|8@1+ (1,0) [0|255] "" XXX
 SG_ BYTE6 : 48|8@1+ (1,0) [0|255] "" XXX
 SG_ BYTE7 : 56|8@1+ (1,0) [0|255] "" XXX
 SG_ BYTE8 : 64|8@1+ (1,0) [0|255] "" XXX
 SG_ BYTE9 : 72|8@1+ (1,0) [0|255] "" XXX
 SG_ BYTE10 : 80|8@1+ (1,0) [0|255] "" XXX
 SG_ BYTE11 : 88|8@1+ (1,0) [0|255] "" XXX
 SG_ BYTE12 : 96|8@1+ (1,0) [0|255] "" XXX
 SG_ BYTE13 : 104|8@1+ (1,0) [0|255] "" XXX
 SG_ BYTE14 : 112|8@1+ (1,0) [0|255] "" XXX
 SG_ BYTE15 : 120|8@1+ (1,0) [0|255] "" XXX
 SG_ BYTE16 : 128|8@1+ (1,0) [0|255] "" XXX
 SG_ BYTE17 : 136|8@1+ (1,0) [0|255] "" XXX
 SG_ BYTE18 : 144|8@1+ (1,0) [0|255] "" XXX
 SG_ BYTE19 : 152|8@1+ (1,0) [0|255] "" XXX
 SG_ BYTE20 : 160|8@1+ (1,0) [0|255] "" XXX
 SG_ BYTE21 : 168|8@1+ (1,0) [0|255] "" XXX
 SG_ BYTE22 : 176|8@1+ (1,0) [0|255] "" XXX
 SG_ BYTE23 : 184|8@1+ (1,0) [0|255] "" XXX
 SG_ BYTE24 : 192|8@1+ (1,0) [0|255] "" XXX
 SG_ BYTE25 : 200|8@1+ (1,0) [0|255] "" XXX
 SG_ BYTE26 : 208|8@1+ (1,0) [0|255] "" XXX
 SG_ BYTE27 : 216|8@1+ (1,0) [0|255] "" XXX
 SG_ BYTE28 : 224|8@1+ (1,0) [0|255] "" XXX
 SG_ BYTE29 : 232|8@1+ (1,0) [0|255] "" XXX
 SG_ BYTE30 : 240|8@1+ (1,0) [0|255] "" XXX
 SG_ BYTE31 : 248|8@1+ (1,0) [0|255] "" XXX

BO_ 564 HBA_0x234: 32 XXX
 SG_ BYTE0 : 0|8@1+ (1,0) [0|255] "" XXX
 SG_ BYTE1 : 8|8@1+ (1,0) [0|255] "" XXX
 SG_ BYTE2 : 16|8@1+ (1,0) [0|255] "" XXX
 SG_ BYTE3 : 24|8@1+ (1,0) [0|255] "" XXX
 SG_ BYTE4 : 32|8@1+ (1,0) [0|255] "" XXX
 SG_ BYTE5 : 40|8@1+ (1,0) [0|255] "" XXX
 SG_ BYTE6 : 48|8@1+ (1,0) [0|255] "" XXX
 SG_ BYTE7 : 56|8@1+ (1,0) [0|255] "" XXX
 SG_ BYTE8 : 64|8@1+ (1,0) [0|255] "" XXX
 SG_ BYTE9 : 72|8@1+ (1,0) [0|255] "" XXX
 SG_ BYTE10 : 80|8@1+ (1,0) [0|255] "" XXX
 SG_ BYTE11 : 88|8@1+ (1,0) [0|255] "" XXX
 SG_ BYTE12 : 96|8@1+ (1,0) [0|255] "" XXX
 SG_ BYTE13 : 104|8@1+ (1,0) [0|255] "" XXX
 SG_ BYTE14 : 112|8@1+ (1,0) [0|255] "" XXX
 SG_ BYTE15 : 120|8@1+ (1,0) [0|255] "" XXX
 SG_ BYTE16 : 128|8@1+ (1,0) [0|255] "" XXX
 SG_ BYTE17 : 136|8@1+ (1,0) [0|255] "" XXX
 SG_ BYTE18 : 144|8@1+ (1,0) [0|255] "" XXX
 SG_ BYTE19 : 152|8@1+ (1,0) [0|255] "" XXX
 SG_ BYTE20 : 160|8@1+ (1,0) [0|255] "" XXX
 SG_ BYTE21 : 168|8@1+ (1,0) [0|255] "" XXX
 SG_ BYTE22 : 176|8@1+ (1,0) [0|255] "" XXX
 SG_ BYTE23 : 184|8@1+ (1,0) [0|255] "" XXX
 SG_ BYTE24 : 192|8@1+ (1,0) [0|255] "" XXX
 SG_ BYTE25 : 200|8@1+ (1,0) [0|255] "" XXX
 SG_ BYTE26 : 208|8@1+ (1,0) [0|255] "" XXX
 SG_ BYTE27 : 216|8@1+ (1,0) [0|255] "" XXX
 SG_ BYTE28 : 224|8@1+ (1,0) [0|255] "" XXX
 SG_ BYTE29 : 232|8@1+ (1,0) [0|255] "" XXX
 SG_ BYTE30 : 240|8@1+ (1,0) [0|255] "" XXX
 SG_ BYTE31 : 248|8@1+ (1,0) [0|255] "" XXX

BO_ 565 HBA_0x235: 32 XXX
 SG_ BYTE0 : 0|8@1+ (1,0) [0|255] "" XXX
 SG_ BYTE1 : 8|8@1+ (1,0) [0|255] "" XXX
 SG_ BYTE2 : 16|8@1+ (1,0) [0|255] "" XXX
 SG_ BYTE3 : 24|8@1+ (1,0) [0|255] "" XXX
 SG_ BYTE4 : 32|8@1+ (1,0) [0|255] "" XXX
 SG_ BYTE5 : 40|8@1+ (1,0) [0|255] "" XXX
 SG_ BYTE6 : 48|8@1+ (1,0) [0|255] "" XXX
 SG_ BYTE7 : 56|8@1+ (1,0) [0|255] "" XXX
 SG_ BYTE8 : 64|8@1+ (1,0) [0|255] "" XXX
 SG_ BYTE9 : 72|8@1+ (1,0) [0|255] "" XXX
 SG_ BYTE10 : 80|8@1+ (1,0) [0|255] "" XXX
 SG_ BYTE11 : 88|8@1+ (1,0) [0|255] "" XXX
 SG_ BYTE12 : 96|8@1+ (1,0) [0|255] "" XXX
 SG_ BYTE13 : 104|8@1+ (1,0) [0|255] "" XXX
 SG_ BYTE14 : 112|8@1+ (1,0) [0|255] "" XXX
 SG_ BYTE15 : 120|8@1+ (1,0) [0|255] "" XXX
 SG_ BYTE16 : 128|8@1+ (1,0) [0|255] "" XXX
 SG_ BYTE17 : 136|8@1+ (1,0) [0|255] "" XXX
 SG_ BYTE18 : 144|8@1+ (1,0) [0|255] "" XXX
 SG_ BYTE19 : 152|8@1+ (1,0) [0|255] "" XXX
 SG_ BYTE20 : 160|8@1+ (1,0) [0|255] "" XXX
 SG_ BYTE21 : 168|8@1+ (1,0) [0|255] "" XXX
 SG_ BYTE22 : 176|8@1+ (1,0) [0|255] "" XXX
 SG_ BYTE23 : 184|8@1+ (1,0) [0|255] "" XXX
 SG_ BYTE24 : 192|8@1+ (1,0) [0|255] "" XXX
 SG_ BYTE25 : 200|8@1+ (1,0) [0|255] "" XXX
 SG_ BYTE26 : 208|8@1+ (1,0) [0|255] "" XXX
 SG_ BYTE27 : 216|8@1+ (1,0) [0|255] "" XXX
 SG_ BYTE28 : 224|8@1+ (1,0) [0|255] "" XXX
 SG_ BYTE29 : 232|8@1+ (1,0) [0|255] "" XXX
 SG_ BYTE30 : 240|8@1+ (1,0) [0|255] "" XXX
 SG_ BYTE31 : 248|8@1+ (1,0) [0|255] "" XXX

BO_ 566 HBA_0x236: 32 XXX
 SG_ BYTE0 : 0|8@1+ (1,0) [0|255] "" XXX
 SG_ BYTE1 : 8|8@1+ (1,0) [0|255] "" XXX
 SG_ BYTE2 : 16|8@1+ (1,0) [0|255] "" XXX
 SG_ BYTE3 : 24|8@1+ (1,0) [0|255] "" XXX
 SG_ BYTE4 : 32|8@1+ (1,0) [0|255] "" XXX
 SG_ BYTE5 : 40|8@1+ (1,0) [0|255] "" XXX
 SG_ BYTE6 : 48|8@1+ (1,0) [0|255] "" XXX
 SG_ BYTE7 : 56|8@1+ (1,0) [0|255] "" XXX
 SG_ BYTE8 : 64|8@1+ (1,0) [0|255] "" XXX
 SG_ BYTE9 : 72|8@1+ (1,0) [0|255] "" XXX
 SG_ BYTE10 : 80|8@1+ (1,0) [0|255] "" XXX
 SG_ BYTE11 : 88|8@1+ (1,0) [0|255] "" XXX
 SG_ BYTE12 : 96|8@1+ (1,0) [0|255] "" XXX
 SG_ BYTE13 : 104|8@1+ (1,0) [0|255] "" XXX
 SG_ BYTE14 : 112|8@1+ (1,0) [0|255] "" XXX
 SG_ BYTE15 : 120|8@1+ (1,0) [0|255] "" XXX
 SG_ BYTE16 : 128|8@1+ (1,0) [0|255] "" XXX
 SG_ BYTE17 : 136|8@1+ (1,0) [0|255] "" XXX
 SG_ BYTE18 : 144|8@1+ (1,0) [0|255] "" XXX
 SG_ BYTE19 : 152|8@1+ (1,0) [0|255] "" XXX
 SG_ BYTE20 : 160|8@1+ (1,0) [0|255] "" XXX
 SG_ BYTE21 : 168|8@1+ (1,0) [0|255] "" XXX
 SG_ BYTE22 : 176|8@1+ (1,0) [0|255] "" XXX
 SG_ BYTE23 : 184|8@1+ (1,0) [0|255] "" XXX
 SG_ BYTE24 : 192|8@1+ (1,0) [0|255] "" XXX
 SG_ BYTE25 : 200|8@1+ (1,0) [0|255] "" XXX
 SG_ BYTE26 : 208|8@1+ (1,0) [0|255] "" XXX
 SG_ BYTE27 : 216|8@1+ (1,0) [0|255] "" XXX
 SG_ BYTE28 : 224|8@1+ (1,0) [0|255] "" XXX
 SG_ BYTE29 : 232|8@1+ (1,0) [0|255] "" XXX
 SG_ BYTE30 : 240|8@1+ (1,0) [0|255] "" XXX
 SG_ BYTE31 : 248|8@1+ (1,0) [0|255] "" XXX

BO_ 567 HBA_0x237: 32 XXX
 SG_ BYTE0 : 0|8@1+ (1,0) [0|255] "" XXX
 SG_ BYTE1 : 8|8@1+ (1,0) [0|255] "" XXX
 SG_ BYTE2 : 16|8@1+ (1,0) [0|255] "" XXX
 SG_ BYTE3 : 24|8@1+ (1,0) [0|255] "" XXX
 SG_ BYTE4 : 32|8@1+ (1,0) [0|255] "" XXX
 SG_ BYTE5 : 40|8@1+ (1,0) [0|255] "" XXX
 SG_ BYTE6 : 48|8@1+ (1,0) [0|255] "" XXX
 SG_ BYTE7 : 56|8@1+ (1,0) [0|255] "" XXX
 SG_ BYTE8 : 64|8@1+ (1,0) [0|255] "" XXX
 SG_ BYTE9 : 72|8@1+ (1,0) [0|255] "" XXX
 SG_ BYTE10 : 80|8@1+ (1,0) [0|255] "" XXX
 SG_ BYTE11 : 88|8@1+ (1,0) [0|255] "" XXX
 SG_ BYTE12 : 96|8@1+ (1,0) [0|255] "" XXX
 SG_ BYTE13 : 104|8@1+ (1,0) [0|255] "" XXX
 SG_ BYTE14 : 112|8@1+ (1,0) [0|255] "" XXX
 SG_ BYTE15 : 120|8@1+ (1,0) [0|255] "" XXX
 SG_ BYTE16 : 128|8@1+ (1,0) [0|255] "" XXX
 SG_ BYTE17 : 136|8@1+ (1,0) [0|255] "" XXX
 SG_ BYTE18 : 144|8@1+ (1,0) [0|255] "" XXX
 SG_ BYTE19 : 152|8@1+ (1,0) [0|255] "" XXX
 SG_ BYTE20 : 160|8@1+ (1,0) [0|255] "" XXX
 SG_ BYTE21 : 168|8@1+ (1,0) [0|255] "" XXX
 SG_ BYTE22 : 176|8@1+ (1,0) [0|255] "" XXX
 SG_ BYTE23 : 184|8@1+ (1,0) [0|255] "" XXX
 SG_ BYTE24 : 192|8@1+ (1,0) [0|255] "" XXX
 SG_ BYTE25 : 200|8@1+ (1,0) [0|255] "" XXX
 SG_ BYTE26 : 208|8@1+ (1,0) [0|255] "" XXX
 SG_ BYTE27 : 216|8@1+ (1,0) [0|255] "" XXX
 SG_ BYTE28 : 224|8@1+ (1,0) [0|255] "" XXX
 SG_ BYTE29 : 232|8@1+ (1,0) [0|255] "" XXX
 SG_ BYTE30 : 240|8@1+ (1,0) [0|255] "" XXX
 SG_ BYTE31 : 248|8@1+ (1,0) [0|255] "" XXX

BO_ 568 HBA_0x238: 32 XXX
 SG_ BYTE0 : 0|8@1+ (1,0) [0|255] "" XXX
 SG_ BYTE1 : 8|8@1+ (1,0) [0|255] "" XXX
 SG_ BYTE2 : 16|8@1+ (1,0) [0|255] "" XXX
 SG_ BYTE3 : 24|8@1+ (1,0) [0|255] "" XXX
 SG_ BYTE4 : 32|8@1+ (1,0) [0|255] "" XXX
 SG_ BYTE5 : 40|8@1+ (1,0) [0|255] "" XXX
 SG_ BYTE6 : 48|8@1+ (1,0) [0|255] "" XXX
 SG_ BYTE7 : 56|8@1+ (1,0) [0|255] "" XXX
 SG_ BYTE8 : 64|8@1+ (1,0) [0|255] "" XXX
 SG_ BYTE9 : 72|8@1+ (1,0) [0|255] "" XXX
 SG_ BYTE10 : 80|8@1+ (1,0) [0|255] "" XXX
 SG_ BYTE11 : 88|8@1+ (1,0) [0|255] "" XXX
 SG_ BYTE12 : 96|8@1+ (1,0) [0|255] "" XXX
 SG_ BYTE13 : 104|8@1+ (1,0) [0|255] "" XXX
 SG_ BYTE14 : 112|8@1+ (1,0) [0|255] "" XXX
 SG_ BYTE15 : 120|8@1+ (1,0) [0|255] "" XXX
 SG_ BYTE16 : 128|8@1+ (1,0) [0|255] "" XXX
 SG_ BYTE17 : 136|8@1+ (1,0) [0|255] "" XXX
 SG_ BYTE18 : 144|8@1+ (1,0) [0|255] "" XXX
 SG_ BYTE19 : 152|8@1+ (1,0) [0|255] "" XXX
 SG_ BYTE20 : 160|8@1+ (1,0) [0|255] "" XXX
 SG_ BYTE21 : 168|8@1+ (1,0) [0|255] "" XXX
 SG_ BYTE22 : 176|8@1+ (1,0) [0|255] "" XXX
 SG_ BYTE23 : 184|8@1+ (1,0) [0|255] "" XXX
 SG_ BYTE24 : 192|8@1+ (1,0) [0|255] "" XXX
 SG_ BYTE25 : 200|8@1+ (1,0) [0|255] "" XXX
 SG_ BYTE26 : 208|8@1+ (1,0) [0|255] "" XXX
 SG_ BYTE27 : 216|8@1+ (1,0) [0|255] "" XXX
 SG_ BYTE28 : 224|8@1+ (1,0) [0|255] "" XXX
 SG_ BYTE29 : 232|8@1+ (1,0) [0|255] "" XXX
 SG_ BYTE30 : 240|8@1+ (1,0) [0|255] "" XXX
 SG_ BYTE31 : 248|8@1+ (1,0) [0|255] "" XXX

BO_ 569 HBA_0x239: 32 XXX
 SG_ BYTE0 : 0|8@1+ (1,0) [0|255] "" XXX
 SG_ BYTE1 : 8|8@1+ (1,0) [0|255] "" XXX
 SG_ BYTE2 : 16|8@1+ (1,0) [0|255] "" XXX
 SG_ BYTE3 : 24|8@1+ (1,0) [0|255] "" XXX
 SG_ BYTE4 : 32|8@1+ (1,0) [0|255] "" XXX
 SG_ BYTE5 : 40|8@1+ (1,0) [0|255] "" XXX
 SG_ BYTE6 : 48|8@1+ (1,0) [0|255] "" XXX
 SG_ BYTE7 : 56|8@1+ (1,0) [0|255] "" XXX
 SG_ BYTE8 : 64|8@1+ (1,0) [0|255] "" XXX
 SG_ BYTE9 : 72|8@1+ (1,0) [0|255] "" XXX
 SG_ BYTE10 : 80|8@1+ (1,0) [0|255] "" XXX
 SG_ BYTE11 : 88|8@1+ (1,0) [0|255] "" XXX
 SG_ BYTE12 : 96|8@1+ (1,0) [0|255] "" XXX
 SG_ BYTE13 : 104|8@1+ (1,0) [0|255] "" XXX
 SG_ BYTE14 : 112|8@1+ (1,0) [0|255] "" XXX
 SG_ BYTE15 : 120|8@1+ (1,0) [0|255] "" XXX
 SG_ BYTE16 : 128|8@1+ (1,0) [0|255] "" XXX
 SG_ BYTE17 : 136|8@1+ (1,0) [0|255] "" XXX
 SG_ BYTE18 : 144|8@1+ (1,0) [0|255] "" XXX
 SG_ BYTE19 : 152|8@1+ (1,0) [0|255] "" XXX
 SG_ BYTE20 : 160|8@1+ (1,0) [0|255] "" XXX
 SG_ BYTE21 : 168|8@1+ (1,0) [0|255] "" XXX
 SG_ BYTE22 : 176|8@1+ (1,0) [0|255] "" XXX
 SG_ BYTE23 : 184|8@1+ (1,0) [0|255] "" XXX
 SG_ BYTE24 : 192|8@1+ (1,0) [0|255] "" XXX
 SG_ BYTE25 : 200|8@1+ (1,0) [0|255] "" XXX
 SG_ BYTE26 : 208|8@1+ (1,0) [0|255] "" XXX
 SG_ BYTE27 : 216|8@1+ (1,0) [0|255] "" XXX
 SG_ BYTE28 : 224|8@1+ (1,0) [0|255] "" XXX
 SG_ BYTE29 : 232|8@1+ (1,0) [0|255] "" XXX
 SG_ BYTE30 : 240|8@1+ (1,0) [0|255] "" XXX
 SG_ BYTE31 : 248|8@1+ (1,0) [0|255] "" XXX

BO_ 570 HBA_0x23a: 32 XXX
 SG_ BYTE0 : 0|8@1+ (1,0) [0|255] "" XXX
 SG_ BYTE1 : 8|8@1+ (1,0) [0|255] "" XXX
 SG_ BYTE2 : 16|8@1+ (1,0) [0|255] "" XXX
 SG_ BYTE3 : 24|8@1+ (1,0) [0|255] "" XXX
 SG_ BYTE4 : 32|8@1+ (1,0) [0|255] "" XXX
 SG_ BYTE5 : 40|8@1+ (1,0) [0|255] "" XXX
 SG_ BYTE6 : 48|8@1+ (1,0) [0|255] "" XXX
 SG_ BYTE7 : 56|8@1+ (1,0) [0|255] "" XXX
 SG_ BYTE8 : 64|8@1+ (1,0) [0|255] "" XXX
 SG_ BYTE9 : 72|8@1+ (1,0) [0|255] "" XXX
 SG_ BYTE10 : 80|8@1+ (1,0) [0|255] "" XXX
 SG_ BYTE11 : 88|8@1+ (1,0) [0|255] "" XXX
 SG_ BYTE12 : 96|8@1+ (1,0) [0|255] "" XXX
 SG_ BYTE13 : 104|8@1+ (1,0) [0|255] "" XXX
 SG_ BYTE14 : 112|8@1+ (1,0) [0|255] "" XXX
 SG_ BYTE15 : 120|8@1+ (1,0) [0|255] "" XXX
 SG_ BYTE16 : 128|8@1+ (1,0) [0|255] "" XXX
 SG_ BYTE17 : 136|8@1+ (1,0) [0|255] "" XXX
 SG_ BYTE18 : 144|8@1+ (1,0) [0|255] "" XXX
 SG_ BYTE19 : 152|8@1+ (1,0) [0|255] "" XXX
 SG_ BYTE20 : 160|8@1+ (1,0) [0|255] "" XXX
 SG_ BYTE21 : 168|8@1+ (1,0) [0|255] "" XXX
 SG_ BYTE22 : 176|8@1+ (1,0) [0|255] "" XXX
 SG_ BYTE23 : 184|8@1+ (1,0) [0|255] "" XXX
 SG_ BYTE24 : 192|8@1+ (1,0) [0|255] "" XXX
 SG_ BYTE25 : 200|8@1+ (1,0) [0|255] "" XXX
 SG_ BYTE26 : 208|8@1+ (1,0) [0|255] "" XXX
 SG_ BYTE27 : 216|8@1+ (1,0) [0|255] "" XXX
 SG_ BYTE28 : 224|8@1+ (1,0) [0|255] "" XXX
 SG_ BYTE29 : 232|8@1+ (1,0) [0|255] "" XXX
 SG_ BYTE30 : 240|8@1+ (1,0) [0|255] "" XXX
 SG_ BYTE31 : 248|8@1+ (1,0) [0|255] "" XXX

BO_ 571 HBA_0x23b: 32 XXX
 SG_ BYTE0 : 0|8@1+ (1,0) [0|255] "" XXX
 SG_ BYTE1 : 8|8@1+ (1,0) [0|255] "" XXX
 SG_ BYTE2 : 16|8@1+ (1,0) [0|255] "" XXX
 SG_ BYTE3 : 24|8@1+ (1,0) [0|255] "" XXX
 SG_ BYTE4 : 32|8@1+ (1,0) [0|255] "" XXX
 SG_ BYTE5 : 40|8@1+ (1,0) [0|255] "" XXX
 SG_ BYTE6 : 48|8@1+ (1,0) [0|255] "" XXX
 SG_ BYTE7 : 56|8@1+ (1,0) [0|255] "" XXX
 SG_ BYTE8 : 64|8@1+ (1,0) [0|255] "" XXX
 SG_ BYTE9 : 72|8@1+ (1,0) [0|255] "" XXX
 SG_ BYTE10 : 80|8@1+ (1,0) [0|255] "" XXX
 SG_ BYTE11 : 88|8@1+ (1,0) [0|255] "" XXX
 SG_ BYTE12 : 96|8@1+ (1,0) [0|255] "" XXX
 SG_ BYTE13 : 104|8@1+ (1,0) [0|255] "" XXX
 SG_ BYTE14 : 112|8@1+ (1,0) [0|255] "" XXX
 SG_ BYTE15 : 120|8@1+ (1,0) [0|255] "" XXX
 SG_ BYTE16 : 128|8@1+ (1,0) [0|255] "" XXX
 SG_ BYTE17 : 136|8@1+ (1,0) [0|255] "" XXX
 SG_ BYTE18 : 144|8@1+ (1,0) [0|255] "" XXX
 SG_ BYTE19 : 152|8@1+ (1,0) [0|255] "" XXX
 SG_ BYTE20 : 160|8@1+ (1,0) [0|255] "" XXX
 SG_ BYTE21 : 168|8@1+ (1,0) [0|255] "" XXX
 SG_ BYTE22 : 176|8@1+ (1,0) [0|255] "" XXX
 SG_ BYTE23 : 184|8@1+ (1,0) [0|255] "" XXX
 SG_ BYTE24 : 192|8@1+ (1,0) [0|255] "" XXX
 SG_ BYTE25 : 200|8@1+ (1,0) [0|255] "" XXX
 SG_ BYTE26 : 208|8@1+ (1,0) [0|255] "" XXX
 SG_ BYTE27 : 216|8@1+ (1,0) [0|255] "" XXX
 SG_ BYTE28 : 224|8@1+ (1,0) [0|255] "" XXX
 SG_ BYTE29 : 232|8@1+ (1,0) [0|255] "" XXX
 SG_ BYTE30 : 240|8@1+ (1,0) [0|255] "" XXX
 SG_ BYTE31 : 248|8@1+ (1,0) [0|255] "" XXX

BO_ 572 HBA_0x23c: 32 XXX
 SG_ BYTE0 : 0|8@1+ (1,0) [0|255] "" XXX
 SG_ BYTE1 : 8|8@1+ (1,0) [0|255] "" XXX
 SG_ BYTE2 : 16|8@1+ (1,0) [0|255] "" XXX
 SG_ BYTE3 : 24|8@1+ (1,0) [0|255] "" XXX
 SG_ BYTE4 : 32|8@1+ (1,0) [0|255] "" XXX
 SG_ BYTE5 : 40|8@1+ (1,0) [0|255] "" XXX
 SG_ BYTE6 : 48|8@1+ (1,0) [0|255] "" XXX
 SG_ BYTE7 : 56|8@1+ (1,0) [0|255] "" XXX
 SG_ BYTE8 : 64|8@1+ (1,0) [0|255] "" XXX
 SG_ BYTE9 : 72|8@1+ (1,0) [0|255] "" XXX
 SG_ BYTE10 : 80|8@1+ (1,0) [0|255] "" XXX
 SG_ BYTE11 : 88|8@1+ (1,0) [0|255] "" XXX
 SG_ BYTE12 : 96|8@1+ (1,0) [0|255] "" XXX
 SG_ BYTE13 : 104|8@1+ (1,0) [0|255] "" XXX
 SG_ BYTE14 : 112|8@1+ (1,0) [0|255] "" XXX
 SG_ BYTE15 : 120|8@1+ (1,0) [0|255] "" XXX
 SG_ BYTE16 : 128|8@1+ (1,0) [0|255] "" XXX
 SG_ BYTE17 : 136|8@1+ (1,0) [0|255] "" XXX
 SG_ BYTE18 : 144|8@1+ (1,0) [0|255] "" XXX
 SG_ BYTE19 : 152|8@1+ (1,0) [0|255] "" XXX
 SG_ BYTE20 : 160|8@1+ (1,0) [0|255] "" XXX
 SG_ BYTE21 : 168|8@1+ (1,0) [0|255] "" XXX
 SG_ BYTE22 : 176|8@1+ (1,0) [0|255] "" XXX
 SG_ BYTE23 : 184|8@1+ (1,0) [0|255] "" XXX
 SG_ BYTE24 : 192|8@1+ (1,0) [0|255] "" XXX
 SG_ BYTE25 : 200|8@1+ (1,0) [0|255] "" XXX
 SG_ BYTE26 : 208|8@1+ (1,0) [0|255] "" XXX
 SG_ BYTE27 : 216|8@1+ (1,0) [0|255] "" XXX
 SG_ BYTE28 : 224|8@1+ (1,0) [0|255] "" XXX
 SG_ BYTE29 : 232|8@1+ (1,0) [0|255] "" XXX
 SG_ BYTE30 : 240|8@1+ (1,0) [0|255] "" XXX
 SG_ BYTE31 : 248|8@1+ (1,0) [0|255] "" XXX

BO_ 573 HBA_0x23d: 32 XXX
 SG_ BYTE0 : 0|8@1+ (1,0) [0|255] "" XXX
 SG_ BYTE1 : 8|8@1+ (1,0) [0|255] "" XXX
 SG_ BYTE2 : 16|8@1+ (1,0) [0|255] "" XXX
 SG_ BYTE3 : 24|8@1+ (1,0) [0|255] "" XXX
 SG_ BYTE4 : 32|8@1+ (1,0) [0|255] "" XXX
 SG_ BYTE5 : 40|8@1+ (1,0) [0|255] "" XXX
 SG_ BYTE6 : 48|8@1+ (1,0) [0|255] "" XXX
 SG_ BYTE7 : 56|8@1+ (1,0) [0|255] "" XXX
 SG_ BYTE8 : 64|8@1+ (1,0) [0|255] "" XXX
 SG_ BYTE9 : 72|8@1+ (1,0) [0|255] "" XXX
 SG_ BYTE10 : 80|8@1+ (1,0) [0|255] "" XXX
 SG_ BYTE11 : 88|8@1+ (1,0) [0|255] "" XXX
 SG_ BYTE12 : 96|8@1+ (1,0) [0|255] "" XXX
 SG_ BYTE13 : 104|8@1+ (1,0) [0|255] "" XXX
 SG_ BYTE14 : 112|8@1+ (1,0) [0|255] "" XXX
 SG_ BYTE15 : 120|8@1+ (1,0) [0|255] "" XXX
 SG_ BYTE16 : 128|8@1+ (1,0) [0|255] "" XXX
 SG_ BYTE17 : 136|8@1+ (1,0) [0|255] "" XXX
 SG_ BYTE18 : 144|8@1+ (1,0) [0|255] "" XXX
 SG_ BYTE19 : 152|8@1+ (1,0) [0|255] "" XXX
 SG_ BYTE20 : 160|8@1+ (1,0) [0|255] "" XXX
 SG_ BYTE21 : 168|8@1+ (1,0) [0|255] "" XXX
 SG_ BYTE22 : 176|8@1+ (1,0) [0|255] "" XXX
 SG_ BYTE23 : 184|8@1+ (1,0) [0|255] "" XXX
 SG_ BYTE24 : 192|8@1+ (1,0) [0|255] "" XXX
 SG_ BYTE25 : 200|8@1+ (1,0) [0|255] "" XXX
 SG_ BYTE26 : 208|8@1+ (1,0) [0|255] "" XXX
 SG_ BYTE27 : 216|8@1+ (1,0) [0|255] "" XXX
 SG_ BYTE28 : 224|8@1+ (1,0) [0|255] "" XXX
 SG_ BYTE29 : 232|8@1+ (1,0) [0|255] "" XXX
 SG_ BYTE30 : 240|8@1+ (1,0) [0|255] "" XXX
 SG_ BYTE31 : 248|8@1+ (1,0) [0|255] "" XXX

BO_ 574 HBA_0x23e: 32 XXX
 SG_ BYTE0 : 0|8@1+ (1,0) [0|255] "" XXX
 SG_ BYTE1 : 8|8@1+ (1,0) [0|255] "" XXX
 SG_ BYTE2 : 16|8@1+ (1,0) [0|255] "" XXX
 SG_ BYTE3 : 24|8@1+ (1,0) [0|255] "" XXX
 SG_ BYTE4 : 32|8@1+ (1,0) [0|255] "" XXX
 SG_ BYTE5 : 40|8@1+ (1,0) [0|255] "" XXX
 SG_ BYTE6 : 48|8@1+ (1,0) [0|255] "" XXX
 SG_ BYTE7 : 56|8@1+ (1,0) [0|255] "" XXX
 SG_ BYTE8 : 64|8@1+ (1,0) [0|255] "" XXX
 SG_ BYTE9 : 72|8@1+ (1,0) [0|255] "" XXX
 SG_ BYTE10 : 80|8@1+ (1,0) [0|255] "" XXX
 SG_ BYTE11 : 88|8@1+ (1,0) [0|255] "" XXX
 SG_ BYTE12 : 96|8@1+ (1,0) [0|255] "" XXX
 SG_ BYTE13 : 104|8@1+ (1,0) [0|255] "" XXX
 SG_ BYTE14 : 112|8@1+ (1,0) [0|255] "" XXX
 SG_ BYTE15 : 120|8@1+ (1,0) [0|255] "" XXX
 SG_ BYTE16 : 128|8@1+ (1,0) [0|255] "" XXX
 SG_ BYTE17 : 136|8@1+ (1,0) [0|255] "" XXX
 SG_ BYTE18 : 144|8@1+ (1,0) [0|255] "" XXX
 SG_ BYTE19 : 152|8@1+ (1,0) [0|255] "" XXX
 SG_ BYTE20 : 160|8@1+ (1,0) [0|255] "" XXX
 SG_ BYTE21 : 168|8@1+ (1,0) [0|255] "" XXX
 SG_ BYTE22 : 176|8@1+ (1,0) [0|255] "" XXX
 SG_ BYTE23 : 184|8@1+ (1,0) [0|255] "" XXX
 SG_ BYTE24 : 192|8@1+ (1,0) [0|255] "" XXX
 SG_ BYTE25 : 200|8@1+ (1,0) [0|255] "" XXX
 SG_ BYTE26 : 208|8@1+ (1,0) [0|255] "" XXX
 SG_ BYTE27 : 216|8@1+ (1,0) [0|255] "" XXX
 SG_ BYTE28 : 224|8@1+ (1,0) [0|255] "" XXX
 SG_ BYTE29 : 232|8@1+ (1,0) [0|255] "" XXX
 SG_ BYTE30 : 240|8@1+ (1,0) [0|255] "" XXX
 SG_ BYTE31 : 248|8@1+ (1,0) [0|255] "" XXX

BO_ 575 HBA_0x23f: 32 XXX
 SG_ BYTE0 : 0|8@1+ (1,0) [0|255] "" XXX
 SG_ BYTE1 : 8|8@1+ (1,0) [0|255] "" XXX
 SG_ BYTE2 : 16|8@1+ (1,0) [0|255] "" XXX
 SG_ BYTE3 : 24|8@1+ (1,0) [0|255] "" XXX
 SG_ BYTE4 : 32|8@1+ (1,0) [0|255] "" XXX
 SG_ BYTE5 : 40|8@1+ (1,0) [0|255] "" XXX
 SG_ BYTE6 : 48|8@1+ (1,0) [0|255] "" XXX
 SG_ BYTE7 : 56|8@1+ (1,0) [0|255] "" XXX
 SG_ BYTE8 : 64|8@1+ (1,0) [0|255] "" XXX
 SG_ BYTE9 : 72|8@1+ (1,0) [0|255] "" XXX
 SG_ BYTE10 : 80|8@1+ (1,0) [0|255] "" XXX
 SG_ BYTE11 : 88|8@1+ (1,0) [0|255] "" XXX
 SG_ BYTE12 : 96|8@1+ (1,0) [0|255] "" XXX
 SG_ BYTE13 : 104|8@1+ (1,0) [0|255] "" XXX
 SG_ BYTE14 : 112|8@1+ (1,0) [0|255] "" XXX
 SG_ BYTE15 : 120|8@1+ (1,0) [0|255] "" XXX
 SG_ BYTE16 : 128|8@1+ (1,0) [0|255] "" XXX
 SG_ BYTE17 : 136|8@1+ (1,0) [0|255] "" XXX
 SG_ BYTE18 : 144|8@1+ (1,0) [0|255] "" XXX
 SG_ BYTE19 : 152|8@1+ (1,0) [0|255] "" XXX
 SG_ BYTE20 : 160|8@1+ (1,0) [0|255] "" XXX
 SG_ BYTE21 : 168|8@1+ (1,0) [0|255] "" XXX
 SG_ BYTE22 : 176|8@1+ (1,0) [0|255] "" XXX
 SG_ BYTE23 : 184|8@1+ (1,0) [0|255] "" XXX
 SG_ BYTE24 : 192|8@1+ (1,0) [0|255] "" XXX
 SG_ BYTE25 : 200|8@1+ (1,0) [0|255] "" XXX
 SG_ BYTE26 : 208|8@1+ (1,0) [0|255] "" XXX
 SG_ BYTE27 : 216|8@1+ (1,0) [0|255] "" XXX
 SG_ BYTE28 : 224|8@1+ (1,0) [0|255] "" XXX
 SG_ BYTE29 : 232|8@1+ (1,0) [0|255] "" XXX
 SG_ BYTE30 : 240|8@1+ (1,0) [0|255] "" XXX
 SG_ BYTE31 : 248|8@1+ (1,0) [0|255] "" XXX

BO_ 577 HBA_0x241: 32 XXX
 SG_ BYTE0 : 0|8@1+ (1,0) [0|255] "" XXX
 SG_ BYTE1 : 8|8@1+ (1,0) [0|255] "" XXX
 SG_ BYTE2 : 16|8@1+ (1,0) [0|255] "" XXX
 SG_ BYTE3 : 24|8@1+ (1,0) [0|255] "" XXX
 SG_ BYTE4 : 32|8@1+ (1,0) [0|255] "" XXX
 SG_ BYTE5 : 40|8@1+ (1,0) [0|255] "" XXX
 SG_ BYTE6 : 48|8@1+ (1,0) [0|255] "" XXX
 SG_ BYTE7 : 56|8@1+ (1,0) [0|255] "" XXX
 SG_ BYTE8 : 64|8@1+ (1,0) [0|255] "" XXX
 SG_ BYTE9 : 72|8@1+ (1,0) [0|255] "" XXX
 SG_ BYTE10 : 80|8@1+ (1,0) [0|255] "" XXX
 SG_ BYTE11 : 88|8@1+ (1,0) [0|255] "" XXX
 SG_ BYTE12 : 96|8@1+ (1,0) [0|255] "" XXX
 SG_ BYTE13 : 104|8@1+ (1,0) [0|255] "" XXX
 SG_ BYTE14 : 112|8@1+ (1,0) [0|255] "" XXX
 SG_ BYTE15 : 120|8@1+ (1,0) [0|255] "" XXX
 SG_ BYTE16 : 128|8@1+ (1,0) [0|255] "" XXX
 SG_ BYTE17 : 136|8@1+ (1,0) [0|255] "" XXX
 SG_ BYTE18 : 144|8@1+ (1,0) [0|255] "" XXX
 SG_ BYTE19 : 152|8@1+ (1,0) [0|255] "" XXX
 SG_ BYTE20 : 160|8@1+ (1,0) [0|255] "" XXX
 SG_ BYTE21 : 168|8@1+ (1,0) [0|255] "" XXX
 SG_ BYTE22 : 176|8@1+ (1,0) [0|255] "" XXX
 SG_ BYTE23 : 184|8@1+ (1,0) [0|255] "" XXX
 SG_ BYTE24 : 192|8@1+ (1,0) [0|255] "" XXX
 SG_ BYTE25 : 200|8@1+ (1,0) [0|255] "" XXX
 SG_ BYTE26 : 208|8@1+ (1,0) [0|255] "" XXX
 SG_ BYTE27 : 216|8@1+ (1,0) [0|255] "" XXX
 SG_ BYTE28 : 224|8@1+ (1,0) [0|255] "" XXX
 SG_ BYTE29 : 232|8@1+ (1,0) [0|255] "" XXX
 SG_ BYTE30 : 240|8@1+ (1,0) [0|255] "" XXX
 SG_ BYTE31 : 248|8@1+ (1,0) [0|255] "" XXX

BO_ 578 HBA_0x242: 32 XXX
 SG_ BYTE0 : 0|8@1+ (1,0) [0|255] "" XXX
 SG_ BYTE1 : 8|8@1+ (1,0) [0|255] "" XXX
 SG_ BYTE2 : 16|8@1+ (1,0) [0|255] "" XXX
 SG_ BYTE3 : 24|8@1+ (1,0) [0|255] "" XXX
 SG_ BYTE4 : 32|8@1+ (1,0) [0|255] "" XXX
 SG_ BYTE5 : 40|8@1+ (1,0) [0|255] "" XXX
 SG_ BYTE6 : 48|8@1+ (1,0) [0|255] "" XXX
 SG_ BYTE7 : 56|8@1+ (1,0) [0|255] "" XXX
 SG_ BYTE8 : 64|8@1+ (1,0) [0|255] "" XXX
 SG_ BYTE9 : 72|8@1+ (1,0) [0|255] "" XXX
 SG_ BYTE10 : 80|8@1+ (1,0) [0|255] "" XXX
 SG_ BYTE11 : 88|8@1+ (1,0) [0|255] "" XXX
 SG_ BYTE12 : 96|8@1+ (1,0) [0|255] "" XXX
 SG_ BYTE13 : 104|8@1+ (1,0) [0|255] "" XXX
 SG_ BYTE14 : 112|8@1+ (1,0) [0|255] "" XXX
 SG_ BYTE15 : 120|8@1+ (1,0) [0|255] "" XXX
 SG_ BYTE16 : 128|8@1+ (1,0) [0|255] "" XXX
 SG_ BYTE17 : 136|8@1+ (1,0) [0|255] "" XXX
 SG_ BYTE18 : 144|8@1+ (1,0) [0|255] "" XXX
 SG_ BYTE19 : 152|8@1+ (1,0) [0|255] "" XXX
 SG_ BYTE20 : 160|8@1+ (1,0) [0|255] "" XXX
 SG_ BYTE21 : 168|8@1+ (1,0) [0|255] "" XXX
 SG_ BYTE22 : 176|8@1+ (1,0) [0|255] "" XXX
 SG_ BYTE23 : 184|8@1+ (1,0) [0|255] "" XXX
 SG_ BYTE24 : 192|8@1+ (1,0) [0|255] "" XXX
 SG_ BYTE25 : 200|8@1+ (1,0) [0|255] "" XXX
 SG_ BYTE26 : 208|8@1+ (1,0) [0|255] "" XXX
 SG_ BYTE27 : 216|8@1+ (1,0) [0|255] "" XXX
 SG_ BYTE28 : 224|8@1+ (1,0) [0|255] "" XXX
 SG_ BYTE29 : 232|8@1+ (1,0) [0|255] "" XXX
 SG_ BYTE30 : 240|8@1+ (1,0) [0|255] "" XXX
 SG_ BYTE31 : 248|8@1+ (1,0) [0|255] "" XXX

BO_ 579 HBA_0x243: 32 XXX
 SG_ BYTE0 : 0|8@1+ (1,0) [0|255] "" XXX
 SG_ BYTE1 : 8|8@1+ (1,0) [0|255] "" XXX
 SG_ BYTE2 : 16|8@1+ (1,0) [0|255] "" XXX
 SG_ BYTE3 : 24|8@1+ (1,0) [0|255] "" XXX
 SG_ BYTE4 : 32|8@1+ (1,0) [0|255] "" XXX
 SG_ BYTE5 : 40|8@1+ (1,0) [0|255] "" XXX
 SG_ BYTE6 : 48|8@1+ (1,0) [0|255] "" XXX
 SG_ BYTE7 : 56|8@1+ (1,0) [0|255] "" XXX
 SG_ BYTE8 : 64|8@1+ (1,0) [0|255] "" XXX
 SG_ BYTE9 : 72|8@1+ (1,0) [0|255] "" XXX
 SG_ BYTE10 : 80|8@1+ (1,0) [0|255] "" XXX
 SG_ BYTE11 : 88|8@1+ (1,0) [0|255] "" XXX
 SG_ BYTE12 : 96|8@1+ (1,0) [0|255] "" XXX
 SG_ BYTE13 : 104|8@1+ (1,0) [0|255] "" XXX
 SG_ BYTE14 : 112|8@1+ (1,0) [0|255] "" XXX
 SG_ BYTE15 : 120|8@1+ (1,0) [0|255] "" XXX
 SG_ BYTE16 : 128|8@1+ (1,0) [0|255] "" XXX
 SG_ BYTE17 : 136|8@1+ (1,0) [0|255] "" XXX
 SG_ BYTE18 : 144|8@1+ (1,0) [0|255] "" XXX
 SG_ BYTE19 : 152|8@1+ (1,0) [0|255] "" XXX
 SG_ BYTE20 : 160|8@1+ (1,0) [0|255] "" XXX
 SG_ BYTE21 : 168|8@1+ (1,0) [0|255] "" XXX
 SG_ BYTE22 : 176|8@1+ (1,0) [0|255] "" XXX
 SG_ BYTE23 : 184|8@1+ (1,0) [0|255] "" XXX
 SG_ BYTE24 : 192|8@1+ (1,0) [0|255] "" XXX
 SG_ BYTE25 : 200|8@1+ (1,0) [0|255] "" XXX
 SG_ BYTE26 : 208|8@1+ (1,0) [0|255] "" XXX
 SG_ BYTE27 : 216|8@1+ (1,0) [0|255] "" XXX
 SG_ BYTE28 : 224|8@1+ (1,0) [0|255] "" XXX
 SG_ BYTE29 : 232|8@1+ (1,0) [0|255] "" XXX
 SG_ BYTE30 : 240|8@1+ (1,0) [0|255] "" XXX
 SG_ BYTE31 : 248|8@1+ (1,0) [0|255] "" XXX

BO_ 580 HBA_0x244: 32 XXX
 SG_ BYTE0 : 0|8@1+ (1,0) [0|255] "" XXX
 SG_ BYTE1 : 8|8@1+ (1,0) [0|255] "" XXX
 SG_ BYTE2 : 16|8@1+ (1,0) [0|255] "" XXX
 SG_ BYTE3 : 24|8@1+ (1,0) [0|255] "" XXX
 SG_ BYTE4 : 32|8@1+ (1,0) [0|255] "" XXX
 SG_ BYTE5 : 40|8@1+ (1,0) [0|255] "" XXX
 SG_ BYTE6 : 48|8@1+ (1,0) [0|255] "" XXX
 SG_ BYTE7 : 56|8@1+ (1,0) [0|255] "" XXX
 SG_ BYTE8 : 64|8@1+ (1,0) [0|255] "" XXX
 SG_ BYTE9 : 72|8@1+ (1,0) [0|255] "" XXX
 SG_ BYTE10 : 80|8@1+ (1,0) [0|255] "" XXX
 SG_ BYTE11 : 88|8@1+ (1,0) [0|255] "" XXX
 SG_ BYTE12 : 96|8@1+ (1,0) [0|255] "" XXX
 SG_ BYTE13 : 104|8@1+ (1,0) [0|255] "" XXX
 SG_ BYTE14 : 112|8@1+ (1,0) [0|255] "" XXX
 SG_ BYTE15 : 120|8@1+ (1,0) [0|255] "" XXX
 SG_ BYTE16 : 128|8@1+ (1,0) [0|255] "" XXX
 SG_ BYTE17 : 136|8@1+ (1,0) [0|255] "" XXX
 SG_ BYTE18 : 144|8@1+ (1,0) [0|255] "" XXX
 SG_ BYTE19 : 152|8@1+ (1,0) [0|255] "" XXX
 SG_ BYTE20 : 160|8@1+ (1,0) [0|255] "" XXX
 SG_ BYTE21 : 168|8@1+ (1,0) [0|255] "" XXX
 SG_ BYTE22 : 176|8@1+ (1,0) [0|255] "" XXX
 SG_ BYTE23 : 184|8@1+ (1,0) [0|255] "" XXX
 SG_ BYTE24 : 192|8@1+ (1,0) [0|255] "" XXX
 SG_ BYTE25 : 200|8@1+ (1,0) [0|255] "" XXX
 SG_ BYTE26 : 208|8@1+ (1,0) [0|255] "" XXX
 SG_ BYTE27 : 216|8@1+ (1,0) [0|255] "" XXX
 SG_ BYTE28 : 224|8@1+ (1,0) [0|255] "" XXX
 SG_ BYTE29 : 232|8@1+ (1,0) [0|255] "" XXX
 SG_ BYTE30 : 240|8@1+ (1,0) [0|255] "" XXX
 SG_ BYTE31 : 248|8@1+ (1,0) [0|255] "" XXX

BO_ 581 HBA_0x245: 32 XXX
 SG_ BYTE0 : 0|8@1+ (1,0) [0|255] "" XXX
 SG_ BYTE1 : 8|8@1+ (1,0) [0|255] "" XXX
 SG_ BYTE2 : 16|8@1+ (1,0) [0|255] "" XXX
 SG_ BYTE3 : 24|8@1+ (1,0) [0|255] "" XXX
 SG_ BYTE4 : 32|8@1+ (1,0) [0|255] "" XXX
 SG_ BYTE5 : 40|8@1+ (1,0) [0|255] "" XXX
 SG_ BYTE6 : 48|8@1+ (1,0) [0|255] "" XXX
 SG_ BYTE7 : 56|8@1+ (1,0) [0|255] "" XXX
 SG_ BYTE8 : 64|8@1+ (1,0) [0|255] "" XXX
 SG_ BYTE9 : 72|8@1+ (1,0) [0|255] "" XXX
 SG_ BYTE10 : 80|8@1+ (1,0) [0|255] "" XXX
 SG_ BYTE11 : 88|8@1+ (1,0) [0|255] "" XXX
 SG_ BYTE12 : 96|8@1+ (1,0) [0|255] "" XXX
 SG_ BYTE13 : 104|8@1+ (1,0) [0|255] "" XXX
 SG_ BYTE14 : 112|8@1+ (1,0) [0|255] "" XXX
 SG_ BYTE15 : 120|8@1+ (1,0) [0|255] "" XXX
 SG_ BYTE16 : 128|8@1+ (1,0) [0|255] "" XXX
 SG_ BYTE17 : 136|8@1+ (1,0) [0|255] "" XXX
 SG_ BYTE18 : 144|8@1+ (1,0) [0|255] "" XXX
 SG_ BYTE19 : 152|8@1+ (1,0) [0|255] "" XXX
 SG_ BYTE20 : 160|8@1+ (1,0) [0|255] "" XXX
 SG_ BYTE21 : 168|8@1+ (1,0) [0|255] "" XXX
 SG_ BYTE22 : 176|8@1+ (1,0) [0|255] "" XXX
 SG_ BYTE23 : 184|8@1+ (1,0) [0|255] "" XXX
 SG_ BYTE24 : 192|8@1+ (1,0) [0|255] "" XXX
 SG_ BYTE25 : 200|8@1+ (1,0) [0|255] "" XXX
 SG_ BYTE26 : 208|8@1+ (1,0) [0|255] "" XXX
 SG_ BYTE27 : 216|8@1+ (1,0) [0|255] "" XXX
 SG_ BYTE28 : 224|8@1+ (1,0) [0|255] "" XXX
 SG_ BYTE29 : 232|8@1+ (1,0) [0|255] "" XXX
 SG_ BYTE30 : 240|8@1+ (1,0) [0|255] "" XXX
 SG_ BYTE31 : 248|8@1+ (1,0) [0|255] "" XXX

BO_ 582 HBA_0x246: 32 XXX
 SG_ BYTE0 : 0|8@1+ (1,0) [0|255] "" XXX
 SG_ BYTE1 : 8|8@1+ (1,0) [0|255] "" XXX
 SG_ BYTE2 : 16|8@1+ (1,0) [0|255] "" XXX
 SG_ BYTE3 : 24|8@1+ (1,0) [0|255] "" XXX
 SG_ BYTE4 : 32|8@1+ (1,0) [0|255] "" XXX
 SG_ BYTE5 : 40|8@1+ (1,0) [0|255] "" XXX
 SG_ BYTE6 : 48|8@1+ (1,0) [0|255] "" XXX
 SG_ BYTE7 : 56|8@1+ (1,0) [0|255] "" XXX
 SG_ BYTE8 : 64|8@1+ (1,0) [0|255] "" XXX
 SG_ BYTE9 : 72|8@1+ (1,0) [0|255] "" XXX
 SG_ BYTE10 : 80|8@1+ (1,0) [0|255] "" XXX
 SG_ BYTE11 : 88|8@1+ (1,0) [0|255] "" XXX
 SG_ BYTE12 : 96|8@1+ (1,0) [0|255] "" XXX
 SG_ BYTE13 : 104|8@1+ (1,0) [0|255] "" XXX
 SG_ BYTE14 : 112|8@1+ (1,0) [0|255] "" XXX
 SG_ BYTE15 : 120|8@1+ (1,0) [0|255] "" XXX
 SG_ BYTE16 : 128|8@1+ (1,0) [0|255] "" XXX
 SG_ BYTE17 : 136|8@1+ (1,0) [0|255] "" XXX
 SG_ BYTE18 : 144|8@1+ (1,0) [0|255] "" XXX
 SG_ BYTE19 : 152|8@1+ (1,0) [0|255] "" XXX
 SG_ BYTE20 : 160|8@1+ (1,0) [0|255] "" XXX
 SG_ BYTE21 : 168|8@1+ (1,0) [0|255] "" XXX
 SG_ BYTE22 : 176|8@1+ (1,0) [0|255] "" XXX
 SG_ BYTE23 : 184|8@1+ (1,0) [0|255] "" XXX
 SG_ BYTE24 : 192|8@1+ (1,0) [0|255] "" XXX
 SG_ BYTE25 : 200|8@1+ (1,0) [0|255] "" XXX
 SG_ BYTE26 : 208|8@1+ (1,0) [0|255] "" XXX
 SG_ BYTE27 : 216|8@1+ (1,0) [0|255] "" XXX
 SG_ BYTE28 : 224|8@1+ (1,0) [0|255] "" XXX
 SG_ BYTE29 : 232|8@1+ (1,0) [0|255] "" XXX
 SG_ BYTE30 : 240|8@1+ (1,0) [0|255] "" XXX
 SG_ BYTE31 : 248|8@1+ (1,0) [0|255] "" XXX

BO_ 583 HBA_0x247: 32 XXX
 SG_ BYTE0 : 0|8@1+ (1,0) [0|255] "" XXX
 SG_ BYTE1 : 8|8@1+ (1,0) [0|255] "" XXX
 SG_ BYTE2 : 16|8@1+ (1,0) [0|255] "" XXX
 SG_ BYTE3 : 24|8@1+ (1,0) [0|255] "" XXX
 SG_ BYTE4 : 32|8@1+ (1,0) [0|255] "" XXX
 SG_ BYTE5 : 40|8@1+ (1,0) [0|255] "" XXX
 SG_ BYTE6 : 48|8@1+ (1,0) [0|255] "" XXX
 SG_ BYTE7 : 56|8@1+ (1,0) [0|255] "" XXX
 SG_ BYTE8 : 64|8@1+ (1,0) [0|255] "" XXX
 SG_ BYTE9 : 72|8@1+ (1,0) [0|255] "" XXX
 SG_ BYTE10 : 80|8@1+ (1,0) [0|255] "" XXX
 SG_ BYTE11 : 88|8@1+ (1,0) [0|255] "" XXX
 SG_ BYTE12 : 96|8@1+ (1,0) [0|255] "" XXX
 SG_ BYTE13 : 104|8@1+ (1,0) [0|255] "" XXX
 SG_ BYTE14 : 112|8@1+ (1,0) [0|255] "" XXX
 SG_ BYTE15 : 120|8@1+ (1,0) [0|255] "" XXX
 SG_ BYTE16 : 128|8@1+ (1,0) [0|255] "" XXX
 SG_ BYTE17 : 136|8@1+ (1,0) [0|255] "" XXX
 SG_ BYTE18 : 144|8@1+ (1,0) [0|255] "" XXX
 SG_ BYTE19 : 152|8@1+ (1,0) [0|255] "" XXX
 SG_ BYTE20 : 160|8@1+ (1,0) [0|255] "" XXX
 SG_ BYTE21 : 168|8@1+ (1,0) [0|255] "" XXX
 SG_ BYTE22 : 176|8@1+ (1,0) [0|255] "" XXX
 SG_ BYTE23 : 184|8@1+ (1,0) [0|255] "" XXX
 SG_ BYTE24 : 192|8@1+ (1,0) [0|255] "" XXX
 SG_ BYTE25 : 200|8@1+ (1,0) [0|255] "" XXX
 SG_ BYTE26 : 208|8@1+ (1,0) [0|255] "" XXX
 SG_ BYTE27 : 216|8@1+ (1,0) [0|255] "" XXX
 SG_ BYTE28 : 224|8@1+ (1,0) [0|255] "" XXX
 SG_ BYTE29 : 232|8@1+ (1,0) [0|255] "" XXX
 SG_ BYTE30 : 240|8@1+ (1,0) [0|255] "" XXX
 SG_ BYTE31 : 248|8@1+ (1,0) [0|255] "" XXX

BO_ 584 HBA_0x248: 32 XXX
 SG_ BYTE0 : 0|8@1+ (1,0) [0|255] "" XXX
 SG_ BYTE1 : 8|8@1+ (1,0) [0|255] "" XXX
 SG_ BYTE2 : 16|8@1+ (1,0) [0|255] "" XXX
 SG_ BYTE3 : 24|8@1+ (1,0) [0|255] "" XXX
 SG_ BYTE4 : 32|8@1+ (1,0) [0|255] "" XXX
 SG_ BYTE5 : 40|8@1+ (1,0) [0|255] "" XXX
 SG_ BYTE6 : 48|8@1+ (1,0) [0|255] "" XXX
 SG_ BYTE7 : 56|8@1+ (1,0) [0|255] "" XXX
 SG_ BYTE8 : 64|8@1+ (1,0) [0|255] "" XXX
 SG_ BYTE9 : 72|8@1+ (1,0) [0|255] "" XXX
 SG_ BYTE10 : 80|8@1+ (1,0) [0|255] "" XXX
 SG_ BYTE11 : 88|8@1+ (1,0) [0|255] "" XXX
 SG_ BYTE12 : 96|8@1+ (1,0) [0|255] "" XXX
 SG_ BYTE13 : 104|8@1+ (1,0) [0|255] "" XXX
 SG_ BYTE14 : 112|8@1+ (1,0) [0|255] "" XXX
 SG_ BYTE15 : 120|8@1+ (1,0) [0|255] "" XXX
 SG_ BYTE16 : 128|8@1+ (1,0) [0|255] "" XXX
 SG_ BYTE17 : 136|8@1+ (1,0) [0|255] "" XXX
 SG_ BYTE18 : 144|8@1+ (1,0) [0|255] "" XXX
 SG_ BYTE19 : 152|8@1+ (1,0) [0|255] "" XXX
 SG_ BYTE20 : 160|8@1+ (1,0) [0|255] "" XXX
 SG_ BYTE21 : 168|8@1+ (1,0) [0|255] "" XXX
 SG_ BYTE22 : 176|8@1+ (1,0) [0|255] "" XXX
 SG_ BYTE23 : 184|8@1+ (1,0) [0|255] "" XXX
 SG_ BYTE24 : 192|8@1+ (1,0) [0|255] "" XXX
 SG_ BYTE25 : 200|8@1+ (1,0) [0|255] "" XXX
 SG_ BYTE26 : 208|8@1+ (1,0) [0|255] "" XXX
 SG_ BYTE27 : 216|8@1+ (1,0) [0|255] "" XXX
 SG_ BYTE28 : 224|8@1+ (1,0) [0|255] "" XXX
 SG_ BYTE29 : 232|8@1+ (1,0) [0|255] "" XXX
 SG_ BYTE30 : 240|8@1+ (1,0) [0|255] "" XXX
 SG_ BYTE31 : 248|8@1+ (1,0) [0|255] "" XXX

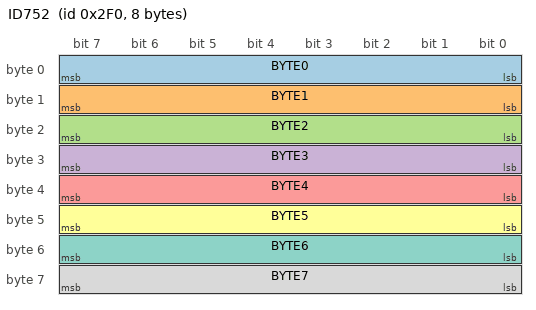
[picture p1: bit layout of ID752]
BO_ 752 ID752: 8 XXX
 SG_ BYTE0 : 0|8@1+ (1,0) [0|255] "" XXX
 SG_ BYTE1 : 8|8@1+ (1,0) [0|255] "" XXX
 SG_ BYTE2 : 16|8@1+ (1,0) [0|255] "" XXX
 SG_ BYTE3 : 24|8@1+ (1,0) [0|255] "" XXX
 SG_ BYTE4 : 32|8@1+ (1,0) [0|255] "" XXX
 SG_ BYTE5 : 40|8@1+ (1,0) [0|255] "" XXX
 SG_ BYTE6 : 48|8@1+ (1,0) [0|255] "" XXX
 SG_ BYTE7 : 56|8@1+ (1,0) [0|255] "" XXX

BO_ 865 ID865: 32 XXX
 SG_ BYTE0 : 0|8@1+ (1,0) [0|255] "" XXX
 SG_ BYTE1 : 8|8@1+ (1,0) [0|255] "" XXX
 SG_ BYTE2 : 16|8@1+ (1,0) [0|255] "" XXX
 SG_ BYTE3 : 24|8@1+ (1,0) [0|255] "" XXX
 SG_ BYTE4 : 32|8@1+ (1,0) [0|255] "" XXX
 SG_ BYTE5 : 40|8@1+ (1,0) [0|255] "" XXX
 SG_ BYTE6 : 48|8@1+ (1,0) [0|255] "" XXX
 SG_ BYTE7 : 56|8@1+ (1,0) [0|255] "" XXX
 SG_ BYTE8 : 64|8@1+ (1,0) [0|255] "" XXX
 SG_ BYTE9 : 72|8@1+ (1,0) [0|255] "" XXX
 SG_ BYTE10 : 80|8@1+ (1,0) [0|255] "" XXX
 SG_ BYTE11 : 88|8@1+ (1,0) [0|255] "" XXX
 SG_ BYTE12 : 96|8@1+ (1,0) [0|255] "" XXX
 SG_ BYTE13 : 104|8@1+ (1,0) [0|255] "" XXX
 SG_ BYTE14 : 112|8@1+ (1,0) [0|255] "" XXX
 SG_ BYTE15 : 120|8@1+ (1,0) [0|255] "" XXX
 SG_ BYTE16 : 128|8@1+ (1,0) [0|255] "" XXX
 SG_ BYTE17 : 136|8@1+ (1,0) [0|255] "" XXX
 SG_ BYTE18 : 144|8@1+ (1,0) [0|255] "" XXX
 SG_ BYTE19 : 152|8@1+ (1,0) [0|255] "" XXX
 SG_ BYTE20 : 160|8@1+ (1,0) [0|255] "" XXX
 SG_ BYTE21 : 168|8@1+ (1,0) [0|255] "" XXX
 SG_ BYTE22 : 176|8@1+ (1,0) [0|255] "" XXX
 SG_ BYTE23 : 184|8@1+ (1,0) [0|255] "" XXX
 SG_ BYTE24 : 192|8@1+ (1,0) [0|255] "" XXX
 SG_ BYTE25 : 200|8@1+ (1,0) [0|255] "" XXX
 SG_ BYTE26 : 208|8@1+ (1,0) [0|255] "" XXX
 SG_ BYTE27 : 216|8@1+ (1,0) [0|255] "" XXX
 SG_ BYTE28 : 224|8@1+ (1,0) [0|255] "" XXX
 SG_ BYTE29 : 232|8@1+ (1,0) [0|255] "" XXX
 SG_ BYTE30 : 240|8@1+ (1,0) [0|255] "" XXX
 SG_ BYTE31 : 248|8@1+ (1,0) [0|255] "" XXX

BO_ 917 ID917: 32 XXX
 SG_ BYTE0 : 0|8@1+ (1,0) [0|255] "" XXX
 SG_ BYTE1 : 8|8@1+ (1,0) [0|255] "" XXX
 SG_ BYTE2 : 16|8@1+ (1,0) [0|255] "" XXX
 SG_ BYTE3 : 24|8@1+ (1,0) [0|255] "" XXX
 SG_ BYTE4 : 32|8@1+ (1,0) [0|255] "" XXX
 SG_ BYTE5 : 40|8@1+ (1,0) [0|255] "" XXX
 SG_ BYTE6 : 48|8@1+ (1,0) [0|255] "" XXX
 SG_ BYTE7 : 56|8@1+ (1,0) [0|255] "" XXX
 SG_ BYTE8 : 64|8@1+ (1,0) [0|255] "" XXX
 SG_ BYTE9 : 72|8@1+ (1,0) [0|255] "" XXX
 SG_ BYTE10 : 80|8@1+ (1,0) [0|255] "" XXX
 SG_ BYTE11 : 88|8@1+ (1,0) [0|255] "" XXX
 SG_ BYTE12 : 96|8@1+ (1,0) [0|255] "" XXX
 SG_ BYTE13 : 104|8@1+ (1,0) [0|255] "" XXX
 SG_ BYTE14 : 112|8@1+ (1,0) [0|255] "" XXX
 SG_ BYTE15 : 120|8@1+ (1,0) [0|255] "" XXX
 SG_ BYTE16 : 128|8@1+ (1,0) [0|255] "" XXX
 SG_ BYTE17 : 136|8@1+ (1,0) [0|255] "" XXX
 SG_ BYTE18 : 144|8@1+ (1,0) [0|255] "" XXX
 SG_ BYTE19 : 152|8@1+ (1,0) [0|255] "" XXX
 SG_ BYTE20 : 160|8@1+ (1,0) [0|255] "" XXX
 SG_ BYTE21 : 168|8@1+ (1,0) [0|255] "" XXX
 SG_ BYTE22 : 176|8@1+ (1,0) [0|255] "" XXX
 SG_ BYTE23 : 184|8@1+ (1,0) [0|255] "" XXX
 SG_ BYTE24 : 192|8@1+ (1,0) [0|255] "" XXX
 SG_ BYTE25 : 200|8@1+ (1,0) [0|255] "" XXX
 SG_ BYTE26 : 208|8@1+ (1,0) [0|255] "" XXX
 SG_ BYTE27 : 216|8@1+ (1,0) [0|255] "" XXX
 SG_ BYTE28 : 224|8@1+ (1,0) [0|255] "" XXX
 SG_ BYTE29 : 232|8@1+ (1,0) [0|255] "" XXX
 SG_ BYTE30 : 240|8@1+ (1,0) [0|255] "" XXX
 SG_ BYTE31 : 248|8@1+ (1,0) [0|255] "" XXX

BO_ 928 ID928: 32 XXX
 SG_ BYTE0 : 0|8@1+ (1,0) [0|255] "" XXX
 SG_ BYTE1 : 8|8@1+ (1,0) [0|255] "" XXX
 SG_ BYTE2 : 16|8@1+ (1,0) [0|255] "" XXX
 SG_ BYTE3 : 24|8@1+ (1,0) [0|255] "" XXX
 SG_ BYTE4 : 32|8@1+ (1,0) [0|255] "" XXX
 SG_ BYTE5 : 40|8@1+ (1,0) [0|255] "" XXX
 SG_ BYTE6 : 48|8@1+ (1,0) [0|255] "" XXX
 SG_ BYTE7 : 56|8@1+ (1,0) [0|255] "" XXX
 SG_ BYTE8 : 64|8@1+ (1,0) [0|255] "" XXX
 SG_ BYTE9 : 72|8@1+ (1,0) [0|255] "" XXX
 SG_ BYTE10 : 80|8@1+ (1,0) [0|255] "" XXX
 SG_ BYTE11 : 88|8@1+ (1,0) [0|255] "" XXX
 SG_ BYTE12 : 96|8@1+ (1,0) [0|255] "" XXX
 SG_ BYTE13 : 104|8@1+ (1,0) [0|255] "" XXX
 SG_ BYTE14 : 112|8@1+ (1,0) [0|255] "" XXX
 SG_ BYTE15 : 120|8@1+ (1,0) [0|255] "" XXX
 SG_ BYTE16 : 128|8@1+ (1,0) [0|255] "" XXX
 SG_ BYTE17 : 136|8@1+ (1,0) [0|255] "" XXX
 SG_ BYTE18 : 144|8@1+ (1,0) [0|255] "" XXX
 SG_ BYTE19 : 152|8@1+ (1,0) [0|255] "" XXX
 SG_ BYTE20 : 160|8@1+ (1,0) [0|255] "" XXX
 SG_ BYTE21 : 168|8@1+ (1,0) [0|255] "" XXX
 SG_ BYTE22 : 176|8@1+ (1,0) [0|255] "" XXX
 SG_ BYTE23 : 184|8@1+ (1,0) [0|255] "" XXX
 SG_ BYTE24 : 192|8@1+ (1,0) [0|255] "" XXX
 SG_ BYTE25 : 200|8@1+ (1,0) [0|255] "" XXX
 SG_ BYTE26 : 208|8@1+ (1,0) [0|255] "" XXX
 SG_ BYTE27 : 216|8@1+ (1,0) [0|255] "" XXX
 SG_ BYTE28 : 224|8@1+ (1,0) [0|255] "" XXX
 SG_ BYTE29 : 232|8@1+ (1,0) [0|255] "" XXX
 SG_ BYTE30 : 240|8@1+ (1,0) [0|255] "" XXX
 SG_ BYTE31 : 248|8@1+ (1,0) [0|255] "" XXX

BO_ 977 ID977: 32 XXX
 SG_ BYTE0 : 0|8@1+ (1,0) [0|255] "" XXX
 SG_ BYTE1 : 8|8@1+ (1,0) [0|255] "" XXX
 SG_ BYTE2 : 16|8@1+ (1,0) [0|255] "" XXX
 SG_ BYTE3 : 24|8@1+ (1,0) [0|255] "" XXX
 SG_ BYTE4 : 32|8@1+ (1,0) [0|255] "" XXX
 SG_ BYTE5 : 40|8@1+ (1,0) [0|255] "" XXX
 SG_ BYTE6 : 48|8@1+ (1,0) [0|255] "" XXX
 SG_ BYTE7 : 56|8@1+ (1,0) [0|255] "" XXX
 SG_ BYTE8 : 64|8@1+ (1,0) [0|255] "" XXX
 SG_ BYTE9 : 72|8@1+ (1,0) [0|255] "" XXX
 SG_ BYTE10 : 80|8@1+ (1,0) [0|255] "" XXX
 SG_ BYTE11 : 88|8@1+ (1,0) [0|255] "" XXX
 SG_ BYTE12 : 96|8@1+ (1,0) [0|255] "" XXX
 SG_ BYTE13 : 104|8@1+ (1,0) [0|255] "" XXX
 SG_ BYTE14 : 112|8@1+ (1,0) [0|255] "" XXX
 SG_ BYTE15 : 120|8@1+ (1,0) [0|255] "" XXX
 SG_ BYTE16 : 128|8@1+ (1,0) [0|255] "" XXX
 SG_ BYTE17 : 136|8@1+ (1,0) [0|255] "" XXX
 SG_ BYTE18 : 144|8@1+ (1,0) [0|255] "" XXX
 SG_ BYTE19 : 152|8@1+ (1,0) [0|255] "" XXX
 SG_ BYTE20 : 160|8@1+ (1,0) [0|255] "" XXX
 SG_ BYTE21 : 168|8@1+ (1,0) [0|255] "" XXX
 SG_ BYTE22 : 176|8@1+ (1,0) [0|255] "" XXX
 SG_ BYTE23 : 184|8@1+ (1,0) [0|255] "" XXX
 SG_ BYTE24 : 192|8@1+ (1,0) [0|255] "" XXX
 SG_ BYTE25 : 200|8@1+ (1,0) [0|255] "" XXX
 SG_ BYTE26 : 208|8@1+ (1,0) [0|255] "" XXX
 SG_ BYTE27 : 216|8@1+ (1,0) [0|255] "" XXX
 SG_ BYTE28 : 224|8@1+ (1,0) [0|255] "" XXX
 SG_ BYTE29 : 232|8@1+ (1,0) [0|255] "" XXX
 SG_ BYTE30 : 240|8@1+ (1,0) [0|255] "" XXX
 SG_ BYTE31 : 248|8@1+ (1,0) [0|255] "" XXX

BO_ 978 ID978: 32 XXX
 SG_ BYTE0 : 0|8@1+ (1,0) [0|255] "" XXX
 SG_ BYTE1 : 8|8@1+ (1,0) [0|255] "" XXX
 SG_ BYTE2 : 16|8@1+ (1,0) [0|255] "" XXX
 SG_ BYTE3 : 24|8@1+ (1,0) [0|255] "" XXX
 SG_ BYTE4 : 32|8@1+ (1,0) [0|255] "" XXX
 SG_ BYTE5 : 40|8@1+ (1,0) [0|255] "" XXX
 SG_ BYTE6 : 48|8@1+ (1,0) [0|255] "" XXX
 SG_ BYTE7 : 56|8@1+ (1,0) [0|255] "" XXX
 SG_ BYTE8 : 64|8@1+ (1,0) [0|255] "" XXX
 SG_ BYTE9 : 72|8@1+ (1,0) [0|255] "" XXX
 SG_ BYTE10 : 80|8@1+ (1,0) [0|255] "" XXX
 SG_ BYTE11 : 88|8@1+ (1,0) [0|255] "" XXX
 SG_ BYTE12 : 96|8@1+ (1,0) [0|255] "" XXX
 SG_ BYTE13 : 104|8@1+ (1,0) [0|255] "" XXX
 SG_ BYTE14 : 112|8@1+ (1,0) [0|255] "" XXX
 SG_ BYTE15 : 120|8@1+ (1,0) [0|255] "" XXX
 SG_ BYTE16 : 128|8@1+ (1,0) [0|255] "" XXX
 SG_ BYTE17 : 136|8@1+ (1,0) [0|255] "" XXX
 SG_ BYTE18 : 144|8@1+ (1,0) [0|255] "" XXX
 SG_ BYTE19 : 152|8@1+ (1,0) [0|255] "" XXX
 SG_ BYTE20 : 160|8@1+ (1,0) [0|255] "" XXX
 SG_ BYTE21 : 168|8@1+ (1,0) [0|255] "" XXX
 SG_ BYTE22 : 176|8@1+ (1,0) [0|255] "" XXX
 SG_ BYTE23 : 184|8@1+ (1,0) [0|255] "" XXX
 SG_ BYTE24 : 192|8@1+ (1,0) [0|255] "" XXX
 SG_ BYTE25 : 200|8@1+ (1,0) [0|255] "" XXX
 SG_ BYTE26 : 208|8@1+ (1,0) [0|255] "" XXX
 SG_ BYTE27 : 216|8@1+ (1,0) [0|255] "" XXX
 SG_ BYTE28 : 224|8@1+ (1,0) [0|255] "" XXX
 SG_ BYTE29 : 232|8@1+ (1,0) [0|255] "" XXX
 SG_ BYTE30 : 240|8@1+ (1,0) [0|255] "" XXX
 SG_ BYTE31 : 248|8@1+ (1,0) [0|255] "" XXX

BO_ 980 ID980: 32 XXX
 SG_ BYTE0 : 0|8@1+ (1,0) [0|255] "" XXX
 SG_ BYTE1 : 8|8@1+ (1,0) [0|255] "" XXX
 SG_ BYTE2 : 16|8@1+ (1,0) [0|255] "" XXX
 SG_ BYTE3 : 24|8@1+ (1,0) [0|255] "" XXX
 SG_ BYTE4 : 32|8@1+ (1,0) [0|255] "" XXX
 SG_ BYTE5 : 40|8@1+ (1,0) [0|255] "" XXX
 SG_ BYTE6 : 48|8@1+ (1,0) [0|255] "" XXX
 SG_ BYTE7 : 56|8@1+ (1,0) [0|255] "" XXX
 SG_ BYTE8 : 64|8@1+ (1,0) [0|255] "" XXX
 SG_ BYTE9 : 72|8@1+ (1,0) [0|255] "" XXX
 SG_ BYTE10 : 80|8@1+ (1,0) [0|255] "" XXX
 SG_ BYTE11 : 88|8@1+ (1,0) [0|255] "" XXX
 SG_ BYTE12 : 96|8@1+ (1,0) [0|255] "" XXX
 SG_ BYTE13 : 104|8@1+ (1,0) [0|255] "" XXX
 SG_ BYTE14 : 112|8@1+ (1,0) [0|255] "" XXX
 SG_ BYTE15 : 120|8@1+ (1,0) [0|255] "" XXX
 SG_ BYTE16 : 128|8@1+ (1,0) [0|255] "" XXX
 SG_ BYTE17 : 136|8@1+ (1,0) [0|255] "" XXX
 SG_ BYTE18 : 144|8@1+ (1,0) [0|255] "" XXX
 SG_ BYTE19 : 152|8@1+ (1,0) [0|255] "" XXX
 SG_ BYTE20 : 160|8@1+ (1,0) [0|255] "" XXX
 SG_ BYTE21 : 168|8@1+ (1,0) [0|255] "" XXX
 SG_ BYTE22 : 176|8@1+ (1,0) [0|255] "" XXX
 SG_ BYTE23 : 184|8@1+ (1,0) [0|255] "" XXX
 SG_ BYTE24 : 192|8@1+ (1,0) [0|255] "" XXX
 SG_ BYTE25 : 200|8@1+ (1,0) [0|255] "" XXX
 SG_ BYTE26 : 208|8@1+ (1,0) [0|255] "" XXX
 SG_ BYTE27 : 216|8@1+ (1,0) [0|255] "" XXX
 SG_ BYTE28 : 224|8@1+ (1,0) [0|255] "" XXX
 SG_ BYTE29 : 232|8@1+ (1,0) [0|255] "" XXX
 SG_ BYTE30 : 240|8@1+ (1,0) [0|255] "" XXX
 SG_ BYTE31 : 248|8@1+ (1,0) [0|255] "" XXX

BO_ 1280 ID1280: 16 XXX
 SG_ BYTE0 : 0|8@1+ (1,0) [0|255] "" XXX
 SG_ BYTE1 : 8|8@1+ (1,0) [0|255] "" XXX
 SG_ BYTE2 : 16|8@1+ (1,0) [0|255] "" XXX
 SG_ BYTE3 : 24|8@1+ (1,0) [0|255] "" XXX
 SG_ BYTE4 : 32|8@1+ (1,0) [0|255] "" XXX
 SG_ BYTE5 : 40|8@1+ (1,0) [0|255] "" XXX
 SG_ BYTE6 : 48|8@1+ (1,0) [0|255] "" XXX
 SG_ BYTE7 : 56|8@1+ (1,0) [0|255] "" XXX
 SG_ BYTE8 : 64|8@1+ (1,0) [0|255] "" XXX
 SG_ BYTE9 : 72|8@1+ (1,0) [0|255] "" XXX
 SG_ BYTE10 : 80|8@1+ (1,0) [0|255] "" XXX
 SG_ BYTE11 : 88|8@1+ (1,0) [0|255] "" XXX
 SG_ BYTE12 : 96|8@1+ (1,0) [0|255] "" XXX
 SG_ BYTE13 : 104|8@1+ (1,0) [0|255] "" XXX
 SG_ BYTE14 : 112|8@1+ (1,0) [0|255] "" XXX
 SG_ BYTE15 : 120|8@1+ (1,0) [0|255] "" XXX

BO_ 811 ADRV_0x32b: 32 XXX
 SG_ BYTE0 : 0|8@1+ (1,0) [0|255] "" XXX
 SG_ BYTE1 : 8|8@1+ (1,0) [0|255] "" XXX
 SG_ BYTE2 : 16|8@1+ (1,0) [0|255] "" XXX
 SG_ BYTE3 : 24|8@1+ (1,0) [0|255] "" XXX
 SG_ BYTE4 : 32|8@1+ (1,0) [0|255] "" XXX
 SG_ BYTE5 : 40|8@1+ (1,0) [0|255] "" XXX
 SG_ BYTE6 : 48|8@1+ (1,0) [0|255] "" XXX
 SG_ BYTE7 : 56|8@1+ (1,0) [0|255] "" XXX
 SG_ BYTE8 : 64|8@1+ (1,0) [0|255] "" XXX
 SG_ BYTE9 : 72|8@1+ (1,0) [0|255] "" XXX
 SG_ BYTE10 : 80|8@1+ (1,0) [0|255] "" XXX
 SG_ BYTE11 : 88|8@1+ (1,0) [0|255] "" XXX
 SG_ BYTE12 : 96|8@1+ (1,0) [0|255] "" XXX
 SG_ BYTE13 : 104|8@1+ (1,0) [0|255] "" XXX
 SG_ BYTE14 : 112|8@1+ (1,0) [0|255] "" XXX
 SG_ BYTE15 : 120|8@1+ (1,0) [0|255] "" XXX
 SG_ BYTE16 : 128|8@1+ (1,0) [0|255] "" XXX
 SG_ BYTE17 : 136|8@1+ (1,0) [0|255] "" XXX
 SG_ BYTE18 : 144|8@1+ (1,0) [0|255] "" XXX
 SG_ BYTE19 : 152|8@1+ (1,0) [0|255] "" XXX
 SG_ BYTE20 : 160|8@1+ (1,0) [0|255] "" XXX
 SG_ BYTE21 : 168|8@1+ (1,0) [0|255] "" XXX
 SG_ BYTE22 : 176|8@1+ (1,0) [0|255] "" XXX
 SG_ BYTE23 : 184|8@1+ (1,0) [0|255] "" XXX
 SG_ BYTE24 : 192|8@1+ (1,0) [0|255] "" XXX
 SG_ BYTE25 : 200|8@1+ (1,0) [0|255] "" XXX
 SG_ BYTE26 : 208|8@1+ (1,0) [0|255] "" XXX
 SG_ BYTE27 : 216|8@1+ (1,0) [0|255] "" XXX
 SG_ BYTE28 : 224|8@1+ (1,0) [0|255] "" XXX
 SG_ BYTE29 : 232|8@1+ (1,0) [0|255] "" XXX
 SG_ BYTE30 : 240|8@1+ (1,0) [0|255] "" XXX
 SG_ BYTE31 : 248|8@1+ (1,0) [0|255] "" XXX

BO_ 813 ADRV_0x32d: 32 XXX
 SG_ BYTE0 : 0|8@1+ (1,0) [0|255] "" XXX
 SG_ BYTE1 : 8|8@1+ (1,0) [0|255] "" XXX
 SG_ BYTE2 : 16|8@1+ (1,0) [0|255] "" XXX
 SG_ BYTE3 : 24|8@1+ (1,0) [0|255] "" XXX
 SG_ BYTE4 : 32|8@1+ (1,0) [0|255] "" XXX
 SG_ BYTE5 : 40|8@1+ (1,0) [0|255] "" XXX
 SG_ BYTE6 : 48|8@1+ (1,0) [0|255] "" XXX
 SG_ BYTE7 : 56|8@1+ (1,0) [0|255] "" XXX
 SG_ BYTE8 : 64|8@1+ (1,0) [0|255] "" XXX
 SG_ BYTE9 : 72|8@1+ (1,0) [0|255] "" XXX
 SG_ BYTE10 : 80|8@1+ (1,0) [0|255] "" XXX
 SG_ BYTE11 : 88|8@1+ (1,0) [0|255] "" XXX
 SG_ BYTE12 : 96|8@1+ (1,0) [0|255] "" XXX
 SG_ BYTE13 : 104|8@1+ (1,0) [0|255] "" XXX
 SG_ BYTE14 : 112|8@1+ (1,0) [0|255] "" XXX
 SG_ BYTE15 : 120|8@1+ (1,0) [0|255] "" XXX
 SG_ BYTE16 : 128|8@1+ (1,0) [0|255] "" XXX
 SG_ BYTE17 : 136|8@1+ (1,0) [0|255] "" XXX
 SG_ BYTE18 : 144|8@1+ (1,0) [0|255] "" XXX
 SG_ BYTE19 : 152|8@1+ (1,0) [0|255] "" XXX
 SG_ BYTE20 : 160|8@1+ (1,0) [0|255] "" XXX
 SG_ BYTE21 : 168|8@1+ (1,0) [0|255] "" XXX
 SG_ BYTE22 : 176|8@1+ (1,0) [0|255] "" XXX
 SG_ BYTE23 : 184|8@1+ (1,0) [0|255] "" XXX
 SG_ BYTE24 : 192|8@1+ (1,0) [0|255] "" XXX
 SG_ BYTE25 : 200|8@1+ (1,0) [0|255] "" XXX
 SG_ BYTE26 : 208|8@1+ (1,0) [0|255] "" XXX
 SG_ BYTE27 : 216|8@1+ (1,0) [0|255] "" XXX
 SG_ BYTE28 : 224|8@1+ (1,0) [0|255] "" XXX
 SG_ BYTE29 : 232|8@1+ (1,0) [0|255] "" XXX
 SG_ BYTE30 : 240|8@1+ (1,0) [0|255] "" XXX
 SG_ BYTE31 : 248|8@1+ (1,0) [0|255] "" XXX

BO_ 816 ADRV_0x330: 32 XXX
 SG_ BYTE0 : 0|8@1+ (1,0) [0|255] "" XXX
 SG_ BYTE1 : 8|8@1+ (1,0) [0|255] "" XXX
 SG_ BYTE2 : 16|8@1+ (1,0) [0|255] "" XXX
 SG_ BYTE3 : 24|8@1+ (1,0) [0|255] "" XXX
 SG_ BYTE4 : 32|8@1+ (1,0) [0|255] "" XXX
 SG_ BYTE5 : 40|8@1+ (1,0) [0|255] "" XXX
 SG_ BYTE6 : 48|8@1+ (1,0) [0|255] "" XXX
 SG_ BYTE7 : 56|8@1+ (1,0) [0|255] "" XXX
 SG_ BYTE8 : 64|8@1+ (1,0) [0|255] "" XXX
 SG_ BYTE9 : 72|8@1+ (1,0) [0|255] "" XXX
 SG_ BYTE10 : 80|8@1+ (1,0) [0|255] "" XXX
 SG_ BYTE11 : 88|8@1+ (1,0) [0|255] "" XXX
 SG_ BYTE12 : 96|8@1+ (1,0) [0|255] "" XXX
 SG_ BYTE13 : 104|8@1+ (1,0) [0|255] "" XXX
 SG_ BYTE14 : 112|8@1+ (1,0) [0|255] "" XXX
 SG_ BYTE15 : 120|8@1+ (1,0) [0|255] "" XXX
 SG_ BYTE16 : 128|8@1+ (1,0) [0|255] "" XXX
 SG_ BYTE17 : 136|8@1+ (1,0) [0|255] "" XXX
 SG_ BYTE18 : 144|8@1+ (1,0) [0|255] "" XXX
 SG_ BYTE19 : 152|8@1+ (1,0) [0|255] "" XXX
 SG_ BYTE20 : 160|8@1+ (1,0) [0|255] "" XXX
 SG_ BYTE21 : 168|8@1+ (1,0) [0|255] "" XXX
 SG_ BYTE22 : 176|8@1+ (1,0) [0|255] "" XXX
 SG_ BYTE23 : 184|8@1+ (1,0) [0|255] "" XXX
 SG_ BYTE24 : 192|8@1+ (1,0) [0|255] "" XXX
 SG_ BYTE25 : 200|8@1+ (1,0) [0|255] "" XXX
 SG_ BYTE26 : 208|8@1+ (1,0) [0|255] "" XXX
 SG_ BYTE27 : 216|8@1+ (1,0) [0|255] "" XXX
 SG_ BYTE28 : 224|8@1+ (1,0) [0|255] "" XXX
 SG_ BYTE29 : 232|8@1+ (1,0) [0|255] "" XXX
 SG_ BYTE30 : 240|8@1+ (1,0) [0|255] "" XXX
 SG_ BYTE31 : 248|8@1+ (1,0) [0|255] "" XXX
